VERSION "HNNBNNNYNNNNNNNNNNNNNNNNNNNNNNNNNNNNNNNNNN/4/%%%/4/'%**4NNN///"

NS_ :

BS_:

BU_: AFS Airbag Allrad BAP_Tester BMS_Hybrid Bremse_MK60EC Bremse_MK70MABS Bremse_TRW_EBC450M Bremse_TRW_ESP Daempfer EPB_TRW EPB_TRW_VW411CS FLA Gateway_PQ35 Gateway_Zusatz_EGolf Getriebe_AG6 Getriebe_DQ Getriebe_DQ_Hyb Getriebe_Sele Gurtmikro_PQ35 HCA Ladegeraet_EGolf LEH_Hybrid LH_EPS_APA LH_EPS_ZF_2G LH_EPS_ZF_3G LPG_Interface_Box LWR LWS Magne_Ride Motor_Diesel Motor_EGolf Motor_Hybrid Motor_Otto PDC_PLA Quersperre_VAQ RKA_Plus SAK Waehlhebel Waehlhebel_Sele

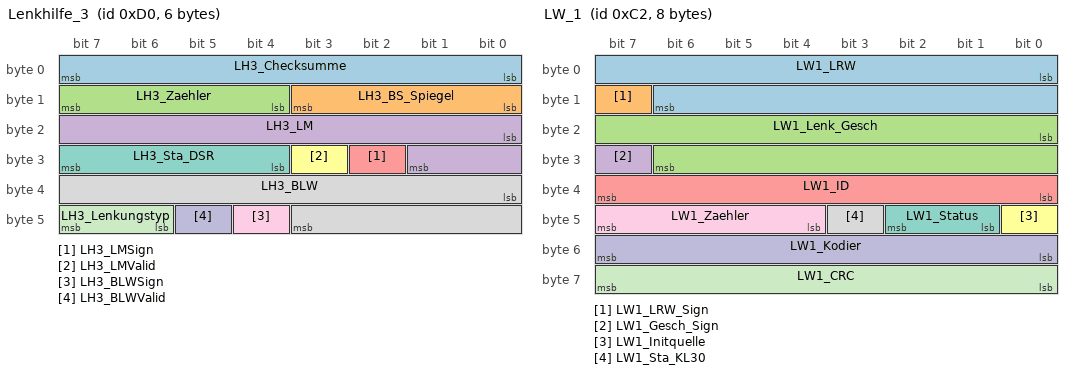
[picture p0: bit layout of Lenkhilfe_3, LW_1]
BO_ 208 Lenkhilfe_3: 6 LH_EPS_APA
 SG_ LH3_Checksumme : 0|8@1+ (1,0) [0|255] ""  Bremse_MK60EC,Bremse_MK70MABS,Bremse_TRW_EBC450M,Bremse_TRW_ESP,Gateway_PQ35,HCA,PDC_PLA
 SG_ LH3_BS_Spiegel : 8|4@1+ (1,0) [0|15] ""  Gateway_PQ35
 SG_ LH3_Zaehler : 12|4@1+ (1,0) [0|15] ""  Bremse_MK60EC,Bremse_MK70MABS,Bremse_TRW_EBC450M,Bremse_TRW_ESP,Gateway_PQ35,HCA,PDC_PLA
 SG_ LH3_LM : 16|10@1+ (0.0147,0) [0|15.0381] "Unit_NewtoMeter"  Bremse_MK60EC,Bremse_MK70MABS,Bremse_TRW_EBC450M,Bremse_TRW_ESP,Gateway_PQ35,HCA,Motor_Diesel,Motor_Otto,PDC_PLA
 SG_ LH3_LMSign : 26|1@1+ (1,0) [0|1] ""  Bremse_MK60EC,Bremse_MK70MABS,Bremse_TRW_EBC450M,Bremse_TRW_ESP,Gateway_PQ35,HCA,Motor_Diesel,Motor_Otto,PDC_PLA
 SG_ LH3_LMValid : 27|1@1+ (1,0) [0|1] ""  Bremse_MK60EC,Bremse_MK70MABS,Bremse_TRW_EBC450M,Bremse_TRW_ESP,Gateway_PQ35,HCA,Motor_Diesel,Motor_Otto,PDC_PLA
 SG_ LH3_Sta_DSR : 28|4@1+ (1,0) [0|15] ""  Bremse_MK60EC,Bremse_MK70MABS,Bremse_TRW_EBC450M,Bremse_TRW_ESP,Gateway_PQ35
 SG_ LH3_BLW : 32|12@1+ (0.15,0) [0|614.25] "Unit_DegreOfArc"  Bremse_MK60EC,Bremse_MK70MABS,Bremse_TRW_EBC450M,Bremse_TRW_ESP,Gateway_PQ35,HCA,PDC_PLA
 SG_ LH3_BLWSign : 44|1@1+ (1,0) [0|1] ""  Bremse_MK60EC,Bremse_MK70MABS,Bremse_TRW_EBC450M,Bremse_TRW_ESP,Gateway_PQ35,HCA,PDC_PLA
 SG_ LH3_BLWValid : 45|1@1+ (1,0) [0|1] ""  Bremse_MK60EC,Bremse_MK70MABS,Bremse_TRW_EBC450M,Bremse_TRW_ESP,Gateway_PQ35,HCA,PDC_PLA
 SG_ LH3_Lenkungstyp : 46|2@1+ (1,0) [0|3] ""  Bremse_MK60EC,Bremse_MK70MABS,Bremse_TRW_EBC450M,Bremse_TRW_ESP,Gateway_PQ35,HCA,PDC_PLA

BO_ 398 mLPG_01: 8 LPG_Interface_Box
 SG_ LPG_01_Reserve : 0|64@1+ (1,0) [0|1.84467440737096E+019] ""  Motor_Otto

BO_ 654 mLPG_02: 8 LPG_Interface_Box
 SG_ LPG_02_Reserve : 0|64@1+ (1,0) [0|1.84467440737096E+019] ""  Motor_Otto

BO_ 655 mLPG_03: 8 LPG_Interface_Box
 SG_ LPG_03_Reserve : 0|64@1+ (1,0) [0|1.84467440737096E+019] ""  Motor_Otto

BO_ 194 LW_1: 8 LH_EPS_ZF_3G
 SG_ LW1_LRW : 0|15@1+ (0.04375,0) [0|1433.55625] "Unit_DegreOfArc"  AFS,Allrad,Bremse_MK60EC,Bremse_TRW_EBC450M,Bremse_TRW_ESP,Daempfer,Gateway_PQ35,Getriebe_DQ,Getriebe_DQ_Hyb,Getriebe_Sele,LH_EPS_APA,LH_EPS_ZF_2G,LWR,Magne_Ride,Motor_Diesel,Motor_Hybrid,Motor_Otto,RKA_Plus
 SG_ LW1_LRW_Sign : 15|1@1+ (1,0) [0|1] ""  AFS,Allrad,Bremse_MK60EC,Bremse_TRW_EBC450M,Bremse_TRW_ESP,Daempfer,Gateway_PQ35,Getriebe_DQ,Getriebe_DQ_Hyb,LH_EPS_APA,LH_EPS_ZF_2G,LWR,Magne_Ride,Motor_Diesel,Motor_Hybrid,Motor_Otto,RKA_Plus
 SG_ LW1_Lenk_Gesch : 16|15@1+ (0.04375,0) [0|1433.55625] "Unit_DegreOfArcPerSecond"  Bremse_MK60EC,Gateway_PQ35,HCA,LH_EPS_APA,LH_EPS_ZF_2G,Magne_Ride
 SG_ LW1_Gesch_Sign : 31|1@1+ (1,0) [0|1] ""  Bremse_MK60EC,Gateway_PQ35,HCA,LH_EPS_APA,LH_EPS_ZF_2G,Magne_Ride
 SG_ LW1_ID : 32|8@1+ (1,0) [0|255] ""  Bremse_MK60EC,Bremse_TRW_EBC450M,Bremse_TRW_ESP,Gateway_PQ35,LH_EPS_APA,LH_EPS_ZF_2G,LWR,Magne_Ride
 SG_ LW1_Initquelle : 40|1@1+ (1,0) [0|1] ""  Bremse_MK60EC,Bremse_TRW_EBC450M,Bremse_TRW_ESP,Gateway_PQ35,LH_EPS_APA,LH_EPS_ZF_2G
 SG_ LW1_Status : 41|2@1+ (1,0) [0|3] ""  AFS,Allrad,Bremse_MK60EC,Bremse_TRW_EBC450M,Bremse_TRW_ESP,Daempfer,Gateway_PQ35,Getriebe_DQ,Getriebe_DQ_Hyb,HCA,LH_EPS_APA,LH_EPS_ZF_2G,LWR,Magne_Ride,Motor_Diesel,Motor_Hybrid,Motor_Otto,RKA_Plus
 SG_ LW1_Sta_KL30 : 43|1@1+ (1,0) [0|1] ""  Bremse_MK60EC,Bremse_TRW_EBC450M,Bremse_TRW_ESP,Gateway_PQ35,LH_EPS_APA,LWR,Magne_Ride
 SG_ LW1_Zaehler : 44|4@1+ (1,0) [0|15] ""  AFS,Bremse_MK60EC,Bremse_TRW_EBC450M,Bremse_TRW_ESP,Daempfer,Gateway_PQ35,HCA,LH_EPS_APA,LWR,Magne_Ride
 SG_ LW1_Kodier : 48|8@1+ (1,0) [0|255] ""  Gateway_PQ35,LH_EPS_APA
 SG_ LW1_CRC : 56|8@1+ (1,0) [0|255] ""  AFS,Bremse_MK60EC,Bremse_TRW_EBC450M,Bremse_TRW_ESP,Daempfer,Gateway_PQ35,HCA,LH_EPS_APA,LWR,Magne_Ride

BO_ 916 mLWR_Zustand: 8 AFS
 SG_ LRZ_Parameter : 0|1@1+ (1,0) [0|1] ""  Gateway_PQ35
 SG_ LRZ_Grundeinst : 1|1@1+ (1,0) [0|1] ""  Gateway_PQ35
 SG_ LRZ_Modus : 2|1@1+ (1,0) [0|1] ""  Gateway_PQ35
 SG_ LRZ_Initlauf : 3|1@1+ (1,0) [0|1] ""  Gateway_PQ35
 SG_ LRZ_Sichere_Pos : 4|1@1+ (1,0) [0|1] ""  Gateway_PQ35
 SG_ LRZ_LampeAFS : 5|1@1+ (1,0) [0|1] ""  Gateway_PQ35
 SG_ LRZ_Fehlerlampe : 6|1@1+ (1,0) [0|1] ""  Gateway_PQ35
 SG_ LRZ_Fehler : 7|1@1+ (1,0) [0|1] ""  Gateway_PQ35
 SG_ LRZ_Einfedg_vo : 8|8@1+ (1,-127) [-127|126] "Unit_MilliMeter"  Bremse_MK60EC,Gateway_PQ35,RKA_Plus
 SG_ LRZ_Einfedg_hi : 16|8@1+ (1,-127) [-127|126] "Unit_MilliMeter"  Bremse_MK60EC,Gateway_PQ35,RKA_Plus
 SG_ LRZ_Stellung : 24|8@1+ (0.4,0) [0|100] "Unit_PerCent"  Gateway_PQ35
 SG_ LRZ_LeistDim : 32|8@1+ (0.4,50) [50|150] "Unit_PerCent"  Gateway_PQ35
 SG_ LRZ_ELF_links : 40|1@1+ (1,0) [0|1] ""  Gateway_PQ35
 SG_ LRZ_ELF_rechts : 41|1@1+ (1,0) [0|1] ""  Gateway_PQ35
 SG_ LRZ_AFSLED_Blink : 42|1@1+ (1,0) [0|1] ""  Gateway_PQ35
 SG_ LRZ_AFSFehlertext : 43|1@1+ (1,0) [0|1] ""  Gateway_PQ35
 SG_ LRZ_Tourist_Fkt : 44|1@1+ (1,0) [0|1] ""  Gateway_PQ35
 SG_ LRZ_Tourist_aktiv : 45|1@1+ (1,0) [0|1] ""  Gateway_PQ35
 SG_ LRZ_AFS_Absch : 46|1@1+ (1,0) [0|1] ""  Gateway_PQ35
 SG_ LRZ_AFS_deaktiv : 47|1@1+ (1,0) [0|1] ""  Gateway_PQ35
 SG_ LRZ_Abbiegelicht_Dimm_Anf : 48|1@1+ (1,0) [0|1] ""  Gateway_PQ35
 SG_ LRZ_Abbiegelicht_li_Anf : 49|1@1+ (1,0) [0|1] ""  Gateway_PQ35
 SG_ LRZ_Abbiegelicht_re_Anf : 50|1@1+ (1,0) [0|1] ""  Gateway_PQ35
 SG_ LRZ_Fernlicht_li_defekt : 51|1@1+ (1,0) [0|1] ""  Gateway_PQ35
 SG_ LRZ_Fernlicht_re_defekt : 52|1@1+ (1,0) [0|1] ""  Gateway_PQ35
 SG_ LRZ_Fernlicht_Status : 53|1@1+ (1,0) [0|1] ""  Gateway_PQ35
 SG_ LRZ_Verfuegbarkeit_GLW : 54|1@1+ (1,0) [0|1] ""  Gateway_PQ35
 SG_ LRZ_Status_adaptive_LV : 55|1@1+ (1,0) [0|1] ""  Gateway_PQ35
 SG_ GLW_Sensor_blockiert : 56|1@1+ (1,0) [0|1] ""  Gateway_PQ35
 SG_ LRZ_Zaehler : 60|4@1+ (1,0) [0|15] ""  Gateway_PQ35

BO_ 1986 mLWS_Init: 4 Bremse_MK60EC
 SG_ LWI_Init_ID : 0|8@1+ (1,0) [0|255] ""  LWS
 SG_ LWI_Codierbytes : 8|24@1+ (1,0) [0|16777215] ""  LWS

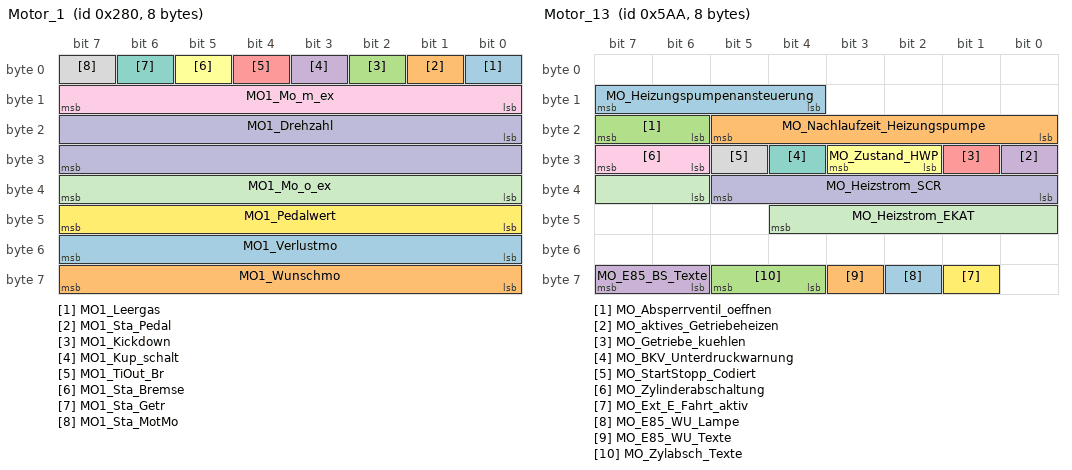
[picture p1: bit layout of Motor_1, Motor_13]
BO_ 640 Motor_1: 8 Motor_Diesel
 SG_ MO1_Leergas : 0|1@1+ (1,0) [0|1] ""  Bremse_MK60EC,Bremse_MK70MABS,Gateway_PQ35,Gateway_Zusatz_EGolf,Getriebe_AG6,Getriebe_DQ,Getriebe_DQ_Hyb
 SG_ MO1_Sta_Pedal : 1|1@1+ (1,0) [0|1] ""  Bremse_MK60EC,Bremse_MK70MABS,Gateway_PQ35,Getriebe_AG6,LH_EPS_APA
 SG_ MO1_Kickdown : 2|1@1+ (1,0) [0|1] ""  Gateway_PQ35,Getriebe_AG6,Getriebe_DQ,Getriebe_DQ_Hyb,Getriebe_Sele
 SG_ MO1_Kup_schalt : 3|1@1+ (1,0) [0|1] ""  Allrad,Bremse_MK60EC,Bremse_MK70MABS,Bremse_TRW_EBC450M,Bremse_TRW_ESP,Gateway_PQ35,PDC_PLA,RKA_Plus
 SG_ MO1_TiOut_Br : 4|1@1+ (1,0) [0|1] ""  Bremse_TRW_EBC450M,Bremse_TRW_ESP,Gateway_PQ35
 SG_ MO1_Sta_Bremse : 5|1@1+ (1,0) [0|1] ""  Bremse_MK60EC,Bremse_MK70MABS,Bremse_TRW_EBC450M,Bremse_TRW_ESP,EPB_TRW,Gateway_PQ35
 SG_ MO1_Sta_Getr : 6|1@1+ (1,0) [0|1] ""  Gateway_PQ35,Getriebe_AG6,Getriebe_DQ,Getriebe_DQ_Hyb
 SG_ MO1_Sta_MotMo : 7|1@1+ (1,0) [0|1] ""  Bremse_MK60EC,Bremse_MK70MABS,Bremse_TRW_EBC450M,Bremse_TRW_ESP,Gateway_PQ35,Getriebe_AG6,Getriebe_DQ,Getriebe_DQ_Hyb,Getriebe_Sele,RKA_Plus
 SG_ MO1_Mo_m_ex : 8|8@1+ (0.39,0) [0|99.06] "Unit_PerCent"  Allrad,Bremse_MK60EC,Bremse_MK70MABS,Bremse_TRW_EBC450M,Bremse_TRW_ESP,EPB_TRW_VW411CS,Gateway_PQ35,Getriebe_AG6,Getriebe_DQ,Getriebe_DQ_Hyb,Getriebe_Sele,Magne_Ride,RKA_Plus,SAK
 SG_ MO1_Drehzahl : 16|16@1+ (0.25,0) [0|16256] "Unit_MinutInver"  AFS,Allrad,BMS_Hybrid,Bremse_MK60EC,Bremse_MK70MABS,Bremse_TRW_EBC450M,Bremse_TRW_ESP,EPB_TRW,EPB_TRW_VW411CS,Gateway_PQ35,Getriebe_AG6,Getriebe_DQ,Getriebe_DQ_Hyb,Getriebe_Sele,HCA,LEH_Hybrid,LH_EPS_APA,LH_EPS_ZF_2G,LH_EPS_ZF_3G,LWR,Magne_Ride,PDC_PLA,RKA_Plus,SAK
 SG_ MO1_Mo_o_ex : 32|8@1+ (0.39,0) [0|99.06] "Unit_PerCent"  Bremse_MK60EC,Bremse_MK70MABS,Bremse_TRW_EBC450M,Bremse_TRW_ESP,Gateway_PQ35,Gateway_Zusatz_EGolf,Getriebe_AG6,Getriebe_DQ,Getriebe_DQ_Hyb
 SG_ MO1_Pedalwert : 40|8@1+ (0.4,0) [0|101.6] "Unit_PerCent"  AFS,Allrad,Bremse_MK60EC,Bremse_MK70MABS,Bremse_TRW_EBC450M,Bremse_TRW_ESP,Gateway_PQ35,Getriebe_AG6,Getriebe_DQ,Getriebe_DQ_Hyb,Getriebe_Sele,LH_EPS_APA,LH_EPS_ZF_2G,LH_EPS_ZF_3G,LWR
 SG_ MO1_Verlustmo : 48|8@1+ (0.39,0) [0|99.06] "Unit_PerCent"  Allrad,Bremse_MK60EC,Bremse_MK70MABS,Bremse_TRW_EBC450M,Bremse_TRW_ESP,EPB_TRW,EPB_TRW_VW411CS,Gateway_PQ35,Gateway_Zusatz_EGolf,Getriebe_AG6,Getriebe_DQ,Getriebe_DQ_Hyb,Getriebe_Sele,Magne_Ride,RKA_Plus,SAK
 SG_ MO1_Wunschmo : 56|8@1+ (0.39,0) [0|99.06] "Unit_PerCent"  Allrad,Bremse_MK60EC,Bremse_MK70MABS,Bremse_TRW_EBC450M,Bremse_TRW_ESP,Daempfer,Gateway_PQ35,Getriebe_DQ,Getriebe_DQ_Hyb,Getriebe_Sele,Magne_Ride

BO_ 1420 Motor_10: 8 Motor_Diesel
 SG_ M10_Anzeige : 0|4@1+ (1,0) [0|15] ""  Gateway_PQ35
 SG_ M10_Anf_Kl75 : 4|1@1+ (1,0) [0|1] ""  Gateway_PQ35
 SG_ MSG_Remotestart_Betrieb : 5|1@1+ (1,0) [0|1] ""  Gateway_PQ35
 SG_ M10_SpannungsAnf : 6|1@1+ (1,0) [0|1] ""  Gateway_PQ35
 SG_ M10_UDruckDyn : 7|1@1+ (1,0) [0|1] ""  Bremse_MK60EC,Gateway_PQ35
 SG_ M10_Status_StSt : 8|2@1+ (1,0) [0|3] ""  Bremse_MK60EC,Bremse_TRW_EBC450M,Bremse_TRW_ESP,EPB_TRW,Gateway_PQ35,Getriebe_DQ,Getriebe_DQ_Hyb,PDC_PLA
 SG_ M10_MotorStopp : 10|1@1+ (1,0) [0|1] ""  AFS,EPB_TRW,Gateway_PQ35,Getriebe_DQ,Getriebe_DQ_Hyb,LWR
 SG_ M10_Wiederstart : 11|1@1+ (1,0) [0|1] ""  AFS,Bremse_MK60EC,Bremse_TRW_EBC450M,Bremse_TRW_ESP,EPB_TRW,EPB_TRW_VW411CS,FLA,Gateway_PQ35,Getriebe_DQ,Getriebe_DQ_Hyb,LWR,PDC_PLA
 SG_ M10_Schubabschaltung : 12|1@1+ (1,0) [0|1] ""  Bremse_MK60EC,Bremse_TRW_EBC450M,Gateway_PQ35
 SG_ M10_Druck_err_gem : 13|1@1+ (1,0) [0|1] ""  Bremse_TRW_EBC450M,Gateway_PQ35
 SG_ M10_Freigabe_Reku : 14|2@1+ (1,0) [0|3] ""  Gateway_PQ35
 SG_ M10_rel_Saugrohrdruck : 16|6@1+ (18,0) [0|1116] "Unit_MilliBar"  Bremse_MK60EC,Bremse_TRW_EBC450M,Gateway_PQ35
 SG_ M10_Fahrbereitschaft : 22|1@1+ (1,0) [0|1] ""  Gateway_PQ35,LH_EPS_ZF_2G,LH_EPS_ZF_3G
 SG_ M10_Hybrid : 23|1@1+ (1,0) [0|1] ""  Gateway_PQ35,LH_EPS_ZF_2G,LH_EPS_ZF_3G
 SG_ M10_EM_aktiv : 24|1@1+ (1,0) [0|1] ""  Gateway_PQ35
 SG_ M10_VM_aktiv : 25|1@1+ (1,0) [0|1] ""  Gateway_PQ35
 SG_ M10_HYB_Bereitlampe : 26|1@1+ (1,0) [0|1] ""  Gateway_PQ35
 SG_ M10_HYB_Warnlampe : 27|1@1+ (1,0) [0|1] ""  Gateway_PQ35
 SG_ M10_HYB_Fehlerlampe : 28|1@1+ (1,0) [0|1] ""  Gateway_PQ35
 SG_ M10_Fehler_HV_Netz : 29|1@1+ (1,0) [0|1] ""  Gateway_PQ35
 SG_ M10_EKlKomLeiRed : 30|2@1+ (1,0) [0|3] ""  Gateway_PQ35
 SG_ M10_Klimadruck : 32|8@1+ (0.2,0) [0|37] "Unit_Bar"  Gateway_PQ35
 SG_ M10_KompAusCode : 40|4@1+ (1,0) [0|15] ""  Gateway_PQ35
 SG_ M10_StartStopp_Fahrerwunsch : 44|2@1+ (1,0) [0|3] ""  Bremse_MK60EC,Bremse_TRW_EBC450M,Bremse_TRW_ESP,Gateway_PQ35,Getriebe_DQ,Getriebe_DQ_Hyb,PDC_PLA
 SG_ M10_Akustik : 46|2@1+ (1,0) [0|3] ""  Gateway_PQ35
 SG_ M10_Text_1_Hybrid : 48|1@1+ (1,0) [0|1] ""  Gateway_PQ35
 SG_ M10_Text_2_Hybrid : 49|1@1+ (1,0) [0|1] ""  Gateway_PQ35
 SG_ M10_Text_3_Hybrid : 50|1@1+ (1,0) [0|1] ""  Gateway_PQ35
 SG_ M10_Text_4_Hybrid : 51|1@1+ (1,0) [0|1] ""  Gateway_PQ35
 SG_ M10_Text_5_Hybrid : 52|1@1+ (1,0) [0|1] ""  Gateway_PQ35
 SG_ M10_Text_6_Hybrid : 53|1@1+ (1,0) [0|1] ""  Gateway_PQ35
 SG_ M10_Text_7_Hybrid : 54|1@1+ (1,0) [0|1] ""  Gateway_PQ35
 SG_ M10_Text_8_Hybrid : 55|1@1+ (1,0) [0|1] ""  Gateway_PQ35
 SG_ M10_ShiftLockLampe : 56|1@1+ (1,0) [0|1] ""  Gateway_PQ35
 SG_ MO_Auth_Aufforderung_WFS : 57|1@1+ (1,0) [0|1] ""  Gateway_PQ35
 SG_ M10_BMSInfo_gue : 58|1@1+ (1,0) [0|1] ""  Gateway_PQ35
 SG_ M10_VentilationReq : 59|1@1+ (1,0) [0|1] ""  Gateway_PQ35
 SG_ M10_BattFanSpd : 60|4@1+ (10,0) [0|100] "Unit_PerCent"  Gateway_PQ35

BO_ 1423 Motor_12: 8 Motor_Diesel
 SG_ MO_ITM_Kuehlmittel_Temp : 0|8@1+ (0.75,-48) [-45.75|143.25] "Unit_DegreCelsi"  Gateway_PQ35
 SG_ M12_E85_Sensor : 8|4@1+ (10,0) [0|100] "Unit_PerCent"  Gateway_PQ35
 SG_ M12_SCR_Anz_Motorstarts : 12|4@1+ (1,0) [0|13] ""  Gateway_PQ35
 SG_ M12_SCR_Reichweite : 16|15@1+ (1,0) [0|32766] "Unit_KiloMeter"  Gateway_PQ35
 SG_ M12_SCR_Warnstufe_1 : 32|1@1+ (1,0) [0|1] ""  Gateway_PQ35
 SG_ M12_SCR_Warnstufe_2 : 33|1@1+ (1,0) [0|1] ""  Gateway_PQ35
 SG_ M12_SCR_Text : 34|3@1+ (1,0) [0|7] ""  Gateway_PQ35
 SG_ M12_Akustik : 37|2@1+ (1,0) [0|3] ""  Gateway_PQ35
 SG_ M12_Luftfilter_Lampe : 39|1@1+ (1,0) [0|1] ""  Gateway_PQ35
 SG_ M12_Kraftstofffilter_Wasser : 40|1@1+ (1,0) [0|1] ""  Gateway_PQ35
 SG_ M12_SCR_Systemfehler : 41|1@1+ (1,0) [0|1] ""  Gateway_PQ35
 SG_ M12_SCR_Inducement : 42|2@1+ (1,0) [0|3] ""  Gateway_PQ35
 SG_ M12_CO2_Faktor : 44|12@1+ (1,0) [1|4094] "Unit_GramPerLiter"  Gateway_PQ35
 SG_ M12_MKB_MUX M : 56|2@1+ (1,0) [0|3] ""  Gateway_PQ35,SAK
 SG_ M12_MKB_01 m0 : 59|5@1+ (1,0) [0|31] ""  Gateway_PQ35
 SG_ M12_MKB_02 m1 : 59|5@1+ (1,0) [0|31] ""  Gateway_PQ35
 SG_ M12_MKB_03 m2 : 59|5@1+ (1,0) [0|31] ""  Gateway_PQ35
 SG_ M12_MKB_04 m3 : 59|5@1+ (1,0) [0|31] ""  Gateway_PQ35,SAK

BO_ 1450 Motor_13: 8 Motor_Diesel
 SG_ MO_Heizungspumpenansteuerung : 12|4@1+ (10,0) [0|100] "Unit_PerCent"  Gateway_PQ35
 SG_ MO_Nachlaufzeit_Heizungspumpe : 16|6@1+ (15,0) [0|945] "Unit_Secon"  Gateway_PQ35
 SG_ MO_Absperrventil_oeffnen : 22|2@1+ (1,0) [0|3] ""  Gateway_PQ35
 SG_ MO_aktives_Getriebeheizen : 24|1@1+ (1,0) [0|1] ""  Gateway_PQ35
 SG_ MO_Getriebe_kuehlen : 25|1@1+ (1,0) [0|1] ""  Gateway_PQ35
 SG_ MO_Zustand_HWP : 26|2@1+ (1,0) [0|3] ""  Gateway_PQ35
 SG_ MO_BKV_Unterdruckwarnung : 28|1@1+ (1,0) [0|1] ""  Gateway_PQ35
 SG_ MO_StartStopp_Codiert : 29|1@1+ (1,0) [0|1] ""  Gateway_PQ35
 SG_ MO_Zylinderabschaltung : 30|2@1+ (1,0) [0|3] ""  Gateway_PQ35
 SG_ MO_Heizstrom_SCR : 32|6@1+ (1,0) [0|62] "Unit_Amper"  Gateway_PQ35
 SG_ MO_Heizstrom_EKAT : 38|7@1+ (1,0) [0|126] "Unit_Amper"  Gateway_PQ35
 SG_ MO_Ext_E_Fahrt_aktiv : 57|1@1+ (1,0) [0|1] ""  Gateway_PQ35
 SG_ MO_E85_WU_Lampe : 58|1@1+ (1,0) [0|1] ""  Gateway_PQ35
 SG_ MO_E85_WU_Texte : 59|1@1+ (1,0) [0|1] ""  Gateway_PQ35
 SG_ MO_Zylabsch_Texte : 60|2@1+ (1,0) [0|3] ""  Gateway_PQ35
 SG_ MO_E85_BS_Texte : 62|2@1+ (1,0) [0|3] ""  Gateway_PQ35

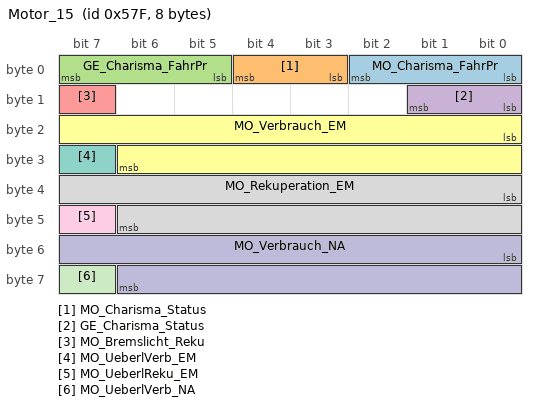
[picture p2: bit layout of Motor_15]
BO_ 1407 Motor_15: 8 Motor_EGolf
 SG_ MO_Charisma_FahrPr : 0|3@1+ (1,0) [0|7] ""  Gateway_Zusatz_EGolf,Ladegeraet_EGolf
 SG_ MO_Charisma_Status : 3|2@1+ (1,0) [0|3] ""  Gateway_Zusatz_EGolf,Ladegeraet_EGolf
 SG_ GE_Charisma_FahrPr : 5|3@1+ (1,0) [0|7] ""  Gateway_Zusatz_EGolf,Ladegeraet_EGolf
 SG_ GE_Charisma_Status : 8|2@1+ (1,0) [0|3] ""  Gateway_Zusatz_EGolf,Ladegeraet_EGolf
 SG_ MO_Bremslicht_Reku : 15|1@1+ (1,0) [0|1] ""  Gateway_Zusatz_EGolf
 SG_ MO_Verbrauch_EM : 16|15@1+ (1,0) [0|32767] "Unit_MilliWattHour"  Gateway_Zusatz_EGolf
 SG_ MO_UeberlVerb_EM : 31|1@1+ (1,0) [0|1] ""  Gateway_Zusatz_EGolf
 SG_ MO_Rekuperation_EM : 32|15@1+ (1,0) [0|32767] "Unit_MilliWattHour"  Gateway_Zusatz_EGolf
 SG_ MO_UeberlReku_EM : 47|1@1+ (1,0) [0|1] ""  Gateway_Zusatz_EGolf
 SG_ MO_Verbrauch_NA : 48|15@1+ (1,0) [0|32767] "Unit_MilliWattHour"  Gateway_Zusatz_EGolf
 SG_ MO_UeberlVerb_NA : 63|1@1+ (1,0) [0|1] ""  Gateway_Zusatz_EGolf

BO_ 648 Motor_2: 8 Motor_Diesel
 SG_ MO2_CAN_Vers m0 : 0|6@1+ (1,0) [0|63] ""  Gateway_PQ35,Getriebe_AG6,Getriebe_DQ,Getriebe_DQ_Hyb,Getriebe_Sele
 SG_ MO2_Motor_Code m1 : 0|6@1+ (1,0) [0|63] ""  Bremse_MK60EC,Bremse_MK70MABS,EPB_TRW,EPB_TRW_VW411CS,Gateway_PQ35,Getriebe_AG6,Getriebe_DQ,Getriebe_DQ_Hyb,Getriebe_Sele,SAK
 SG_ MO2_Getr_Code m2 : 0|6@1+ (1,0) [0|63] ""  Bremse_MK60EC,Bremse_MK70MABS,Bremse_TRW_EBC450M,Bremse_TRW_ESP,EPB_TRW,EPB_TRW_VW411CS,Gateway_PQ35,Getriebe_AG6,Getriebe_DQ,Getriebe_DQ_Hyb,Getriebe_Sele,RKA_Plus
 SG_ MO2_max_Mo m3 : 0|6@1+ (10,0) [0|630] "Unit_NewtoMeter"  Allrad,Bremse_MK60EC,Bremse_TRW_EBC450M,Bremse_TRW_ESP,EPB_TRW,EPB_TRW_VW411CS,Gateway_PQ35,Getriebe_AG6,Getriebe_DQ,Getriebe_DQ_Hyb,Getriebe_Sele,RKA_Plus
 SG_ MO2_Mp_Code M : 6|2@1+ (1,0) [0|3] ""  Allrad,Bremse_MK60EC,Bremse_MK70MABS,Bremse_TRW_EBC450M,Bremse_TRW_ESP,EPB_TRW,EPB_TRW_VW411CS,Gateway_PQ35,Getriebe_AG6,Getriebe_DQ,Getriebe_DQ_Hyb,Getriebe_Sele,RKA_Plus,SAK
 SG_ MO2_Kuehlm_T : 8|8@1+ (0.75,-48) [-47.25|142.5] "Unit_DegreCelsi"  Gateway_PQ35,Getriebe_AG6,Getriebe_DQ,Getriebe_DQ_Hyb,Getriebe_Sele,LEH_Hybrid,Magne_Ride,RKA_Plus
 SG_ MO2_BLS : 16|1@1+ (1,0) [0|1] ""  Allrad,Bremse_TRW_EBC450M,Bremse_TRW_ESP,Daempfer,EPB_TRW,EPB_TRW_VW411CS,Gateway_PQ35,Getriebe_AG6,Getriebe_DQ,Getriebe_DQ_Hyb,Getriebe_Sele,Magne_Ride,PDC_PLA
 SG_ MO2_BTS : 17|1@1+ (1,0) [0|1] ""  Allrad,Gateway_PQ35,Getriebe_AG6,Getriebe_DQ,Getriebe_DQ_Hyb,Getriebe_Sele,Magne_Ride
 SG_ MO2_Sta_Kuehlm : 18|1@1+ (1,0) [0|1] ""  Gateway_PQ35,Getriebe_AG6,Getriebe_DQ,Getriebe_DQ_Hyb,LEH_Hybrid
 SG_ MO2_Sta_Klima : 19|1@1+ (1,0) [0|1] ""  Gateway_PQ35,Getriebe_AG6,Getriebe_DQ,Getriebe_DQ_Hyb
 SG_ MO2_Sta_No_Bet : 20|1@1+ (1,0) [0|1] ""  Bremse_MK60EC,Bremse_MK70MABS,Bremse_TRW_EBC450M,Bremse_TRW_ESP,Gateway_PQ35,Getriebe_DQ,Getriebe_DQ_Hyb
 SG_ MO2_Status_TSK : 21|1@1+ (1,0) [0|1] ""  Gateway_PQ35,Getriebe_DQ
 SG_ MO2_Sta_GRA : 22|2@1+ (1,0) [0|3] ""  Bremse_MK60EC,Bremse_TRW_EBC450M,Bremse_TRW_ESP,Gateway_PQ35,Getriebe_AG6,Getriebe_DQ,Getriebe_DQ_Hyb,Getriebe_Sele,RKA_Plus
 SG_ MO2_Sta_Limiter : 24|2@1+ (1,0) [0|3] ""  Gateway_PQ35
 SG_ MO2_GRAregelt : 26|1@1+ (1,0) [0|1] ""  Gateway_PQ35,Getriebe_DQ,Getriebe_DQ_Hyb
 SG_ MO2_Sport_Error : 27|1@1+ (1,0) [0|1] ""  Gateway_PQ35
 SG_ MO2_OffRoad : 28|1@1+ (1,0) [0|1] ""  Bremse_TRW_EBC450M,Bremse_TRW_ESP,Gateway_PQ35,Getriebe_AG6,Getriebe_DQ,Getriebe_DQ_Hyb
 SG_ MO2_RME_Gehalt : 29|3@1+ (12.5,0) [0|75] "Unit_PerCent"  Gateway_PQ35
 SG_ MO2_GRA_Soll : 32|8@1+ (1.28,0) [0|325.12] "Unit_KiloMeterPerHour"  Gateway_PQ35,Getriebe_AG6,Getriebe_DQ,Getriebe_DQ_Hyb
 SG_ MO2_LL_Solldz : 40|8@1+ (10,0) [0|2540] "Unit_MinutInver"  Bremse_TRW_EBC450M,Bremse_TRW_ESP,Gateway_PQ35,Getriebe_AG6,Getriebe_DQ,Getriebe_DQ_Hyb,Getriebe_Sele
 SG_ MO2_Begr_Mo : 48|8@1+ (0.39,0) [0|99.06] "Unit_PerCent"  Gateway_PQ35,Getriebe_AG6,Getriebe_DQ,Getriebe_DQ_Hyb
 SG_ MO2_Mo_ZWR : 56|8@1+ (0.39,0) [0|99.06] "Unit_PerCent"  Gateway_PQ35,Getriebe_AG6,Getriebe_DQ,Getriebe_DQ_Hyb

BO_ 896 Motor_3: 8 Motor_Diesel
 SG_ MO3_Vorgluehen : 0|1@1+ (1,0) [0|1] ""  Gateway_PQ35,Getriebe_DQ,Getriebe_DQ_Hyb
 SG_ MO3_Prio_Dz : 1|1@1+ (1,0) [0|1] ""  Gateway_PQ35,Getriebe_DQ,Getriebe_DQ_Hyb
 SG_ MO_Schalter_StartStopp : 2|1@1+ (1,0) [0|1] ""  Gateway_PQ35,Getriebe_DQ,Getriebe_DQ_Hyb
 SG_ MO3_Winterprg : 3|1@1+ (1,0) [0|1] ""  Gateway_PQ35,Getriebe_AG6,Getriebe_DQ,Getriebe_DQ_Hyb
 SG_ MO3_Sta_Pedal : 4|1@1+ (1,0) [0|1] ""  EPB_TRW,EPB_TRW_VW411CS,Gateway_PQ35,Getriebe_DQ,Getriebe_DQ_Hyb
 SG_ MO3_Sta_FPG M : 5|1@1+ (1,0) [0|1] ""  Bremse_MK60EC,Gateway_PQ35
 SG_ MO3_Sign_FPG m1 : 6|1@1+ (1,0) [0|1] ""  Bremse_MK60EC,Gateway_PQ35
 SG_ MO3_Sta_Temp : 7|1@1+ (1,0) [0|1] ""  Gateway_PQ35,Getriebe_DQ,Getriebe_DQ_Hyb
 SG_ MO3_Aussentemp : 8|8@1+ (0.75,-48) [-48|142.5] "Unit_DegreCelsi"  Gateway_PQ35,Getriebe_DQ,Getriebe_DQ_Hyb,Magne_Ride
 SG_ MO3_Pedalwert : 16|8@1+ (0.4,0) [0|101.6] "Unit_PerCent"  Bremse_MK60EC,Bremse_TRW_EBC450M,Bremse_TRW_ESP,EPB_TRW,EPB_TRW_VW411CS,Gateway_PQ35,Getriebe_AG6,Getriebe_DQ,Getriebe_DQ_Hyb,HCA,Magne_Ride
 SG_ MO3_Rad_Wu_Mo : 24|12@1+ (0.39,0) [0|1596.66] "Unit_PerCent"  Gateway_PQ35,Getriebe_DQ,Getriebe_DQ_Hyb
 SG_ MO3_Vorz_RadWu : 36|1@1+ (1,0) [0|1] ""  Gateway_PQ35,Getriebe_DQ,Getriebe_DQ_Hyb
 SG_ MO3_Freigabe_Segeln : 37|1@1+ (1,0) [0|1] ""  Gateway_PQ35,Getriebe_DQ,Getriebe_DQ_Hyb
 SG_ MO3_Dz_Beeinfl : 40|8@1+ (0.39,0) [0|99.45] "Unit_PerCent"  Gateway_PQ35
 SG_ MO3_WunschDz : 48|8@1+ (25,0) [0|6350] "Unit_MinutInver"  Gateway_PQ35,Getriebe_DQ,Getriebe_DQ_Hyb
 SG_ MO3_DKW m0 : 56|8@1+ (0.4,0) [0|101.6] "Unit_PerCent"  Gateway_PQ35
 SG_ MO3_FPGradient m1 : 56|8@1+ (25,0) [0|6350] "Unit_PerCentPerSecon"  Bremse_MK60EC,Gateway_PQ35

BO_ 1152 Motor_5: 8 Motor_Diesel
 SG_ MO5_max_Moment m0 : 0|6@1+ (10,0) [0|630] "Unit_NewtoMeter"  Gateway_PQ35
 SG_ MO5_Drehzahl m1 : 0|6@1+ (100,0) [0|6300] "Unit_MinutInver"  Gateway_PQ35
 SG_ MO5_Motortyp m2 : 0|6@1+ (1,0) [0|63] ""  Allrad,Bremse_MK60EC,Bremse_TRW_EBC450M,Bremse_TRW_ESP,Gateway_PQ35,RKA_Plus
 SG_ MO5_Abgastyp m3 : 0|1@1+ (1,0) [0|1] ""  BMS_Hybrid,Gateway_PQ35,LEH_Hybrid
 SG_ MO5_Abgastyp2 m3 : 1|1@1+ (1,0) [0|1] ""  BMS_Hybrid,Gateway_PQ35,LEH_Hybrid
 SG_ MO5_Abgastyp3 m3 : 2|1@1+ (1,0) [0|1] ""  Gateway_PQ35
 SG_ OBD_Kaltstart_Denominator m3 : 3|1@1+ (1,0) [0|1] ""  BMS_Hybrid,Gateway_PQ35,LEH_Hybrid
 SG_ OBD_Minimum_Trip m3 : 4|1@1+ (1,0) [0|1] ""  BMS_Hybrid,Gateway_PQ35,Getriebe_DQ,Getriebe_DQ_Hyb,LEH_Hybrid
 SG_ MO5_DPF_reg m3 : 5|1@1+ (1,0) [0|1] ""  Gateway_PQ35
 SG_ MO5_Mp_Code M : 6|2@1+ (1,0) [0|3] ""  Allrad,BMS_Hybrid,Bremse_MK60EC,Bremse_TRW_EBC450M,Bremse_TRW_ESP,Gateway_PQ35,Getriebe_DQ,Getriebe_DQ_Hyb,LEH_Hybrid,RKA_Plus
 SG_ MO5_Vorgluehen : 9|1@1+ (1,0) [0|1] ""  Gateway_PQ35
 SG_ MO5_E_Gas : 10|1@1+ (1,0) [0|1] ""  Gateway_PQ35
 SG_ MO5_OBD_2 : 11|1@1+ (1,0) [0|1] ""  Gateway_PQ35
 SG_ MO5_Heissl : 12|1@1+ (1,0) [0|1] ""  Gateway_PQ35
 SG_ MO5_KlimaKompr : 13|1@1+ (1,0) [0|1] ""  Gateway_PQ35
 SG_ MO5_Feld_kuehl : 14|1@1+ (1,0) [0|1] ""  Gateway_PQ35
 SG_ MO5_KliKo_Red : 15|1@1+ (1,0) [0|1] ""  Gateway_PQ35
 SG_ MO5_Verbrauch : 16|15@1+ (1,0) [0|32767] "Unit_MicroLiter"  Gateway_PQ35
 SG_ MO5_UeberlVerb : 31|1@1+ (1,0) [0|1] ""  Gateway_PQ35
 SG_ MO5_Luefter : 32|8@1+ (0.4,0) [0|101.6] "Unit_PerCent"  Gateway_PQ35,Getriebe_DQ,Getriebe_DQ_Hyb
 SG_ MO5_HLeuchte : 40|1@1+ (1,0) [0|1] ""  Gateway_PQ35
 SG_ MO5_PartikelLamp : 41|1@1+ (1,0) [0|1] ""  Gateway_PQ35
 SG_ MO5_Sta_BKU : 42|1@1+ (1,0) [0|1] ""  Gateway_PQ35
 SG_ MO5_TypStartSteu : 43|1@1+ (1,0) [0|1] ""  Gateway_PQ35
 SG_ MO5_TDE_Lampe : 44|1@1+ (1,0) [0|1] ""  Gateway_PQ35
 SG_ MO5_TDE_Text : 45|1@1+ (1,0) [0|1] ""  Gateway_PQ35
 SG_ MO5_DZM_Daempf : 46|1@1+ (1,0) [0|1] ""  Gateway_PQ35
 SG_ MO5_Interlock : 47|1@1+ (1,0) [0|1] ""  EPB_TRW_VW411CS,Gateway_PQ35
 SG_ MO5_Start : 48|1@1+ (1,0) [0|1] ""  Gateway_PQ35
 SG_ MO5_Anlasser : 49|1@1+ (1,0) [0|1] ""  Gateway_PQ35
 SG_ MO5_GRA_Hauptsch : 50|1@1+ (1,0) [0|1] ""  Gateway_PQ35
 SG_ MO5_Momente : 51|1@1+ (1,0) [0|1] ""  Bremse_MK60EC,Bremse_MK70MABS,EPB_TRW_VW411CS,Gateway_PQ35,Getriebe_AG6,Getriebe_DQ,Getriebe_DQ_Hyb,RKA_Plus
 SG_ MO5_Motortext1 : 52|1@1+ (1,0) [0|1] ""  Gateway_PQ35
 SG_ MO5_Motortext2 : 53|1@1+ (1,0) [0|1] ""  Gateway_PQ35
 SG_ MO5_Motortext3 : 54|1@1+ (1,0) [0|1] ""  Gateway_PQ35
 SG_ MO5_Motortext4 : 55|1@1+ (1,0) [0|1] ""  Gateway_PQ35
 SG_ MO5_Checksumme : 56|8@1+ (1,0) [0|255] ""  Bremse_MK60EC,Bremse_MK70MABS,EPB_TRW_VW411CS,Gateway_PQ35

BO_TX_BU_ 208 : LH_EPS_APA,LH_EPS_ZF_2G,LH_EPS_ZF_3G;
BO_TX_BU_ 194 : LH_EPS_ZF_3G,LWS;
BO_TX_BU_ 916 : AFS,LWR;
BO_TX_BU_ 1986 : Bremse_MK60EC,Bremse_TRW_EBC450M,Bremse_TRW_ESP;
BO_TX_BU_ 640 : Motor_Diesel,Motor_EGolf,Motor_Hybrid,Motor_Otto;
BO_TX_BU_ 1420 : Motor_Diesel,Motor_EGolf,Motor_Hybrid,Motor_Otto;
BO_TX_BU_ 1423 : Motor_Diesel,Motor_EGolf,Motor_Hybrid,Motor_Otto;
BO_TX_BU_ 1450 : Motor_Diesel,Motor_EGolf,Motor_Hybrid,Motor_Otto;
BO_TX_BU_ 648 : Motor_Diesel,Motor_EGolf,Motor_Hybrid,Motor_Otto;
BO_TX_BU_ 896 : Motor_Diesel,Motor_EGolf,Motor_Hybrid,Motor_Otto;
BO_TX_BU_ 1152 : Motor_Diesel,Motor_EGolf,Motor_Hybrid,Motor_Otto;
CM_ SG_ 208 LH3_Checksumme "Prüfsumme mit Endwert 0x0, Definition im CAN Lastenheft (HS-CAN V4.2a, LS-CAN V1.42)";
CM_ SG_ 208 LH3_BS_Spiegel "Der Botschaftsspiegel reflektiert die zuletzt empfangene Botschaft der mBremse_9, d. h. der zuletzt empfangene Wert des Botschaftszählers aus der mBremse_9 wird zurückgesendet";
CM_ SG_ 208 LH3_Zaehler "Freilaufender Botschaftszähler, dient als Quelle des Botschaftsspiegels in Lenkhilfe_3 Botschaft
Botschaftszähler (Lenkhilfe 3)";
CM_ SG_ 208 LH3_LM "Gibt das durch den Momentensensor detektiertes Lenkhandmoment (Absolutmoment) aus";
CM_ SG_ 208 LH3_LMSign "Vorzeichen Lenkhandmoment";
CM_ SG_ 208 LH3_LMValid "Gültigkeit der Signale Lenkhandmoment und Vorzeichen Lenkhandmoment";
CM_ SG_ 208 LH3_Sta_DSR "0 DSR deaktiviert
1 DSR Anforderung nicht ausführbar (ESP Fehlerstatus)
2 Kommunikation zum ESP-SG gestört
3 EPS bzgl. DSR funktionsbereit
4 DSR Anforderung abgewiesen
5 externer Momenteneingriff aktiv
6 externer Lenkwinkeleingriff aktiv
7 externer";
CM_ SG_ 208 LH3_BLW "Berechneter Lenkradwinkel (BLW)
Ausgabe des berechneten Lenkwinkel mit Geradeauslaufkorrektur aus der Position des Lenkmotors (Absolutwert)
(nur zur festgelegten Nutzung im ABS, ESP, PLA, HCA freigegeben)";
CM_ SG_ 208 LH3_BLWSign "Vorzeichen 'Berechneter Lenkwinkel'";
CM_ SG_ 208 LH3_BLWValid "Gültigkeit der Signale 'Berechneter Lenkwinkel' (BLW und BLW Sign)
Beim Typ CEPS gibt es keinen definierten Zeitraum, in dem das Signal gültig ist.";
CM_ SG_ 208 LH3_Lenkungstyp "0 Elektrik Power Steering mit DSR1 (Version ab KW22/05)
1 Achsparalleler Antrieb
2 Active Dynamik Steering (Audi) / CEPS (VW120)
3 Elektrik Power Steering mit DSR2 (Version ab KW22/07)";
CM_ SG_ 194 LW1_LRW "Low Byte 1, High Byte 2
0 geradeaus
7FFFH am Anschlag
Lenkradwinkel";
CM_ SG_ 194 LW1_LRW_Sign "positiver Lenkradwinkel: nach links
negativer Lenkradwinkel: nach rechts
Lenkradwinkel_Sign";
CM_ SG_ 194 LW1_Lenk_Gesch "Low Byte 3, High Byte 4
0 keine Bewegung
7FFFH maximale Geschwindigkeit
Lenkradwinkel-Geschwindigkeit";
CM_ SG_ 194 LW1_Gesch_Sign "Lenkradwinkel-Geschwindigkeit_Sign";
CM_ SG_ 194 LW1_ID "Nullpunktabgleich des LWS noch nicht durchgeführt
Sonstige Fzg (außer PQ35): ESP-Steuergerät übergibt beim Nullpunktabgleich eine ID-Nummer an den LWS. Die Zufallszahl wird nach erfolgreichem Nullpunktabgleich als Lenkwinkel_ID übernommen
PQ35/46: Bit 7";
CM_ SG_ 194 LW1_Initquelle "Lenkwinkelsensor wird über Raddrehzahl oder 'Geradeausfahrt'-Bit der EPS initialisiert
Quelle für Init";
CM_ SG_ 194 LW1_Status "'o.k.': absoluter Lenkradwinkel und Lenkradwinkelgeschwindigkeit werden korrekt berechnet
'no init': Sensor ist nicht initialisiert, absoluter Lenkrad-winkel kann noch nicht berechnet werden, kein Fehler
'sporadischer Fehler': Sensor ist bis zum Ausscha";
CM_ SG_ 194 LW1_Sta_KL30 "(z.Zt. nur Kostal-Sensor)
Sensor ist nach KL30-Ausfall nicht initialisiert, absoluter Lenkradwinkel kann noch nicht berechnet werden, Segmenterkennung durch Auswertung der Radsignale
Status_KL30_Ausfall";
CM_ SG_ 194 LW1_Zaehler "freilaufender Botschaftszähler";
CM_ SG_ 194 LW1_Kodier "Der separate LWS gibt Kodierdaten aus: Multiplex-Ausgabe der 3 Kodierbytes abh. Vom Zähler in Byte 6 (Bit 7 oder 6 ungleich 0)";
CM_ SG_ 194 LW1_CRC "Definition nach Lastenheft 'Übertragungsmodul für ESP':
Einerkomplement des Ergebnisses der 8 Bit Addition von Byte 1, 2, 3, 4 und 6.
Prüfsumme (Lenkwinkel 1)";
CM_ SG_ 916 LRZ_Parameter "Parametrisierung wählt die Fahrzeugvariante und die AFS-Variante aus
LWR und AFS Parametrisierung";
CM_ SG_ 916 LRZ_Grundeinst "Grundeinstellung des Abblendlichtes am Lichteinstellkasten im Service oder Bandende mit Tester erfolgt! (auch für das dynamische Kurvenlicht)
LWR und AFS Grundeinstellung";
CM_ SG_ 916 LRZ_Modus "schnelle oder langsame Regelart der LWR
LWR-Modus";
CM_ SG_ 916 LRZ_Initlauf "Initialisierungslauf der Schrittmotoren, erfolgt defaultmäßig beim Motorstart
LWR Initialisierungslauf";
CM_ SG_ 916 LRZ_Sichere_Pos "LWR Sicherheitsposition beider Scheinwerfers";
CM_ SG_ 916 LRZ_LampeAFS "Status der AFS Fehlerlampe: aktuell anliegender Fehlerzustand des dynamischen oder statischen Kurvenlichts";
CM_ SG_ 916 LRZ_Fehlerlampe "Status der Fehlerlampe: aktuell anliegender Fehlerzustand";
CM_ SG_ 916 LRZ_Fehler "Bei gesetztem Bit ist mindestens ein Kundendienstfehler eingetragen (auch sporadische bzw. passive Fehler).
LWR und AFS Fehlerspeichereintrag";
CM_ SG_ 916 LRZ_Einfedg_vo "aktueller Höhensensorwert vorne (bei PQ35/46 links)
(oder bei Luftfederung aus der Niveau 2-Botschaft gespiegelt)
Einfederung Karosse vorn";
CM_ SG_ 916 LRZ_Einfedg_hi "aktueller Höhensensorwert hinten (bei PQ35/46 links)
(oder bei Luftfederung aus der Niveau 2-Botschaft gespiegelt)
Einfederung Karosse hinten";
CM_ SG_ 916 LRZ_Stellung "Position des Aktuators in Prozent des maximalen Stellweges; vor dem Initialisierungslauf (z.Zt. Motorstart) wird der Initwert ausgegeben:
0% : tiefste Stellung (auf Block) des Schrittmotors
100% : maximaler Verstellweg des Schrittmotors (nicht die Grenz";
CM_ SG_ 916 LRZ_LeistDim "100% entsprechen 35 Watt
Die Last schaltet nur das ILM
Sollwert Leistungsdimmung EVG (links und rechts)";
CM_ SG_ 916 LRZ_ELF_links "Bei aktivierter Ersatzlichtfunktion wird das Abblendlicht ausgeschaltet und eine Ersatzlichtquelle eingeschaltet
Ersatzlichtfunktion links";
CM_ SG_ 916 LRZ_ELF_rechts "Bei aktivierter Ersatzlichtfunktion wird das Abblendlicht ausgeschaltet und eine Ersatzlichtquelle eingeschaltet
Ersatzlichtfunktion rechts";
CM_ SG_ 916 LRZ_AFSLED_Blink "Lampe soll im Warnfall mit 1Hz blinken, wenn das Bit gesetzt ist (z. Zt. nur bei VW)
AFS-LED Blinkmode";
CM_ SG_ 916 LRZ_AFSFehlertext "Fehlertext wird im Kombi angezeigt (z. Zt. nur bei VW)
AFS-Fehlertext";
CM_ SG_ 916 LRZ_Tourist_Fkt "Touristenfunktion wird vom AFS Steuergerät unterstützt.
0: Touristenfkt. nicht unterstützt
1: Touristenfunktion unterstützt";
CM_ SG_ 916 LRZ_Tourist_aktiv "Touristenfunktion 'ein' heißt Absenken der HGD und Schwenken deaktivieren wurde von AFS- Steuergerät umgesetzt.
0: Touristenfunktion deaktiviert
1: Touristenfunktion aktiviert
Touristenfunktion ein /aus";
CM_ SG_ 916 LRZ_AFS_Absch "AFS Deaktivierung wird vom AFS Steuergerät unterstützt.
Funktion auch während der Fahrt bedienbar.
0: keine AFS Deaktivierung über Kombi möglich
1: AFS unterstützt Deaktivierung über Kombi";
CM_ SG_ 916 LRZ_AFS_deaktiv "AFS deaktiviert heißt kein Schwenken und Standard-LWR also Anhebung in besonderen Geschwindigkeitsbereichen.
0: AFS aktiviert
1: AFS deaktiviert
AFS ein / aus";
CM_ SG_ 916 LRZ_Abbiegelicht_Dimm_Anf "Beschreibt ob das Abbiegelicht gedimmt oder hart einschalten werden soll. Dimmkurve ist im Empfänger hinterlegt.";
CM_ SG_ 916 LRZ_Abbiegelicht_li_Anf "Anforderung das Abbiegelicht links einzuschalten";
CM_ SG_ 916 LRZ_Abbiegelicht_re_Anf "Anforderung das Abbiegelicht rechts einzuschalten";
CM_ SG_ 916 LRZ_Fernlicht_li_defekt "Beschreibt ob das Fernlicht des linken Scheinwerfers defekt ist";
CM_ SG_ 916 LRZ_Fernlicht_re_defekt "Beschreibt ob das Fernlicht des rechten Scheinwerfers defekt ist";
CM_ SG_ 916 LRZ_Fernlicht_Status "Beschreibt ob das Fernlicht aktiv oder inaktiv ist";
CM_ SG_ 916 LRZ_Verfuegbarkeit_GLW "Beschreibt die Verfügbarkeit der Gleitenden Leuchtweite / Fernlichtassistenz - Verfügbarkeit bedeutet, dass die Funktion Gleitende Leuchtweite möglich ist";
CM_ SG_ 916 LRZ_Status_adaptive_LV "Gibt den Status der adaptiven Lichtverteilung an";
CM_ SG_ 916 GLW_Sensor_blockiert "Das Signal zeigt an, dass die Kamera zur Zeit keine Sicht hat.
Verhalten wie Fernlichtassistent.
Weiterleitung des Signals vom BCM an das KOMBI";
CM_ SG_ 916 LRZ_Zaehler "Botschaftszähler der LWR-Zustandsbotschaft wird zyklisch beim Absenden jeder Botschaft um 1 inkrementiert";
CM_ SG_ 1986 LWI_Init_ID "ID für LWS_Init";
CM_ SG_ 1986 LWI_Codierbytes "Codierbytes";
CM_ SG_ 640 MO1_Leergas "Fahrpedal-Leergasschalter, Leergasinfo aus Fahrpedalwert oder Leerlaufschalter bei Drosselklappe (wird zur Freigabe der MSR-Funktion im ABS verwendet)";
CM_ SG_ 640 MO1_Sta_Pedal "Ersatzwert aus Modellrechnung oder Fehlerwert in Byte 6, Leergas- oder Kickdown-Info können betroffen sein
Fahrpedalwert ungenau (Motor 1)";
CM_ SG_ 640 MO1_Kickdown "0 kann für nicht verbaut stehen, bei Doppelanalogpedalwertgeber ggfs. errechneter Wert
Kickdownschalter";
CM_ SG_ 640 MO1_Kup_schalt "nur Handschalter
aktiv, wenn Schalter verbaut, sonst konstant auf 0 gesetzt
Bit wird gesetzt, wenn Kupplungspedal nicht betätigt wird (Kupplungsschalter hoch), Triebstrang kann noch eingekuppelt sein
Kupplungsschalter";
CM_ SG_ 640 MO1_TiOut_Br "500 msec Time Out auf Bremsen-Botschaft ist >= 1 mal aufgelaufen, Löschen des Bits nach Neustart (Kl.15)";
CM_ SG_ 640 MO1_Sta_Bremse "Eingriffswunsch (ASR oder MSR) vom Bremsen-Steuergerät (ABS) kann nicht ausgeführt werden, weil im Motorsteuergerät ein statischer Fehler vorliegt oder die Funktion durch die Applikation abgeschaltet ist
Fehlerstatus Brems-Momenteneingriff";
CM_ SG_ 640 MO1_Sta_Getr "Eingriffswunsch vom Getriebe-Steuergerät kann ggfs. nicht oder nicht vollständig ausgeführt werden, weil entweder im Motorsteuergerät ein statischer (!) Fehler vorliegt oder die Momentenanforderung des Getriebe-Steuergerätes aus Sicht des Motorsteuergerät";
CM_ SG_ 640 MO1_Sta_MotMo "ungenaue Momentenangaben, weil die Momente aus Ersatzwerten berechnet wurden (z.B. HFM ausgefallen)";
CM_ SG_ 640 MO1_Mo_m_ex "'indiziertes Motormoment', d.h. idealisiertes berechnetes Moment ohne mechanische Verluste, aber mit externen Eingriffen

Hybrid:
Es sind drei Fälle zu unterscheiden:
1. offene K0: von positiven EM-Momenten (egal ob Eingriffs- oder Fahrmoment) werden ";
CM_ SG_ 640 MO1_Drehzahl "Low Byte 3, High Byte 4; es wird der letzte aktuelle Meßwert gesendet, d.h. die Zeit für das letzte Arbeitsspiel (180 Grad KW beim 4 Zylinder) wird herangezogen; der Fehlerwert wird gesendet, wenn das Motor-steuergerät keine plausible Drehzahlinformation ";
CM_ SG_ 640 MO1_Mo_o_ex "indiziertes Motormoment ohne externe Eingriffe (ASR, MSR, Getriebe,..), aber inklusive integrierter GRA

Hybrid:
Es sind drei Fälle zu unterscheiden:
1. offene K0: positive EM-Momente (nur Fahrmomente)
2. schlupfende K0: zu positiven EM-Momenten (nur";
CM_ SG_ 640 MO1_Pedalwert "Bei E-Gas wird hier der Fahrpedalwert ausgegeben
Maximum aus Rohsignal, gefiltertem Wert (TDI) und virtuellem Wert aus Kennfeld (bei aktiver integrierter GRA), Wert wird bei Doppelpotis auch bei einer defekten Poti-Spur ausgegeben, genutzter Wertebereich";
CM_ SG_ 640 MO1_Verlustmo "beinhaltet z. Zt. Reibung vom Motor und Klimakompressor, beim TDI z.T. auch die Generatorverluste

Hybrid (Signal 'Summe negative Momente'):
negative Fahr-EM-Momente (Rekuperationsanteil) sowie ein negativer Momentenbeitrag durch negativ schlupfende K0";
CM_ SG_ 640 MO1_Wunschmo "Moment vor Filter, nutzbar zur Zug- / Schuberkennung beim Getriebe (beim Diesel identisch mit innerem Moment, ohne externe Eingriffe)

Hybrid:
Moment vor Filter inkl. K0-Beitrag bei negativ schlupfender K0.
Zur Verwendung in Schaltstrategie: Fahrerwun";
CM_ SG_ 1420 M10_Anzeige "Anzeige Start/Stopp_Automatikstart

0 = keine Anzeige

Start/Stopp:
1 = Motor in Stoppbetrieb (Symbol 'A')
2 = Systemfehler Start-Stopp (VW ID_TXT_2022.1)
3 = Motor manuell starten (VW ID_TXT_2022.0)
5 = Temporär nicht verfügbar (Symbol 'durchgest";
CM_ SG_ 1420 M10_Anf_Kl75 "Anforderung an das BSG/BCM bei Konzepten mit Startersteuerung durch das MSG: Beim Erststart fordert das MSG mit diesem Signal das Ausschalten der KL75-Verbraucher an. (Bei einem Wiederstart innerhalb der Start-Stopp-Funktionalität bleib das Signal gesetzt";
CM_ SG_ 1420 MSG_Remotestart_Betrieb "Wenn das MSG für den Remotestartbetrieb bereit ist, wird dieses Signal gesendet und wird solange 'aktiv' gesendet wie das MSG den Remotestart unterstützt.  ";
CM_ SG_ 1420 M10_SpannungsAnf "Forderung des Motor-SGs zur Spannungsanhebung";
CM_ SG_ 1420 M10_UDruckDyn "0 = Der Saugrohrunterdruckwert überstieg mind. einmal mehr als 50mbar (in Richtung Vakuum), bezogen auf den höchsten Saugrohrunterdruckwert aus der aktuellen und letzen CAN-Ausgabe (siehe mMotor_10, Byte 3, Bit 5..0).
1 = Der Saugrohrunterdruckwert war i";
CM_ SG_ 1420 M10_Status_StSt "Systemstatus des Start-Stopp-Koordinators
0 = System in diesem Kl15 Zyklus nicht verfügbar (Sicherheitsabschaltung, Sensorfehler erkannt, Funktion nicht implementiert)
1 = Abschaltung über Hauptschalter
2 = System aktiv, Motorlauf nicht notwendig (Frei";
CM_ SG_ 1420 M10_MotorStopp "Motor-Stopp durch Start-Stopp-Koordinator. Das Signal wird nur bei einem Motorstopp durch den Start-Stopp-Koordinator gesetzt. Bei Abwürgen des Motors oder nach Abstellen des Motors über KL15 (Nachlauf) bleibt das Signal inaktiv.
Stopp-Modus aktiv wird e";
CM_ SG_ 1420 M10_Wiederstart "Motorwiederstart durch Start-Stopp-Koordinator. 'Wiederstart aktiv' wird vom Koordinator gesetzt sobald der Wiederstart angetriggert wird und bleibt bis zum Startende gesetzt. (bleibt beim Erststart 0)";
CM_ SG_ 1420 M10_Schubabschaltung "ESP plausibilisiert Unterdrucksensor nur bei aktiver Schubabschaltung
Schubabschaltung";
CM_ SG_ 1420 M10_Druck_err_gem "0: mind. eine Modellrechnung wird zur Berechnung des relativen Saugrohrdrucks (Byte 3, Bit 5..0) herangezogen.
1: Relativer Saugrohrdruck wird ausschließlich über Messgrößen bestimmt.
Rel. Saugrohrdruck errechnet/gemessen";
CM_ SG_ 1420 M10_Freigabe_Reku "Empfehlung des Motor-SG's zur Spannungsabsenkung/-anhebung für den Rekuperationsbetrieb (PQ25, PQ35/46, AU210, C6, AU716, Touareg GP, Hybrid-Projekte)
Freigabe Rekuperation";
CM_ SG_ 1420 M10_rel_Saugrohrdruck "Der Wert gibt an, um wieviel mbar der Saugrohrdruck unterhalb des Umgebungsdrucks liegt. Überdruck im Saugrohr wird nicht ausgegeben.
0: Saugrohrdruck >= Umgebungsdruck
Relativer Saugrohrdruck";
CM_ SG_ 1420 M10_Fahrbereitschaft "Signal steuert u.a. in der Lenkhilfe zusammen mit weiteren Informationen den Modewechsel in den 'Drivemode'
Fahrbereitschaft";
CM_ SG_ 1420 M10_Hybrid "Anhand dieses Signals plausibilisiert die Lenkhilfe das Bit Fahrbereitschaft
Hybrid";
CM_ SG_ 1420 M10_EM_aktiv "für Kombiinstrument zur Steuerung der Anzeigen und Auswertung (z.B. Reichweite, DÖW usw.)
E-Motor aktiv";
CM_ SG_ 1420 M10_VM_aktiv "für Kombiinstrument zur Steuerung der Anzeigen und Auswertung (z.B. Reichweite, DÖW usw.)
V-Motor aktiv";
CM_ SG_ 1420 M10_HYB_Bereitlampe "grüne Anzeige im Kombiinstrument zur Signalisierung der Bereitschaft des Hybridsystems
Lampe Hybrid-Bereitschaft";
CM_ SG_ 1420 M10_HYB_Warnlampe "gelbe Anzeige im Kombiinstrument zur Signalisierung der Warnmeldung des Hybridsystems
Lampe Hybrid-Warnung";
CM_ SG_ 1420 M10_HYB_Fehlerlampe "rote Anzeige im Kombiinstrument zur Signalisierung der Sicherheitsmeldung des Hybridsystems
Lampe Hybrid-Fehler";
CM_ SG_ 1420 M10_Fehler_HV_Netz "Im HV-Bordnetz ist fehlerbedingt kein generatorischer Betrieb möglich. Das 12V-Bordnetz wird über den DC/DC-Wandler allein aus der Traktionsbatterie gespeist. Um diesen Zustand möglichst lange aufrechterhalten zu können, sollten Komfort-Verbraucher abgesc";
CM_ SG_ 1420 M10_EKlKomLeiRed "Anforderung an die Klimasteuerung, die Leistungsaufnahme des E-Kompressors bei schlechtem SOC und in bestimmten Fahrsituationen zu begrenzen.
(Das bereits bestehende Signal 'Klimakompressor aus' Motor5, Byte2, Bit5 als stets umzusetzende Anforderung blei";
CM_ SG_ 1420 M10_Klimadruck "Drucksensor am Motor-SG (China Modell X/Y)";
CM_ SG_ 1420 M10_KompAusCode "Abschaltbedingungen im Motor für den Klimakompressor (China Modell X/Y)
Kompressor-Aus-Code";
CM_ SG_ 1420 M10_StartStopp_Fahrerwunsch "Fahreraktivität Start/Stopp";
CM_ SG_ 1420 M10_Akustik "Anforderung einer Akustikwarnung im Kombi (durch Hybrid- oder Start/Stopp-Koordinator)
0 = keine Akustik
1 = Akustik 1 (Gong 1000 bei VW)
2 = Akustik 2 (3xSummer2000 bei VW)
3 = frei";
CM_ SG_ 1420 M10_Text_1_Hybrid "Text 1 (ID_TXT_1024.1): Fehler Hybridsystem Werkstatt aufsuchen (Kategorie 1)";
CM_ SG_ 1420 M10_Text_2_Hybrid "Text 2 (ID_TXT_1025.1): Fehler Hybridsystem Werkstatt aufsuchen (Kategorie 2)";
CM_ SG_ 1420 M10_Text_3_Hybrid "Text 3 (ID_TXT_1025.2): Warten. HV-Batterie wird geladen. Bordbuch";
CM_ SG_ 1420 M10_Text_4_Hybrid "Text 4 (ID_TXT_1025.3): Bordnetzunterspannung Bordbuch";
CM_ SG_ 1420 M10_Text_5_Hybrid "Text 5 (ID_TXT_1025.4): Anlasser länger betätigen!";
CM_ SG_ 1420 M10_Text_6_Hybrid "Text 6 Hybrid";
CM_ SG_ 1420 M10_Text_7_Hybrid "Text 7 Hybrid";
CM_ SG_ 1420 M10_Text_8_Hybrid "Text 8 Hybrid";
CM_ SG_ 1420 M10_ShiftLockLampe "Bei Automatikstart/Startersteuerung im MSG: In Automatik-Fahrzeugen ist Betätigen der Bremse Freigabebedingung für den Startwunsch. (ergänzend/alternativ zur Textanzeige)";
CM_ SG_ 1420 MO_Auth_Aufforderung_WFS "WFS";
CM_ SG_ 1420 M10_BMSInfo_gue "Die vom MSG aus dem Hybrid-CAN gespiegelten Daten 'M10_VentilationReq' und 'M10_BattFanSpd' sind gültig (Botschaften vom Hybrid-CAN vor weniger als 1000ms empfangen).
BMS Hybrid Info gültig";
CM_ SG_ 1420 M10_VentilationReq "BMS fordert bei Climatronic die Öffnung der Umluftklappe an. Signal wird vom MSG von Hybrid-CAN auf den A-CAN gespiegelt (mBMS_HYB_6, Byte 8, Bit 1 aus Hybrid-CAN DF > V1.5)";
CM_ SG_ 1420 M10_BattFanSpd "Relativwert der Batterielüfter-Ansteuerung bezogen auf Maximalwert. Signal wird vom MSG von Hybrid-CAN auf den A-CAN gespiegelt
(mBMS_HYB_3, Byte 7, Bit 7..4 aus Hybrid-CAN DF > V1.5)";
CM_ SG_ 1423 MO_ITM_Kuehlmittel_Temp "Kuehlmitteltemperatur: Ersatzkühlmitteltemperatur für Motoren mit ITM (Thermomanagement)";
CM_ SG_ 1423 M12_E85_Sensor "Information über den E85 Gehalt (%-mass.) im Ottokraftstoff";
CM_ SG_ 1423 M12_SCR_Anz_Motorstarts "Anzahl noch möglicher Motorstarts, wenn Reichweite = 0 ist
0..13 = Anzeige 'x mögliche Restarts'
14 = Eingeschränkte Fahrfunktion (z. Zt. Audi)
15 = keine Einschränkung (Anzeige Reichweite)";
CM_ SG_ 1423 M12_SCR_Reichweite "Gesamtreichweite in km der aktuellen SCR-Tankfüllung";
CM_ SG_ 1423 M12_SCR_Warnstufe_1 "Ansteuerung der SCR Füllstandswarnlampe (Stufe 1) (gelbe Lampe)
SCR_Warnstufe_1 (Prio 2)";
CM_ SG_ 1423 M12_SCR_Warnstufe_2 "Ansteuerung der SCR Füllstandswarnlampe (Stufe 2) (Blinkbit für gelbe Lampe oder rote Lampe)
SCR_Warnstufe_2 (Prio 1)";
CM_ SG_ 1423 M12_SCR_Text "Warntext (z. B. in Kombination mit SCR Warnstufe und SCR-Systemfehler)
0 = kein Text
1 = Warntext 1 (Prio 2)
2 = Warntext 2 (Prio 1)
3 = Hinweistext bzgl. Füllstand
4 = reserviert
5 = Warntext 'SCR-Systemfehler Stufe 1'
6 = Warntext 'SCR-Systemfehl";
CM_ SG_ 1423 M12_Akustik "0 = keine Akustik
1 = Akustik 1 (1xSummer 2000 bei VW)
2 = Akustik 2 (3xSummer2000 bei VW)
3 = Akustik bei Hinweis (Gong 1000 bei VW)";
CM_ SG_ 1423 M12_Luftfilter_Lampe "Lampe Luftfilter verschmutzt";
CM_ SG_ 1423 M12_Kraftstofffilter_Wasser "Für Schlechtkraftstoffländer wird das Wasserabscheidevolumen im Dieselkraftstofffilter mit einem  Wassersensor überwacht. Ist das Volumen erschöpft, erfolgt im Kombi eine entsprechende Anzeige.";
CM_ SG_ 1423 M12_SCR_Systemfehler "Ansteuerung Anzeige für SCR-Systemfehler";
CM_ SG_ 1423 M12_SCR_Inducement "Reserviert für Information an das Kombi, welches Anzeigekonzept das Kombiinstrument passend zur Auslegung des Motor-Inducement-Konzeptes bedienen soll.";
CM_ SG_ 1423 M12_CO2_Faktor "dynamischer Umrechnungsfaktor von l in CO2";
CM_ SG_ 1423 M12_MKB_MUX "Die vier Motorkennbuchstaben werden gemultiplext in MO_MKB übertragen. Das Signal MO_MKB_MUX stellt das Steuersignal für diesen Multiplexer dar.";
CM_ SG_ 1423 M12_MKB_01 "Motorkennbuchstabe 1";
CM_ SG_ 1423 M12_MKB_02 "Motorkennbuchstabe 2";
CM_ SG_ 1423 M12_MKB_03 "Motorkennbuchstabe 3";
CM_ SG_ 1423 M12_MKB_04 "Motorkennbuchstabe 4";
CM_ SG_ 1450 MO_Heizungspumpenansteuerung "Anforderung Heizungspumpenansteuerung ";
CM_ SG_ 1450 MO_Nachlaufzeit_Heizungspumpe "Nachlaufzeit für Heizungspumpe für Turboladerschutz";
CM_ SG_ 1450 MO_Absperrventil_oeffnen "Signal an Klima-SG das Absperrrventil anzusteuern.";
CM_ SG_ 1450 MO_aktives_Getriebeheizen "Information für Getriebe, ob ein Ventil für Getriebheizen angesteuert werden muss";
CM_ SG_ 1450 MO_Getriebe_kuehlen "Anforderung Getriebekühlventilansteuerung";
CM_ SG_ 1450 MO_Zustand_HWP "Rückmeldung des  Ansteuerzustand der Hauptwasserpumpe an das Klima-SG .
Der Zustand 'HWP fördert' wird übermittelt, wenn die Schaufeln der Hauptwasserpumpe frei drehen können und die Motordrehzahl und damit die Wasserpumpendrehzahl größer als Null ist. B";
CM_ SG_ 1450 MO_BKV_Unterdruckwarnung "Über die Unterdruckwarnung signalisiert das MSG dem ESP, dass kein ausreichender Unterdruck für den BKV zur Verfügung gestellt werden kann.";
CM_ SG_ 1450 MO_StartStopp_Codiert "Funktion StartStopp im aktuellen Klemmenzyklus verbaut
Nur Audi Q7 MP!
Wird in Fahrzeugprojekten der PQ25/35/46 zunächst nicht unterstützt und ist ggf. gesondert einzufordern!";
CM_ SG_ 1450 MO_Zylinderabschaltung "Status Zylinderabschaltung Motor";
CM_ SG_ 1450 MO_Heizstrom_SCR "Aktuelle Gesamtstromaufnahme der Tank-, Fördermodul- und Leitungsheizung des SCR-Systems";
CM_ SG_ 1450 MO_Heizstrom_EKAT "Aktuelle Gesamtstromaufnahme des E-Katalysators";
CM_ SG_ 1450 MO_Ext_E_Fahrt_aktiv "AU716: Funktionsrückmeldung zum erw. E-Fahr-Betrieb über Lampe/LED im E-Mode-Taster";
CM_ SG_ 1450 MO_E85_WU_Lampe "E85 Warm Up Lampe im Kombi, nur Flexfuel (nur BY62x)";
CM_ SG_ 1450 MO_E85_WU_Texte "E85 Warm UP Text im Kombi, nur Flexfuel (nur BY62x)";
CM_ SG_ 1450 MO_Zylabsch_Texte "Texte Zylinderabschaltung (nur BY62x)";
CM_ SG_ 1450 MO_E85_BS_Texte "E85 Brennstoff Texte im Kombi, nur Flexfuel (nur BY62x)";
CM_ SG_ 1407 MO_Charisma_FahrPr "Aktuelles Fahrprogramm des Charisma-Teilnehmers";
CM_ SG_ 1407 MO_Charisma_Status "Charisma Systemstatus des Charisma-Teilnehmers";
CM_ SG_ 1407 GE_Charisma_FahrPr "Aktuelles Fahrprogramm des Charisma-Teilnehmers";
CM_ SG_ 1407 GE_Charisma_Status "Charisma Systemstatus des Charisma-Teilnehmers";
CM_ SG_ 1407 MO_Bremslicht_Reku "Bremslicht (ggf. bei Rekuperation durch E-Motor) wird angesteuert";
CM_ SG_ 1407 MO_Verbrauch_EM "Energieverbrauch E-Antrieb

Interner Verbrauchszähler, der vom Kombi zyklisch ausgelesen wird, um die Energiemenge zur Verbrauchsberechnung aufzusummieren; aus diesem Zählerstand werden Momentan-, Durchschnittsverbrauch und Reichweite berechnet; das Übe";
CM_ SG_ 1407 MO_UeberlVerb_EM "Der interne Verbrauchszähler E-Antrieb ist mindestens einmal übergelaufen.";
CM_ SG_ 1407 MO_Rekuperation_EM "Rekuperation E-Antrieb

Interner Rekuperationsszähler, der vom Kombi zyklisch ausgelesen wird, um die Energiemenge zur Rekuperationsberechnung aufzusummieren; aus diesem Zählerstand werden Momentan-, Durchschnittsverbrauch und Reichweite berechnet; das ";
CM_ SG_ 1407 MO_UeberlReku_EM "Der interne Rekuperationszähler E-Antrieb ist mindestens einmal übergelaufen.";
CM_ SG_ 1407 MO_Verbrauch_NA "Energieverbrauch Nebenaggregate (DCDC, EKK, Hochvolt-PTC)

Interner Verbrauchszähler, der vom Kombi zyklisch ausgelesen wird, um die Energiemenge zur Verbrauchsberechnung aufzusummieren; aus diesem Zählerstand werden Momentan-, Durchschnittsverbrauch un";
CM_ SG_ 1407 MO_UeberlVerb_NA "Der interne Verbrauchszähler Nebenaggregate ist mindestens einmal übergelaufen.";
CM_ SG_ 648 MO2_CAN_Vers "Multiplex-Info (CAN-Version)";
CM_ SG_ 648 MO2_Motor_Code "Multiplex-Info (Motor-Kodierinfo)";
CM_ SG_ 648 MO2_Getr_Code "Multiplex-Info (Getriebe-Kodierinfo)";
CM_ SG_ 648 MO2_max_Mo "Multiplex-Info (maximales Moment (Normierwert MDI))";
CM_ SG_ 648 MO2_Mp_Code "Multiplex-Code und Multiplex-Info sind verkettet
der Multiplex-Code wird nach 4 Übertragungen weitergeschaltet; dieser Mechanismus wiederholt sich somit nach 4 x 4 = 16 Umlaufzeiten";
CM_ SG_ 648 MO2_Kuehlm_T "Motor-Kühlmitteltemperatur oder Ersatzwert
Initwert 0 ist außerhalb des Wertebereichs";
CM_ SG_ 648 MO2_BLS "Ungefiltertes Rohsignal (Fzg. ohne BLS (z. B. Touareg GP): siehe 'Spezifikation Schnittstelle und Verhalten bei Fahrerbremsung für Motorsteuergerät und Bremsensteuergerät im Touareg GP', Autor M. Williges)";
CM_ SG_ 648 MO2_BTS "Ein Empfänger kann BLS und BTS miteinander plausibilisieren ('0' für nicht verbaut)
Fzg. ohne BTS (z.B. PQ46): Bit aus Bremse 1, Byte 2, Bit 3 Bremsdruckschwelle überschritten wird gespiegelt
Touareg GP: siehe 'Spezifikation Schnittstelle und Verhalten ";
CM_ SG_ 648 MO2_Sta_Kuehlm "n i.O. steht für Ersatzwert oder Fehlerwert in Byte 2
Fehlerstatus Kühlmitteltemperatur (Motor 2)";
CM_ SG_ 648 MO2_Sta_Klima "Zustand des Klimakompressors, d.h. Rückmeldung der bidirektionalen Schnittstelle (konventionell oder CAN)
Ansteuerung Klima";
CM_ SG_ 648 MO2_Sta_No_Bet "Normalbetrieb steht für Klemme 15 ein, Initialisierungsphase abgeschlossen und kein Motorstartvorgang (aus Sicht des Motorsteuergerätes)";
CM_ SG_ 648 MO2_Status_TSK "Status Triebstrangkoordinator (gültig ab Antrieb-CAN-Version 5.1.x)
(Info: war 'OBD2 freeze frame')";
CM_ SG_ 648 MO2_Sta_GRA "00 steht auch für nicht verbaut und ADR nicht zulässig
01 bedeutet eingeschaltet, GRA vom Fahrer aktiviert und z.Zt. im Regelbetrieb oder ADR erlaubt
10 Fahrer gibt mehr Gas als der Regler
11 Fehler in Motorsteuerung oder Time out oder CS-Fehler in Bot";
CM_ SG_ 648 MO2_Sta_Limiter "Kombi schaltet bei <>0 auf Limiter-Anzeige um (z. Zt. kein Einsatz geplant)
(Info: Byte 4 war 'Fahrzeuggeschwindigkeit' teilw. noch im PQ25,T5GP)";
CM_ SG_ 648 MO2_GRAregelt "GRA regelt auf die im Kombi angezeigte Geschwindigkeit: 'GRA High Funktion' (z.Zt. nur in Fahrzeugen mit neuer Konzern-GRA, z.B. PQ46)
(Info: Byte 4 war 'Fahrzeuggeschwindigkeit' teilw. noch im PQ25,T5GP)";
CM_ SG_ 648 MO2_Sport_Error "Bit wird gesetzt, wenn die Funktion 'Sport' durch das Motor SG nicht realisiert werden kann (nur Otto im Porsche Cayenne)
(Info: Byte 4 war 'Fahrzeuggeschwindigkeit' teilw. noch im PQ24,T5GP)";
CM_ SG_ 648 MO2_OffRoad "OffRoad-Modus aktiv (nur VW416)
Zuschaltung folgender Funktionen: Anfahrhilfe, flache Fahrpedalkennung, AQ Gangstufenvorwahl, Hill Descent Control
(Info: Byte 4 war 'Fahrzeuggeschwindigkeit' teilw. noch im PQ25,T5GP)";
CM_ SG_ 648 MO2_RME_Gehalt "Rapsölmethylester-Gehalt (Diesel) (wird z. Zt. nicht bedient)
(evtl. mit Bio-Ethanol-Gehalt bei Benzinern belegen)
(Info: Byte 4 war 'Fahrzeuggeschwindigkeit' teilw. noch im PQ25,T5GP)";
CM_ SG_ 648 MO2_GRA_Soll "eingestellte GRA-Sollgeschwindigkeit
Achtung: Nicht für neue Projekte verwenden, nachdem neue GRA implementiert ist!
Entfall/Umdefinition geplant. Alternative Größe in Botschaft ACC_GRA_Anzeige.";
CM_ SG_ 648 MO2_LL_Solldz "statischer Vorgabewert für CVT Getriebe

Hybrid PQ35 und Hybrid PL71:
Verbrennungsmotor-LL-Soll-DZ soll bei KL15 ein immer gesendet werden.
Leerlaufsolldrehzahl (Motor 2)";
CM_ SG_ 648 MO2_Begr_Mo "inneres maximal mögliches Moment bei einer Drehzahl (z.B. Rauch-begrenzung oder Fehlerfall)

Hybrid (Signal 'Max. mögl. ind. Moment'):
Ist ein indiziertes Moment.
Max. mögliches positives E-Maschinen-Moment muss hier aufaddiert werden.;Größe kann nur ";
CM_ SG_ 648 MO2_Mo_ZWR "nur bei Otto-Motoren (Diesel setzt Byte auf 0)

Hybrid:
Ist ein indiziertes Moment.
Eingriffe auf das Kurbelwellenmoment sind auch mittels E-Maschine möglich, jedoch nur im Rahmen des ind. Momentes oE aus Motor_1, => Größe kann nur >=0 sein.
Min. Mot";
CM_ SG_ 896 MO3_Vorgluehen "Vorglühmeldung ohne Aufprüfen. Diesel-SG initialisieren mit '1' und senden solange den Wert '1' bis entweder die Glühzeitberechnung ergeben hat, dass nicht vorgeglüht werden muss oder der Vorglühvorgang beendet wurde. Otto-SG senden konstant '0'.";
CM_ SG_ 896 MO3_Prio_Dz "Wunschdrehzahl in Byte 7 ist als Zwang oder als Wunsch an das Getriebe zu interpretieren
(Info: war 'Übertemperaturschutz' teilw. noch im PQ25,T5GP)
Motor Wunschdrehzahl Priorität";
CM_ SG_ 896 MO_Schalter_StartStopp "Deaktivierung Start/Stopp durch den Fahrer";
CM_ SG_ 896 MO3_Winterprg "Bei aktivem Winterfahrprogramm wird die Ausgabe des Pedalkennfeldes im Motor modifiziert (PQ35)";
CM_ SG_ 896 MO3_Sta_Pedal "Ersatzwert in Byte 3, Leergas- oder Kickdown-Info können betroffen sein
Fahrpedalwert ungenau (Motor 3)";
CM_ SG_ 896 MO3_Sta_FPG "Nur wenn das Bit 'Steuerungsbit Fahrpedalgradient' gesetzt ist werden die beide Signale: 'Fahrpedalgradient' (Motor 3 Byte 8 Bit 7..0) und 'Vorzeichen Fahrpedalgradient' (Motor 3 Byte 3 Bit 6) vom ESP-Steuergerät zur Vorbefüllung der Radbremsen zur Verkür";
CM_ SG_ 896 MO3_Sign_FPG "Kennzeichnet das Vorzeichen des Signals 'Fahrpedalgradient' (Motor 3 Byte 8 Bit 7...0). Die Ausgabe erfolgt nur bei parallel statisch mit gesendetem Signal: 'Steuerungsbit Fahrpedalgradient' (Motor 3 Byte 1 Bit 5) (AU716, Audi TTNF, T5, D3, C6)";
CM_ SG_ 896 MO3_Sta_Temp "Ersatzwert oder Fehlerwert
Fehlerstatus Ansauglufttemperatur";
CM_ SG_ 896 MO3_Aussentemp "In Fahrzeugen ohne Außentemperatur vom Kombi kann aus der Ansauglufttemperatur auf die Außentemperatur geschlossen werden. Beim SDI ist das mit einer gewissen Genauigkeit gegeben. Genutzt wird es vom ASG.
Ansauglufttemperatur";
CM_ SG_ 896 MO3_Pedalwert "Siehe Fahrpedalspezifikation
Fahrpedal-Rohsignal";
CM_ SG_ 896 MO3_Rad_Wu_Mo "Low Byte 4; High Nibble in Byte 5; der Wertebereich geht damit von 0 bis 4094 x 0,39 Prozent MDI (Byte 4 entspricht in der Darstellung den anderen Motormomenten, Nibble in Byte 5 ist die Erweiterung)
Rad-Wunschmoment";
CM_ SG_ 896 MO3_Vorz_RadWu "Vorzeichen-Bit Rad-Wunschmoment";
CM_ SG_ 896 MO3_Freigabe_Segeln "Freigabebit des Segelbetriebs im Getriebe. Bedingt durch bestimmte Diagnosen und Adaptionen des MSGs, die nur im Schub möglich sind, darf nicht jede Schubphase für einen Segelbetrieb genutzt werden. Eine Freigabe bleibt auch außerhalb einer Schubphase bes";
CM_ SG_ 896 MO3_Dz_Beeinfl "Mit diesem Faktor kann das Motorsteuergerät die vom VL30-Getriebe einzustellende Sollmotordrehzahl beeinflussen. Im VL30-Steuergerät ist ein verbrauchsoptimales Kennfeld und ein abgasoptimiertes Kennfeld abgelegt. Mit dem Wert von 0-100% wird zwischen die";
CM_ SG_ 896 MO3_WunschDz "wenn das Bit 'Motor-Wunschdrehzahl Priorität' (Byte 1, Bit 1) gesetzt ist, wird hier vom Motor-SG eine wegen Übertemperaturschutz oder wegen Motor internen Fehlern bedingte Maximal-Motordrehzahl ausgegeben, die das Getriebe-SG durch Rückschaltungen nicht ";
CM_ SG_ 896 MO3_DKW "Rohsignal des Drosselklappenpotis bei Otto Motor Steuergeräten mit E-Gas
Entfall zukünftig geplant
Die Ausgabe erfolgt nur wenn Signal: 'Steuerungsbit Fahrpedalgradient' (Motor 3, Byte 1, Bit 5) auf 0";
CM_ SG_ 896 MO3_FPGradient "Das Motorsteuergerät besitzt 2 analoge Fahrpedalsignale. Diese werden alle 4ms abgetastet. Entsprechend der Steuergeräte spezifischen Zykluszeit (Otto-Motor-Steuergeräte: alle 10ms, Diesel-Motor-Steuergeräte: alle 20ms), dann die einzelnen Gradienten bere";
CM_ SG_ 1152 MO5_max_Moment "Motor Multiplex-Info (maximales Drehmoment) (Code 00)";
CM_ SG_ 1152 MO5_Drehzahl "Motor Multiplex-Info (Drehzahl bei max. Drehmoment) (Code 01)";
CM_ SG_ 1152 MO5_Motortyp "Motor Multiplex-Info (Motortyp) (Code 10)
Bit 3...0: Zweizylinder 2 Dreizylinder 3 Vierzylinder 4 Fuenfzylinder 5 Sechszylinder 6 Achtzylinder 8 Zehnzylinder 10 Zwoelfzylinder 12 Fuenfzehnzylinder 13 Sechzehnzylinder 14 Achtzehnzylinder 15
Bit 4: Turbo_";
CM_ SG_ 1152 MO5_Abgastyp "Motor Multiplex-Info (Abgastyp) (Code 11)
(Info: war 'normierter Verbrauch' teilw. noch im PQ25, T5GP)";
CM_ SG_ 1152 MO5_Abgastyp2 "Motor Multiplex-Info (Abgastyp) (Code 11)
(Info: war 'normierter Verbrauch' teilw. noch im PQ25, T5GP)";
CM_ SG_ 1152 MO5_Abgastyp3 "Motor Multiplex-Info (Abgastyp) (Code 11)
(Info: war 'normierter Verbrauch' teilw. noch im PQ25, T5GP)";
CM_ SG_ 1152 OBD_Kaltstart_Denominator "Bestimmte Diagnosen werden nur unter Kaltstartbedingungen durchgeführt, der entsprechende Denominator bei IUMPR-pflichtigen Systemen wird anhand dieses vom MSG gebildeten Signals inkrementiert. (Entspricht EVAP-Denominator)";
CM_ SG_ 1152 OBD_Minimum_Trip "Grundlage OBD-Gesetz CCR 1968.2 (d)(4.3) Denominator Specifications
Bildung des General Denominator 'Normed Trip':
- 600 sec. (kumulativ) Zeit nach Motorstart
- 300 sec. (kumulativ) mit Fahrzeuggeschwindigkeit > 25 mph (40 km/h)
- 30 sec. (kontinuierl";
CM_ SG_ 1152 MO5_DPF_reg "Motor Multiplex-Info (Abgastyp) (Code 11)
(Info: war 'normierter Verbrauch' teilw. noch im PQ25, T5GP)
";
CM_ SG_ 1152 MO5_Mp_Code "Motor Multiplex-Code und Multiplex-Info sind verkettet; der Multiplex-Code wird nach 4 Übertragungen weitergeschaltet; dieser Mechanismus wiederholt sich somit nach 4 x 4 = 16 Umlaufzeiten";
CM_ SG_ 1152 MO5_Vorgluehen "Diesel-Vorglühlampe und Diesel-Systemlampe";
CM_ SG_ 1152 MO5_E_Gas "E-Gas Systemlampe (z.Zt. nur Otto-Motoren)";
CM_ SG_ 1152 MO5_OBD_2 "OBD bzw MIL Lampe wird vom Motorsteuergerät angesteuert, die Information in der Getriebe 1 Botschaft (Byte 6, Bit 7..4) wird vom Motorsteuergerät an das Kombi weitergereicht";
CM_ SG_ 1152 MO5_Heissl "Ansteuerung der Kühlwassertemperatur-Heißleuchte (Sensor nur noch am Motorsteuergerät): Temperatur-Schaltschwellen mit Hysterese (bei VW D1/Colorado Kombi derzeit noch nicht genutzt)";
CM_ SG_ 1152 MO5_KlimaKompr "Motor-Steuergerät schaltet Klimakompressor aus";
CM_ SG_ 1152 MO5_Feld_kuehl "Die Kennfeldkühlung ist in diesem Fahrzeug verbaut und hat keinen Systemfehler";
CM_ SG_ 1152 MO5_KliKo_Red "Klimakompressor-Leistungsreduzierung (im PQ35/46 z. Zt. nicht genutzt)";
CM_ SG_ 1152 MO5_Verbrauch "Motor-Steuergerät interner Verbrauchszähler, der vom Kombi zyklisch ausgelesen wird, um die Einspritzmenge zur Verbrauchsberechnung aufzusummieren; aus diesem Zählerstand werden Momentan- und Durchschnittsverbrauch berechnet; das Überlauf-Bit (Byte 4, Bit";
CM_ SG_ 1152 MO5_UeberlVerb "Der Motor-Steuergerät interne Verbrauchszähler ist mindestens einmal übergelaufen. Dieses Bit wird genutzt, um erkennen zu können, das das Motorsteuergerät aus dem Reset-Zustand hochläuft";
CM_ SG_ 1152 MO5_Luefter "Istzustand der Kühlerlüfteransteuerung über die PWM Schnittstelle
Lüfterstufen (z.B. 14) werden in Prozente umgerechnet
Werte > 100% sind unzulässig (Mittelwert bei zwei Lüftern)
Kühlerlüfteransteuerung (Motor 5)";
CM_ SG_ 1152 MO5_HLeuchte "Klimaanlage mußte aufgrund einer Übertemperaturerkennung abgeschaltet werden (Schwelle entspricht der Heißleuchtenvorwarnschwelle)
Heißleuchtenvorwarnung";
CM_ SG_ 1152 MO5_PartikelLamp "Partikelfilter-Lampe wird eingeschaltet";
CM_ SG_ 1152 MO5_Sta_BKU "Der Defekt der elektrischen Pumpe zur Verbesserung der Unterdruckversorgung wird angezeigt (nur Porsche Colorado)
Fehlerstatus Bremskraftunterstützungspumpe";
CM_ SG_ 1152 MO5_TypStartSteu "Startersteuerung durch das MSG bedeutet entweder manueller Start gesteuert vom MSG, Automatikstart gesteuert vom MSG oder SULEV-Automatikstart (PQ35/46) mit Startersteuerung im MSG und Relaisansteuerung durch das BCM
Typ Startersteuerung";
CM_ SG_ 1152 MO5_TDE_Lampe "Ansteuerung Tankdeckel-Warnlampe Kombiinstrument (nur Ottomotoren)";
CM_ SG_ 1152 MO5_TDE_Text "Anzeige im Kombiinstrument, dass Tankdeckel offen sein könnte (nur Ottomotoren)
Motortext-Bit Tankdeckelwarnung";
CM_ SG_ 1152 MO5_DZM_Daempf "Dämpfungskonstanten des Drehzahlmessers im Kombi können umgeschaltet werden";
CM_ SG_ 1152 MO5_Interlock "Interlockschalter muß beim Handschalter betätigt sein, damit ein Motorstart erlaubt ist (z.Zt. bei Audi-Handschalter mit Automatikstart und VW mit Automatikstart)
Bei Stufenautomaten (VW) wird Bit abhängig von PN gesetzt.";
CM_ SG_ 1152 MO5_Start "Bit wird gesetzt, wenn der Motor beim Automatikstart (nur im VW D1/Colorado Otto; nicht bei sonstigen Audi) gestartet werden darf (Motorstillstand, Emissionsmaßnahmen sind erfüllt,..)
Anlasser Freigabe";
CM_ SG_ 1152 MO5_Anlasser "'Anlasser darf angesteuert werden' bedeutet bei 'Typ Startersteuerung = 0', dass die externe Startersteuerung im BSG/BCM/Kessy den Anlasser aus Motorsicht ansteuern darf.
Bei 'Typ Startersteuerung = 1' bedeutet es, dass eine KL50-Anforderung an das MSG z";
CM_ SG_ 1152 MO5_GRA_Hauptsch "z.Zt. bei VW (nicht bei Audi): Schalter gerastet ein (bei Taster der Ausgang des Status Flipflops)
Porsche: Anforderungen GRA-Bereitschafts-Lampe an/aus
GRA-Hauptschalter/ GRA-Bereitschaft";
CM_ SG_ 1152 MO5_Momente "Normwert MDI wird verdoppelt
Doppelte Momente";
CM_ SG_ 1152 MO5_Motortext1 "Text 1: Motorstrg Werkstatt
(im Audi TTRS: 'Werkstatt aufsuchen')";
CM_ SG_ 1152 MO5_Motortext2 "Text 2: Abgas Werkstatt (wg. Gesetzesbestimmungen nicht mehr verwenden)";
CM_ SG_ 1152 MO5_Motortext3 "Text 3: Fehler im Kraftstoffsystem";
CM_ SG_ 1152 MO5_Motortext4 "Text 4: Partikelfilter benötigt Regeneration";
CM_ SG_ 1152 MO5_Checksumme "Prüfsumme mit Endwert 0x0, Definition im CAN Lastenheft (HS-CAN V4.2a, LS-CAN V1.42)";
BA_DEF_ BO_  "GenMsgAutoGenDsp" ENUM  "No","Yes";
BA_DEF_ BO_  "GenMsgAutoGenSnd" ENUM  "No","Yes";
BA_DEF_ BO_  "GenMsgCycleTime" INT 0 65535;
BA_DEF_ BO_  "GenMsgCycleTimeFast" INT 0 65535;
BA_DEF_ BO_  "GenMsgDelayTime" INT 0 100000;
BA_DEF_ BO_  "GenMsgILSupport" ENUM  "No","Yes";
BA_DEF_ BO_  "GenMsgSendType" ENUM  "Cyclic","not_used","not_used","not_used","not_used","not_used","not_used","IfActive","NoMsgSendType";
BA_DEF_ BO_  "GenMsgStartDelayTime" INT 0 100000;
BA_DEF_ BO_  "NmMessage" ENUM  "No","Yes";
BA_DEF_ BO_  "NmhMessage" ENUM  "No","Yes";
BA_DEF_ BO_  "VAGTP20_API" HEX 0 255;
BA_DEF_ BO_  "VAGTP20_DynConnection" ENUM  "No","Yes";
BA_DEF_ BO_  "VAGTP20_DynSetup" ENUM  "No","Yes";
BA_DEF_ BO_  "VAGTP20_StatConnection" ENUM  "No","Yes";
BA_DEF_ BO_  "Timeoutzeit" INT 0 1000000;
BA_DEF_ BO_  "DiagRequest" ENUM  "No","Yes";
BA_DEF_ BO_  "DiagResponse" ENUM  "No","Yes";
BA_DEF_ BO_  "DiagState" ENUM  "No","Yes";
BA_DEF_ BO_  "GenMsgChkConstant" HEX 0 4095;
BA_DEF_ SG_  "GenSigAutoGenDsp" ENUM  "No","Yes";
BA_DEF_ SG_  "GenSigAutoGenSnd" ENUM  "No","Yes";
BA_DEF_ SG_  "GenSigEnvVarType" ENUM  "int","float","undef";
BA_DEF_ SG_  "GenSigInactiveValue" INT -2147483648 2147483647;
BA_DEF_ SG_  "GenSigSendType" ENUM  "Cyclic","OnWrite","OnWriteWithRepetition","OnChange","OnChangeWithRepetition","IfActive","IfActiveWithRepetition","NoSigSendType","OnChangeAndIfActive","OnChangeAndIfActiveWithRepetition";
BA_DEF_ SG_  "GenSigStartValue" INT -2147483648 2147483647;
BA_DEF_ SG_  "NWM-WakeupAllowed" ENUM  "No","Yes";
BA_DEF_ SG_  "GenSigFuncType" ENUM  "NoFunction","MsgCounter","CRC-8","XOR","XOR-2","DatedBit","SW-Kl15","CHK","Constant","Protocol";
BA_DEF_ SG_  "GenSigSwitchedByIgnition" ENUM  "No","Yes";
BA_DEF_ SG_  "Fehlerwert" HEX 0 2147483647;
BA_DEF_ SG_  "GenSigMissingSourceValue" HEX 0 2147483647;
BA_DEF_REL_ BU_SG_REL_  "GenSigTimeoutTime" INT 0 65535;
BA_DEF_DEF_REL_ "GenSigTimeoutTime" 0;
BA_DEF_DEF_  "GenMsgAutoGenDsp" "Yes";
BA_DEF_DEF_  "GenMsgAutoGenSnd" "Yes";
BA_DEF_DEF_  "GenMsgCycleTime" 0;
BA_DEF_DEF_  "GenMsgCycleTimeFast" 0;
BA_DEF_DEF_  "GenMsgDelayTime" 0;
BA_DEF_DEF_  "GenMsgILSupport" "No";
BA_DEF_DEF_  "GenMsgSendType" "NoMsgSendType";
BA_DEF_DEF_  "GenMsgStartDelayTime" 0;
BA_DEF_DEF_  "NmMessage" "No";
BA_DEF_DEF_  "NmhMessage" "No";
BA_DEF_DEF_  "VAGTP20_API" 0;
BA_DEF_DEF_  "VAGTP20_DynConnection" "No";
BA_DEF_DEF_  "VAGTP20_DynSetup" "No";
BA_DEF_DEF_  "VAGTP20_StatConnection" "No";
BA_DEF_DEF_  "Timeoutzeit" 0;
BA_DEF_DEF_  "DiagRequest" "No";
BA_DEF_DEF_  "DiagResponse" "No";
BA_DEF_DEF_  "DiagState" "No";
BA_DEF_DEF_  "GenMsgChkConstant" 0;
BA_DEF_DEF_  "GenSigAutoGenDsp" "No";
BA_DEF_DEF_  "GenSigAutoGenSnd" "No";
BA_DEF_DEF_  "GenSigEnvVarType" "undef";
BA_DEF_DEF_  "GenSigInactiveValue" 0;
BA_DEF_DEF_  "GenSigSendType" "NoSigSendType";
BA_DEF_DEF_  "GenSigStartValue" 0;
BA_DEF_DEF_  "NWM-WakeupAllowed" "No";
BA_DEF_DEF_  "GenSigFuncType" "NoFunction";
BA_DEF_DEF_  "GenSigSwitchedByIgnition" "Yes";
BA_DEF_DEF_  "Fehlerwert" 0;
BA_DEF_DEF_  "GenSigMissingSourceValue" 0;
BA_ "GenMsgSendType" BO_ 208 0;
BA_ "GenMsgILSupport" BO_ 208 1;
BA_ "GenMsgCycleTime" BO_ 208 10;
BA_ "GenMsgSendType" BO_ 398 0;
BA_ "GenMsgILSupport" BO_ 398 1;
BA_ "GenMsgCycleTime" BO_ 398 10;
BA_ "GenMsgSendType" BO_ 654 0;
BA_ "GenMsgILSupport" BO_ 654 1;
BA_ "GenMsgCycleTime" BO_ 654 50;
BA_ "GenMsgSendType" BO_ 655 0;
BA_ "GenMsgILSupport" BO_ 655 1;
BA_ "GenMsgCycleTime" BO_ 655 50;
BA_ "GenMsgSendType" BO_ 194 0;
BA_ "GenMsgILSupport" BO_ 194 1;
BA_ "GenMsgCycleTime" BO_ 194 10;
BA_ "GenMsgSendType" BO_ 916 0;
BA_ "GenMsgILSupport" BO_ 916 1;
BA_ "GenMsgCycleTime" BO_ 916 100;
BA_ "GenMsgSendType" BO_ 1986 7;
BA_ "GenMsgSendType" BO_ 640 0;
BA_ "GenMsgILSupport" BO_ 640 1;
BA_ "GenMsgCycleTime" BO_ 640 10;
BA_ "GenMsgSendType" BO_ 1420 0;
BA_ "GenMsgILSupport" BO_ 1420 1;
BA_ "GenMsgDelayTime" BO_ 1420 10;
BA_ "GenMsgCycleTime" BO_ 1420 100;
BA_ "GenMsgSendType" BO_ 1423 0;
BA_ "GenMsgILSupport" BO_ 1423 1;
BA_ "GenMsgCycleTime" BO_ 1423 500;
BA_ "GenMsgSendType" BO_ 1450 0;
BA_ "GenMsgILSupport" BO_ 1450 1;
BA_ "GenMsgDelayTime" BO_ 1450 20;
BA_ "GenMsgCycleTime" BO_ 1450 500;
BA_ "GenMsgSendType" BO_ 1407 0;
BA_ "GenMsgCycleTime" BO_ 1407 50;
BA_ "GenMsgSendType" BO_ 648 0;
BA_ "GenMsgILSupport" BO_ 648 1;
BA_ "GenMsgCycleTime" BO_ 648 20;
BA_ "GenMsgSendType" BO_ 896 0;
BA_ "GenMsgILSupport" BO_ 896 1;
BA_ "GenMsgCycleTime" BO_ 896 10;
BA_ "GenMsgSendType" BO_ 1152 0;
BA_ "GenMsgILSupport" BO_ 1152 1;
BA_ "GenMsgCycleTime" BO_ 1152 20;
BA_ "GenSigSwitchedByIgnition" SG_ 208 LH3_Checksumme 0;
BA_ "GenSigFuncType" SG_ 208 LH3_Checksumme 4;
BA_ "GenSigSendType" SG_ 208 LH3_Checksumme 0;
BA_ "GenSigAutoGenSnd" SG_ 208 LH3_Checksumme 1;
BA_ "GenSigAutoGenDsp" SG_ 208 LH3_Checksumme 1;
BA_ "GenSigSwitchedByIgnition" SG_ 208 LH3_BS_Spiegel 0;
BA_ "GenSigSendType" SG_ 208 LH3_BS_Spiegel 0;
BA_ "GenSigAutoGenSnd" SG_ 208 LH3_BS_Spiegel 1;
BA_ "GenSigAutoGenDsp" SG_ 208 LH3_BS_Spiegel 1;
BA_ "GenSigSwitchedByIgnition" SG_ 208 LH3_Zaehler 0;
BA_ "GenSigFuncType" SG_ 208 LH3_Zaehler 1;
BA_ "GenSigSendType" SG_ 208 LH3_Zaehler 0;
BA_ "GenSigAutoGenSnd" SG_ 208 LH3_Zaehler 1;
BA_ "GenSigAutoGenDsp" SG_ 208 LH3_Zaehler 1;
BA_ "GenSigSwitchedByIgnition" SG_ 208 LH3_LM 0;
BA_ "GenSigSendType" SG_ 208 LH3_LM 0;
BA_ "GenSigAutoGenSnd" SG_ 208 LH3_LM 1;
BA_ "GenSigAutoGenDsp" SG_ 208 LH3_LM 1;
BA_ "GenSigSwitchedByIgnition" SG_ 208 LH3_LMSign 0;
BA_ "GenSigSendType" SG_ 208 LH3_LMSign 0;
BA_ "GenSigAutoGenSnd" SG_ 208 LH3_LMSign 1;
BA_ "GenSigAutoGenDsp" SG_ 208 LH3_LMSign 1;
BA_ "GenSigSwitchedByIgnition" SG_ 208 LH3_LMValid 0;
BA_ "GenSigSendType" SG_ 208 LH3_LMValid 0;
BA_ "GenSigAutoGenSnd" SG_ 208 LH3_LMValid 1;
BA_ "GenSigAutoGenDsp" SG_ 208 LH3_LMValid 1;
BA_ "GenSigSwitchedByIgnition" SG_ 208 LH3_Sta_DSR 0;
BA_ "GenSigSendType" SG_ 208 LH3_Sta_DSR 0;
BA_ "GenSigAutoGenSnd" SG_ 208 LH3_Sta_DSR 1;
BA_ "GenSigAutoGenDsp" SG_ 208 LH3_Sta_DSR 1;
BA_ "GenSigSwitchedByIgnition" SG_ 208 LH3_BLW 0;
BA_ "GenSigSendType" SG_ 208 LH3_BLW 0;
BA_ "GenSigAutoGenSnd" SG_ 208 LH3_BLW 1;
BA_ "GenSigAutoGenDsp" SG_ 208 LH3_BLW 1;
BA_ "GenSigSwitchedByIgnition" SG_ 208 LH3_BLWSign 0;
BA_ "GenSigSendType" SG_ 208 LH3_BLWSign 0;
BA_ "GenSigAutoGenSnd" SG_ 208 LH3_BLWSign 1;
BA_ "GenSigAutoGenDsp" SG_ 208 LH3_BLWSign 1;
BA_ "GenSigSwitchedByIgnition" SG_ 208 LH3_BLWValid 0;
BA_ "GenSigSendType" SG_ 208 LH3_BLWValid 0;
BA_ "GenSigAutoGenSnd" SG_ 208 LH3_BLWValid 1;
BA_ "GenSigAutoGenDsp" SG_ 208 LH3_BLWValid 1;
BA_ "GenSigSwitchedByIgnition" SG_ 208 LH3_Lenkungstyp 0;
BA_ "GenSigSendType" SG_ 208 LH3_Lenkungstyp 0;
BA_ "GenSigAutoGenSnd" SG_ 208 LH3_Lenkungstyp 1;
BA_ "GenSigAutoGenDsp" SG_ 208 LH3_Lenkungstyp 1;
BA_ "GenSigSwitchedByIgnition" SG_ 398 LPG_01_Reserve 0;
BA_ "GenSigSendType" SG_ 398 LPG_01_Reserve 0;
BA_ "GenSigSwitchedByIgnition" SG_ 654 LPG_02_Reserve 0;
BA_ "GenSigSendType" SG_ 654 LPG_02_Reserve 0;
BA_ "GenSigSwitchedByIgnition" SG_ 655 LPG_03_Reserve 0;
BA_ "GenSigSendType" SG_ 655 LPG_03_Reserve 0;
BA_ "GenSigSendType" SG_ 194 LW1_LRW 0;
BA_ "GenSigAutoGenSnd" SG_ 194 LW1_LRW 1;
BA_ "GenSigAutoGenDsp" SG_ 194 LW1_LRW 1;
BA_ "GenSigStartValue" SG_ 194 LW1_LRW_Sign 1;
BA_ "GenSigSendType" SG_ 194 LW1_LRW_Sign 0;
BA_ "GenSigAutoGenSnd" SG_ 194 LW1_LRW_Sign 1;
BA_ "GenSigAutoGenDsp" SG_ 194 LW1_LRW_Sign 1;
BA_ "GenSigSendType" SG_ 194 LW1_Lenk_Gesch 0;
BA_ "GenSigAutoGenSnd" SG_ 194 LW1_Lenk_Gesch 1;
BA_ "GenSigAutoGenDsp" SG_ 194 LW1_Lenk_Gesch 1;
BA_ "GenSigStartValue" SG_ 194 LW1_Gesch_Sign 1;
BA_ "GenSigSendType" SG_ 194 LW1_Gesch_Sign 0;
BA_ "GenSigAutoGenSnd" SG_ 194 LW1_Gesch_Sign 1;
BA_ "GenSigAutoGenDsp" SG_ 194 LW1_Gesch_Sign 1;
BA_ "GenSigSendType" SG_ 194 LW1_ID 0;
BA_ "GenSigAutoGenSnd" SG_ 194 LW1_ID 1;
BA_ "GenSigAutoGenDsp" SG_ 194 LW1_ID 1;
BA_ "GenSigSendType" SG_ 194 LW1_Initquelle 0;
BA_ "GenSigAutoGenSnd" SG_ 194 LW1_Initquelle 1;
BA_ "GenSigAutoGenDsp" SG_ 194 LW1_Initquelle 1;
BA_ "GenSigStartValue" SG_ 194 LW1_Status 1;
BA_ "GenSigSendType" SG_ 194 LW1_Status 0;
BA_ "GenSigAutoGenSnd" SG_ 194 LW1_Status 1;
BA_ "GenSigAutoGenDsp" SG_ 194 LW1_Status 1;
BA_ "GenSigSendType" SG_ 194 LW1_Sta_KL30 0;
BA_ "GenSigAutoGenSnd" SG_ 194 LW1_Sta_KL30 1;
BA_ "GenSigAutoGenDsp" SG_ 194 LW1_Sta_KL30 1;
BA_ "GenSigFuncType" SG_ 194 LW1_Zaehler 1;
BA_ "GenSigSendType" SG_ 194 LW1_Zaehler 0;
BA_ "GenSigAutoGenSnd" SG_ 194 LW1_Zaehler 1;
BA_ "GenSigAutoGenDsp" SG_ 194 LW1_Zaehler 1;
BA_ "GenSigFuncType" SG_ 194 LW1_Kodier 2;
BA_ "GenSigSendType" SG_ 194 LW1_Kodier 0;
BA_ "GenSigAutoGenSnd" SG_ 194 LW1_Kodier 1;
BA_ "GenSigAutoGenDsp" SG_ 194 LW1_Kodier 1;
BA_ "GenSigSendType" SG_ 194 LW1_CRC 0;
BA_ "GenSigAutoGenSnd" SG_ 194 LW1_CRC 1;
BA_ "GenSigAutoGenDsp" SG_ 194 LW1_CRC 1;
BA_ "GenSigSendType" SG_ 916 LRZ_Parameter 0;
BA_ "GenSigAutoGenSnd" SG_ 916 LRZ_Parameter 1;
BA_ "GenSigAutoGenDsp" SG_ 916 LRZ_Parameter 1;
BA_ "GenSigSendType" SG_ 916 LRZ_Grundeinst 0;
BA_ "GenSigAutoGenSnd" SG_ 916 LRZ_Grundeinst 1;
BA_ "GenSigAutoGenDsp" SG_ 916 LRZ_Grundeinst 1;
BA_ "GenSigSendType" SG_ 916 LRZ_Modus 0;
BA_ "GenSigAutoGenSnd" SG_ 916 LRZ_Modus 1;
BA_ "GenSigAutoGenDsp" SG_ 916 LRZ_Modus 1;
BA_ "GenSigSendType" SG_ 916 LRZ_Initlauf 0;
BA_ "GenSigAutoGenSnd" SG_ 916 LRZ_Initlauf 1;
BA_ "GenSigAutoGenDsp" SG_ 916 LRZ_Initlauf 1;
BA_ "GenSigSendType" SG_ 916 LRZ_Sichere_Pos 0;
BA_ "GenSigAutoGenSnd" SG_ 916 LRZ_Sichere_Pos 1;
BA_ "GenSigAutoGenDsp" SG_ 916 LRZ_Sichere_Pos 1;
BA_ "GenSigSendType" SG_ 916 LRZ_LampeAFS 0;
BA_ "GenSigAutoGenSnd" SG_ 916 LRZ_LampeAFS 1;
BA_ "GenSigAutoGenDsp" SG_ 916 LRZ_LampeAFS 1;
BA_ "GenSigSendType" SG_ 916 LRZ_Fehlerlampe 0;
BA_ "GenSigAutoGenSnd" SG_ 916 LRZ_Fehlerlampe 1;
BA_ "GenSigAutoGenDsp" SG_ 916 LRZ_Fehlerlampe 1;
BA_ "GenSigSendType" SG_ 916 LRZ_Fehler 0;
BA_ "GenSigAutoGenSnd" SG_ 916 LRZ_Fehler 1;
BA_ "GenSigAutoGenDsp" SG_ 916 LRZ_Fehler 1;
BA_ "Fehlerwert" SG_ 916 LRZ_Einfedg_vo 255;
BA_ "GenSigSendType" SG_ 916 LRZ_Einfedg_vo 0;
BA_ "GenSigAutoGenSnd" SG_ 916 LRZ_Einfedg_vo 1;
BA_ "GenSigAutoGenDsp" SG_ 916 LRZ_Einfedg_vo 1;
BA_ "Fehlerwert" SG_ 916 LRZ_Einfedg_hi 255;
BA_ "GenSigSendType" SG_ 916 LRZ_Einfedg_hi 0;
BA_ "GenSigAutoGenSnd" SG_ 916 LRZ_Einfedg_hi 1;
BA_ "GenSigAutoGenDsp" SG_ 916 LRZ_Einfedg_hi 1;
BA_ "Fehlerwert" SG_ 916 LRZ_Stellung 255;
BA_ "GenSigStartValue" SG_ 916 LRZ_Stellung 254;
BA_ "GenSigSendType" SG_ 916 LRZ_Stellung 0;
BA_ "GenSigAutoGenSnd" SG_ 916 LRZ_Stellung 1;
BA_ "GenSigAutoGenDsp" SG_ 916 LRZ_Stellung 1;
BA_ "Fehlerwert" SG_ 916 LRZ_LeistDim 255;
BA_ "GenSigStartValue" SG_ 916 LRZ_LeistDim 254;
BA_ "GenSigSendType" SG_ 916 LRZ_LeistDim 0;
BA_ "GenSigAutoGenSnd" SG_ 916 LRZ_LeistDim 1;
BA_ "GenSigAutoGenDsp" SG_ 916 LRZ_LeistDim 1;
BA_ "GenSigSendType" SG_ 916 LRZ_ELF_links 0;
BA_ "GenSigAutoGenSnd" SG_ 916 LRZ_ELF_links 1;
BA_ "GenSigAutoGenDsp" SG_ 916 LRZ_ELF_links 1;
BA_ "GenSigSendType" SG_ 916 LRZ_ELF_rechts 0;
BA_ "GenSigAutoGenSnd" SG_ 916 LRZ_ELF_rechts 1;
BA_ "GenSigAutoGenDsp" SG_ 916 LRZ_ELF_rechts 1;
BA_ "GenSigSendType" SG_ 916 LRZ_AFSLED_Blink 0;
BA_ "GenSigAutoGenSnd" SG_ 916 LRZ_AFSLED_Blink 1;
BA_ "GenSigAutoGenDsp" SG_ 916 LRZ_AFSLED_Blink 1;
BA_ "GenSigSendType" SG_ 916 LRZ_AFSFehlertext 0;
BA_ "GenSigAutoGenSnd" SG_ 916 LRZ_AFSFehlertext 1;
BA_ "GenSigAutoGenDsp" SG_ 916 LRZ_AFSFehlertext 1;
BA_ "GenSigSendType" SG_ 916 LRZ_Tourist_Fkt 0;
BA_ "GenSigAutoGenSnd" SG_ 916 LRZ_Tourist_Fkt 1;
BA_ "GenSigAutoGenDsp" SG_ 916 LRZ_Tourist_Fkt 1;
BA_ "GenSigSendType" SG_ 916 LRZ_Tourist_aktiv 0;
BA_ "GenSigAutoGenSnd" SG_ 916 LRZ_Tourist_aktiv 1;
BA_ "GenSigAutoGenDsp" SG_ 916 LRZ_Tourist_aktiv 1;
BA_ "GenSigSendType" SG_ 916 LRZ_AFS_Absch 0;
BA_ "GenSigAutoGenSnd" SG_ 916 LRZ_AFS_Absch 1;
BA_ "GenSigAutoGenDsp" SG_ 916 LRZ_AFS_Absch 1;
BA_ "GenSigSendType" SG_ 916 LRZ_AFS_deaktiv 0;
BA_ "GenSigAutoGenSnd" SG_ 916 LRZ_AFS_deaktiv 1;
BA_ "GenSigAutoGenDsp" SG_ 916 LRZ_AFS_deaktiv 1;
BA_ "GenSigSendType" SG_ 916 LRZ_Abbiegelicht_Dimm_Anf 0;
BA_ "GenSigAutoGenSnd" SG_ 916 LRZ_Abbiegelicht_Dimm_Anf 1;
BA_ "GenSigAutoGenDsp" SG_ 916 LRZ_Abbiegelicht_Dimm_Anf 1;
BA_ "GenSigSendType" SG_ 916 LRZ_Abbiegelicht_li_Anf 0;
BA_ "GenSigAutoGenSnd" SG_ 916 LRZ_Abbiegelicht_li_Anf 1;
BA_ "GenSigAutoGenDsp" SG_ 916 LRZ_Abbiegelicht_li_Anf 1;
BA_ "GenSigSendType" SG_ 916 LRZ_Abbiegelicht_re_Anf 0;
BA_ "GenSigAutoGenSnd" SG_ 916 LRZ_Abbiegelicht_re_Anf 1;
BA_ "GenSigAutoGenDsp" SG_ 916 LRZ_Abbiegelicht_re_Anf 1;
BA_ "GenSigSendType" SG_ 916 LRZ_Fernlicht_li_defekt 0;
BA_ "GenSigAutoGenSnd" SG_ 916 LRZ_Fernlicht_li_defekt 1;
BA_ "GenSigAutoGenDsp" SG_ 916 LRZ_Fernlicht_li_defekt 1;
BA_ "GenSigSendType" SG_ 916 LRZ_Fernlicht_re_defekt 0;
BA_ "GenSigAutoGenSnd" SG_ 916 LRZ_Fernlicht_re_defekt 1;
BA_ "GenSigAutoGenDsp" SG_ 916 LRZ_Fernlicht_re_defekt 1;
BA_ "GenSigSendType" SG_ 916 LRZ_Fernlicht_Status 0;
BA_ "GenSigAutoGenSnd" SG_ 916 LRZ_Fernlicht_Status 1;
BA_ "GenSigAutoGenDsp" SG_ 916 LRZ_Fernlicht_Status 1;
BA_ "GenSigStartValue" SG_ 916 LRZ_Verfuegbarkeit_GLW 1;
BA_ "GenSigSendType" SG_ 916 LRZ_Verfuegbarkeit_GLW 0;
BA_ "GenSigAutoGenSnd" SG_ 916 LRZ_Verfuegbarkeit_GLW 1;
BA_ "GenSigAutoGenDsp" SG_ 916 LRZ_Verfuegbarkeit_GLW 1;
BA_ "GenSigStartValue" SG_ 916 LRZ_Status_adaptive_LV 1;
BA_ "GenSigSendType" SG_ 916 LRZ_Status_adaptive_LV 0;
BA_ "GenSigAutoGenSnd" SG_ 916 LRZ_Status_adaptive_LV 1;
BA_ "GenSigAutoGenDsp" SG_ 916 LRZ_Status_adaptive_LV 1;
BA_ "GenSigSendType" SG_ 916 GLW_Sensor_blockiert 0;
BA_ "GenSigFuncType" SG_ 916 LRZ_Zaehler 1;
BA_ "GenSigSendType" SG_ 916 LRZ_Zaehler 0;
BA_ "GenSigAutoGenSnd" SG_ 916 LRZ_Zaehler 1;
BA_ "GenSigAutoGenDsp" SG_ 916 LRZ_Zaehler 1;
BA_ "GenSigSendType" SG_ 1986 LWI_Init_ID 4;
BA_ "GenSigAutoGenSnd" SG_ 1986 LWI_Init_ID 1;
BA_ "GenSigAutoGenDsp" SG_ 1986 LWI_Init_ID 1;
BA_ "GenSigSendType" SG_ 1986 LWI_Codierbytes 4;
BA_ "GenSigAutoGenSnd" SG_ 1986 LWI_Codierbytes 1;
BA_ "GenSigAutoGenDsp" SG_ 1986 LWI_Codierbytes 1;
BA_ "GenSigSwitchedByIgnition" SG_ 640 MO1_Leergas 0;
BA_ "GenSigSendType" SG_ 640 MO1_Leergas 0;
BA_ "GenSigAutoGenSnd" SG_ 640 MO1_Leergas 1;
BA_ "GenSigAutoGenDsp" SG_ 640 MO1_Leergas 1;
BA_ "GenSigSwitchedByIgnition" SG_ 640 MO1_Sta_Pedal 0;
BA_ "GenSigSendType" SG_ 640 MO1_Sta_Pedal 0;
BA_ "GenSigAutoGenSnd" SG_ 640 MO1_Sta_Pedal 1;
BA_ "GenSigAutoGenDsp" SG_ 640 MO1_Sta_Pedal 1;
BA_ "GenSigSwitchedByIgnition" SG_ 640 MO1_Kickdown 0;
BA_ "GenSigSendType" SG_ 640 MO1_Kickdown 0;
BA_ "GenSigAutoGenSnd" SG_ 640 MO1_Kickdown 1;
BA_ "GenSigAutoGenDsp" SG_ 640 MO1_Kickdown 1;
BA_ "GenSigSwitchedByIgnition" SG_ 640 MO1_Kup_schalt 0;
BA_ "GenSigSendType" SG_ 640 MO1_Kup_schalt 0;
BA_ "GenSigAutoGenSnd" SG_ 640 MO1_Kup_schalt 1;
BA_ "GenSigAutoGenDsp" SG_ 640 MO1_Kup_schalt 1;
BA_ "GenSigSwitchedByIgnition" SG_ 640 MO1_TiOut_Br 0;
BA_ "GenSigSendType" SG_ 640 MO1_TiOut_Br 0;
BA_ "GenSigAutoGenSnd" SG_ 640 MO1_TiOut_Br 1;
BA_ "GenSigAutoGenDsp" SG_ 640 MO1_TiOut_Br 1;
BA_ "GenSigSwitchedByIgnition" SG_ 640 MO1_Sta_Bremse 0;
BA_ "GenSigSendType" SG_ 640 MO1_Sta_Bremse 0;
BA_ "GenSigAutoGenSnd" SG_ 640 MO1_Sta_Bremse 1;
BA_ "GenSigAutoGenDsp" SG_ 640 MO1_Sta_Bremse 1;
BA_ "GenSigSwitchedByIgnition" SG_ 640 MO1_Sta_Getr 0;
BA_ "GenSigSendType" SG_ 640 MO1_Sta_Getr 0;
BA_ "GenSigAutoGenSnd" SG_ 640 MO1_Sta_Getr 1;
BA_ "GenSigAutoGenDsp" SG_ 640 MO1_Sta_Getr 1;
BA_ "GenSigSwitchedByIgnition" SG_ 640 MO1_Sta_MotMo 0;
BA_ "GenSigSendType" SG_ 640 MO1_Sta_MotMo 0;
BA_ "GenSigAutoGenSnd" SG_ 640 MO1_Sta_MotMo 1;
BA_ "GenSigAutoGenDsp" SG_ 640 MO1_Sta_MotMo 1;
BA_ "Fehlerwert" SG_ 640 MO1_Mo_m_ex 255;
BA_ "GenSigSwitchedByIgnition" SG_ 640 MO1_Mo_m_ex 0;
BA_ "GenSigSendType" SG_ 640 MO1_Mo_m_ex 0;
BA_ "GenSigAutoGenSnd" SG_ 640 MO1_Mo_m_ex 1;
BA_ "GenSigAutoGenDsp" SG_ 640 MO1_Mo_m_ex 1;
BA_ "Fehlerwert" SG_ 640 MO1_Drehzahl 65280;
BA_ "GenSigSwitchedByIgnition" SG_ 640 MO1_Drehzahl 0;
BA_ "GenSigSendType" SG_ 640 MO1_Drehzahl 0;
BA_ "GenSigAutoGenSnd" SG_ 640 MO1_Drehzahl 1;
BA_ "GenSigAutoGenDsp" SG_ 640 MO1_Drehzahl 1;
BA_ "Fehlerwert" SG_ 640 MO1_Mo_o_ex 255;
BA_ "GenSigSwitchedByIgnition" SG_ 640 MO1_Mo_o_ex 0;
BA_ "GenSigSendType" SG_ 640 MO1_Mo_o_ex 0;
BA_ "GenSigAutoGenSnd" SG_ 640 MO1_Mo_o_ex 1;
BA_ "GenSigAutoGenDsp" SG_ 640 MO1_Mo_o_ex 1;
BA_ "Fehlerwert" SG_ 640 MO1_Pedalwert 255;
BA_ "GenSigSwitchedByIgnition" SG_ 640 MO1_Pedalwert 0;
BA_ "GenSigSendType" SG_ 640 MO1_Pedalwert 0;
BA_ "GenSigAutoGenSnd" SG_ 640 MO1_Pedalwert 1;
BA_ "GenSigAutoGenDsp" SG_ 640 MO1_Pedalwert 1;
BA_ "Fehlerwert" SG_ 640 MO1_Verlustmo 255;
BA_ "GenSigSwitchedByIgnition" SG_ 640 MO1_Verlustmo 0;
BA_ "GenSigSendType" SG_ 640 MO1_Verlustmo 0;
BA_ "GenSigAutoGenSnd" SG_ 640 MO1_Verlustmo 1;
BA_ "GenSigAutoGenDsp" SG_ 640 MO1_Verlustmo 1;
BA_ "Fehlerwert" SG_ 640 MO1_Wunschmo 255;
BA_ "GenSigSwitchedByIgnition" SG_ 640 MO1_Wunschmo 0;
BA_ "GenSigSendType" SG_ 640 MO1_Wunschmo 0;
BA_ "GenSigAutoGenSnd" SG_ 640 MO1_Wunschmo 1;
BA_ "GenSigAutoGenDsp" SG_ 640 MO1_Wunschmo 1;
BA_ "GenSigSwitchedByIgnition" SG_ 1420 M10_Anzeige 0;
BA_ "GenSigSendType" SG_ 1420 M10_Anzeige 0;
BA_ "GenSigAutoGenSnd" SG_ 1420 M10_Anzeige 1;
BA_ "GenSigAutoGenDsp" SG_ 1420 M10_Anzeige 1;
BA_ "GenSigSwitchedByIgnition" SG_ 1420 M10_Anf_Kl75 0;
BA_ "GenSigStartValue" SG_ 1420 M10_Anf_Kl75 1;
BA_ "GenSigSendType" SG_ 1420 M10_Anf_Kl75 3;
BA_ "GenSigAutoGenSnd" SG_ 1420 M10_Anf_Kl75 1;
BA_ "GenSigAutoGenDsp" SG_ 1420 M10_Anf_Kl75 1;
BA_ "GenSigSwitchedByIgnition" SG_ 1420 MSG_Remotestart_Betrieb 0;
BA_ "GenSigSendType" SG_ 1420 MSG_Remotestart_Betrieb 3;
BA_ "GenSigSwitchedByIgnition" SG_ 1420 M10_SpannungsAnf 0;
BA_ "GenSigSendType" SG_ 1420 M10_SpannungsAnf 0;
BA_ "GenSigAutoGenSnd" SG_ 1420 M10_SpannungsAnf 1;
BA_ "GenSigAutoGenDsp" SG_ 1420 M10_SpannungsAnf 1;
BA_ "GenSigSwitchedByIgnition" SG_ 1420 M10_UDruckDyn 0;
BA_ "GenSigSendType" SG_ 1420 M10_UDruckDyn 0;
BA_ "GenSigAutoGenSnd" SG_ 1420 M10_UDruckDyn 1;
BA_ "GenSigAutoGenDsp" SG_ 1420 M10_UDruckDyn 1;
BA_ "GenSigSwitchedByIgnition" SG_ 1420 M10_Status_StSt 0;
BA_ "GenSigSendType" SG_ 1420 M10_Status_StSt 0;
BA_ "GenSigAutoGenSnd" SG_ 1420 M10_Status_StSt 1;
BA_ "GenSigAutoGenDsp" SG_ 1420 M10_Status_StSt 1;
BA_ "GenSigSwitchedByIgnition" SG_ 1420 M10_MotorStopp 0;
BA_ "GenSigSendType" SG_ 1420 M10_MotorStopp 3;
BA_ "GenSigAutoGenSnd" SG_ 1420 M10_MotorStopp 1;
BA_ "GenSigAutoGenDsp" SG_ 1420 M10_MotorStopp 1;
BA_ "GenSigSwitchedByIgnition" SG_ 1420 M10_Wiederstart 0;
BA_ "GenSigSendType" SG_ 1420 M10_Wiederstart 3;
BA_ "GenSigAutoGenSnd" SG_ 1420 M10_Wiederstart 1;
BA_ "GenSigAutoGenDsp" SG_ 1420 M10_Wiederstart 1;
BA_ "GenSigSwitchedByIgnition" SG_ 1420 M10_Schubabschaltung 0;
BA_ "GenSigSendType" SG_ 1420 M10_Schubabschaltung 0;
BA_ "GenSigAutoGenSnd" SG_ 1420 M10_Schubabschaltung 1;
BA_ "GenSigAutoGenDsp" SG_ 1420 M10_Schubabschaltung 1;
BA_ "GenSigSwitchedByIgnition" SG_ 1420 M10_Druck_err_gem 0;
BA_ "GenSigSendType" SG_ 1420 M10_Druck_err_gem 0;
BA_ "GenSigAutoGenSnd" SG_ 1420 M10_Druck_err_gem 1;
BA_ "GenSigAutoGenDsp" SG_ 1420 M10_Druck_err_gem 1;
BA_ "GenSigSwitchedByIgnition" SG_ 1420 M10_Freigabe_Reku 0;
BA_ "GenSigSendType" SG_ 1420 M10_Freigabe_Reku 0;
BA_ "GenSigAutoGenSnd" SG_ 1420 M10_Freigabe_Reku 1;
BA_ "GenSigAutoGenDsp" SG_ 1420 M10_Freigabe_Reku 1;
BA_ "GenSigSwitchedByIgnition" SG_ 1420 M10_rel_Saugrohrdruck 0;
BA_ "GenSigSendType" SG_ 1420 M10_rel_Saugrohrdruck 0;
BA_ "GenSigAutoGenSnd" SG_ 1420 M10_rel_Saugrohrdruck 1;
BA_ "GenSigAutoGenDsp" SG_ 1420 M10_rel_Saugrohrdruck 1;
BA_ "GenSigSwitchedByIgnition" SG_ 1420 M10_Fahrbereitschaft 0;
BA_ "GenSigSendType" SG_ 1420 M10_Fahrbereitschaft 0;
BA_ "GenSigAutoGenSnd" SG_ 1420 M10_Fahrbereitschaft 1;
BA_ "GenSigAutoGenDsp" SG_ 1420 M10_Fahrbereitschaft 1;
BA_ "GenSigSwitchedByIgnition" SG_ 1420 M10_Hybrid 0;
BA_ "GenSigSendType" SG_ 1420 M10_Hybrid 0;
BA_ "GenSigAutoGenSnd" SG_ 1420 M10_Hybrid 1;
BA_ "GenSigAutoGenDsp" SG_ 1420 M10_Hybrid 1;
BA_ "GenSigSwitchedByIgnition" SG_ 1420 M10_EM_aktiv 0;
BA_ "GenSigSendType" SG_ 1420 M10_EM_aktiv 0;
BA_ "GenSigAutoGenSnd" SG_ 1420 M10_EM_aktiv 1;
BA_ "GenSigAutoGenDsp" SG_ 1420 M10_EM_aktiv 1;
BA_ "GenSigSwitchedByIgnition" SG_ 1420 M10_VM_aktiv 0;
BA_ "GenSigSendType" SG_ 1420 M10_VM_aktiv 0;
BA_ "GenSigAutoGenSnd" SG_ 1420 M10_VM_aktiv 1;
BA_ "GenSigAutoGenDsp" SG_ 1420 M10_VM_aktiv 1;
BA_ "GenSigSwitchedByIgnition" SG_ 1420 M10_HYB_Bereitlampe 0;
BA_ "GenSigSendType" SG_ 1420 M10_HYB_Bereitlampe 0;
BA_ "GenSigAutoGenSnd" SG_ 1420 M10_HYB_Bereitlampe 1;
BA_ "GenSigAutoGenDsp" SG_ 1420 M10_HYB_Bereitlampe 1;
BA_ "GenSigSwitchedByIgnition" SG_ 1420 M10_HYB_Warnlampe 0;
BA_ "GenSigSendType" SG_ 1420 M10_HYB_Warnlampe 0;
BA_ "GenSigAutoGenSnd" SG_ 1420 M10_HYB_Warnlampe 1;
BA_ "GenSigAutoGenDsp" SG_ 1420 M10_HYB_Warnlampe 1;
BA_ "GenSigSwitchedByIgnition" SG_ 1420 M10_HYB_Fehlerlampe 0;
BA_ "GenSigSendType" SG_ 1420 M10_HYB_Fehlerlampe 0;
BA_ "GenSigAutoGenSnd" SG_ 1420 M10_HYB_Fehlerlampe 1;
BA_ "GenSigAutoGenDsp" SG_ 1420 M10_HYB_Fehlerlampe 1;
BA_ "GenSigSwitchedByIgnition" SG_ 1420 M10_Fehler_HV_Netz 0;
BA_ "GenSigSendType" SG_ 1420 M10_Fehler_HV_Netz 0;
BA_ "GenSigAutoGenSnd" SG_ 1420 M10_Fehler_HV_Netz 1;
BA_ "GenSigAutoGenDsp" SG_ 1420 M10_Fehler_HV_Netz 1;
BA_ "GenSigSwitchedByIgnition" SG_ 1420 M10_EKlKomLeiRed 0;
BA_ "GenSigSendType" SG_ 1420 M10_EKlKomLeiRed 0;
BA_ "GenSigAutoGenSnd" SG_ 1420 M10_EKlKomLeiRed 1;
BA_ "GenSigAutoGenDsp" SG_ 1420 M10_EKlKomLeiRed 1;
BA_ "Fehlerwert" SG_ 1420 M10_Klimadruck 255;
BA_ "GenSigSwitchedByIgnition" SG_ 1420 M10_Klimadruck 0;
BA_ "GenSigStartValue" SG_ 1420 M10_Klimadruck 254;
BA_ "GenSigSendType" SG_ 1420 M10_Klimadruck 0;
BA_ "GenSigAutoGenSnd" SG_ 1420 M10_Klimadruck 1;
BA_ "GenSigAutoGenDsp" SG_ 1420 M10_Klimadruck 1;
BA_ "GenSigSwitchedByIgnition" SG_ 1420 M10_KompAusCode 0;
BA_ "GenSigSendType" SG_ 1420 M10_KompAusCode 0;
BA_ "GenSigAutoGenSnd" SG_ 1420 M10_KompAusCode 1;
BA_ "GenSigAutoGenDsp" SG_ 1420 M10_KompAusCode 1;
BA_ "GenSigSwitchedByIgnition" SG_ 1420 M10_StartStopp_Fahrerwunsch 0;
BA_ "GenSigSendType" SG_ 1420 M10_StartStopp_Fahrerwunsch 3;
BA_ "GenSigSwitchedByIgnition" SG_ 1420 M10_Akustik 0;
BA_ "GenSigSendType" SG_ 1420 M10_Akustik 0;
BA_ "GenSigAutoGenSnd" SG_ 1420 M10_Akustik 1;
BA_ "GenSigAutoGenDsp" SG_ 1420 M10_Akustik 1;
BA_ "GenSigSwitchedByIgnition" SG_ 1420 M10_Text_1_Hybrid 0;
BA_ "GenSigSendType" SG_ 1420 M10_Text_1_Hybrid 0;
BA_ "GenSigAutoGenSnd" SG_ 1420 M10_Text_1_Hybrid 1;
BA_ "GenSigAutoGenDsp" SG_ 1420 M10_Text_1_Hybrid 1;
BA_ "GenSigSwitchedByIgnition" SG_ 1420 M10_Text_2_Hybrid 0;
BA_ "GenSigSendType" SG_ 1420 M10_Text_2_Hybrid 0;
BA_ "GenSigAutoGenSnd" SG_ 1420 M10_Text_2_Hybrid 1;
BA_ "GenSigAutoGenDsp" SG_ 1420 M10_Text_2_Hybrid 1;
BA_ "GenSigSwitchedByIgnition" SG_ 1420 M10_Text_3_Hybrid 0;
BA_ "GenSigSendType" SG_ 1420 M10_Text_3_Hybrid 0;
BA_ "GenSigAutoGenSnd" SG_ 1420 M10_Text_3_Hybrid 1;
BA_ "GenSigAutoGenDsp" SG_ 1420 M10_Text_3_Hybrid 1;
BA_ "GenSigSwitchedByIgnition" SG_ 1420 M10_Text_4_Hybrid 0;
BA_ "GenSigSendType" SG_ 1420 M10_Text_4_Hybrid 0;
BA_ "GenSigAutoGenSnd" SG_ 1420 M10_Text_4_Hybrid 1;
BA_ "GenSigAutoGenDsp" SG_ 1420 M10_Text_4_Hybrid 1;
BA_ "GenSigSwitchedByIgnition" SG_ 1420 M10_Text_5_Hybrid 0;
BA_ "GenSigSendType" SG_ 1420 M10_Text_5_Hybrid 0;
BA_ "GenSigAutoGenSnd" SG_ 1420 M10_Text_5_Hybrid 1;
BA_ "GenSigAutoGenDsp" SG_ 1420 M10_Text_5_Hybrid 1;
BA_ "GenSigSwitchedByIgnition" SG_ 1420 M10_Text_6_Hybrid 0;
BA_ "GenSigSendType" SG_ 1420 M10_Text_6_Hybrid 0;
BA_ "GenSigAutoGenSnd" SG_ 1420 M10_Text_6_Hybrid 1;
BA_ "GenSigAutoGenDsp" SG_ 1420 M10_Text_6_Hybrid 1;
BA_ "GenSigSwitchedByIgnition" SG_ 1420 M10_Text_7_Hybrid 0;
BA_ "GenSigSendType" SG_ 1420 M10_Text_7_Hybrid 0;
BA_ "GenSigAutoGenSnd" SG_ 1420 M10_Text_7_Hybrid 1;
BA_ "GenSigAutoGenDsp" SG_ 1420 M10_Text_7_Hybrid 1;
BA_ "GenSigSwitchedByIgnition" SG_ 1420 M10_Text_8_Hybrid 0;
BA_ "GenSigSendType" SG_ 1420 M10_Text_8_Hybrid 0;
BA_ "GenSigAutoGenSnd" SG_ 1420 M10_Text_8_Hybrid 1;
BA_ "GenSigAutoGenDsp" SG_ 1420 M10_Text_8_Hybrid 1;
BA_ "GenSigSwitchedByIgnition" SG_ 1420 M10_ShiftLockLampe 0;
BA_ "GenSigSendType" SG_ 1420 M10_ShiftLockLampe 0;
BA_ "GenSigAutoGenSnd" SG_ 1420 M10_ShiftLockLampe 1;
BA_ "GenSigAutoGenDsp" SG_ 1420 M10_ShiftLockLampe 1;
BA_ "GenSigSwitchedByIgnition" SG_ 1420 MO_Auth_Aufforderung_WFS 0;
BA_ "GenSigSendType" SG_ 1420 MO_Auth_Aufforderung_WFS 3;
BA_ "GenSigSwitchedByIgnition" SG_ 1420 M10_BMSInfo_gue 0;
BA_ "GenSigSendType" SG_ 1420 M10_BMSInfo_gue 0;
BA_ "GenSigAutoGenSnd" SG_ 1420 M10_BMSInfo_gue 1;
BA_ "GenSigAutoGenDsp" SG_ 1420 M10_BMSInfo_gue 1;
BA_ "GenSigSwitchedByIgnition" SG_ 1420 M10_VentilationReq 0;
BA_ "GenSigSendType" SG_ 1420 M10_VentilationReq 0;
BA_ "GenSigAutoGenSnd" SG_ 1420 M10_VentilationReq 1;
BA_ "GenSigAutoGenDsp" SG_ 1420 M10_VentilationReq 1;
BA_ "Fehlerwert" SG_ 1420 M10_BattFanSpd 15;
BA_ "GenSigSwitchedByIgnition" SG_ 1420 M10_BattFanSpd 0;
BA_ "GenSigStartValue" SG_ 1420 M10_BattFanSpd 14;
BA_ "GenSigSendType" SG_ 1420 M10_BattFanSpd 0;
BA_ "GenSigAutoGenSnd" SG_ 1420 M10_BattFanSpd 1;
BA_ "GenSigAutoGenDsp" SG_ 1420 M10_BattFanSpd 1;
BA_ "Fehlerwert" SG_ 1423 MO_ITM_Kuehlmittel_Temp 2;
BA_ "GenSigSwitchedByIgnition" SG_ 1423 MO_ITM_Kuehlmittel_Temp 0;
BA_ "GenSigStartValue" SG_ 1423 MO_ITM_Kuehlmittel_Temp 1;
BA_ "GenSigSendType" SG_ 1423 MO_ITM_Kuehlmittel_Temp 0;
BA_ "Fehlerwert" SG_ 1423 M12_E85_Sensor 15;
BA_ "GenSigSwitchedByIgnition" SG_ 1423 M12_E85_Sensor 0;
BA_ "GenSigStartValue" SG_ 1423 M12_E85_Sensor 14;
BA_ "GenSigSendType" SG_ 1423 M12_E85_Sensor 0;
BA_ "GenSigSwitchedByIgnition" SG_ 1423 M12_SCR_Anz_Motorstarts 0;
BA_ "GenSigStartValue" SG_ 1423 M12_SCR_Anz_Motorstarts 15;
BA_ "GenSigSendType" SG_ 1423 M12_SCR_Anz_Motorstarts 0;
BA_ "GenSigAutoGenSnd" SG_ 1423 M12_SCR_Anz_Motorstarts 1;
BA_ "GenSigAutoGenDsp" SG_ 1423 M12_SCR_Anz_Motorstarts 1;
BA_ "GenSigSwitchedByIgnition" SG_ 1423 M12_SCR_Reichweite 0;
BA_ "GenSigStartValue" SG_ 1423 M12_SCR_Reichweite 32767;
BA_ "GenSigSendType" SG_ 1423 M12_SCR_Reichweite 0;
BA_ "GenSigAutoGenSnd" SG_ 1423 M12_SCR_Reichweite 1;
BA_ "GenSigAutoGenDsp" SG_ 1423 M12_SCR_Reichweite 1;
BA_ "GenSigSwitchedByIgnition" SG_ 1423 M12_SCR_Warnstufe_1 0;
BA_ "GenSigSendType" SG_ 1423 M12_SCR_Warnstufe_1 0;
BA_ "GenSigAutoGenSnd" SG_ 1423 M12_SCR_Warnstufe_1 1;
BA_ "GenSigAutoGenDsp" SG_ 1423 M12_SCR_Warnstufe_1 1;
BA_ "GenSigSwitchedByIgnition" SG_ 1423 M12_SCR_Warnstufe_2 0;
BA_ "GenSigSendType" SG_ 1423 M12_SCR_Warnstufe_2 0;
BA_ "GenSigAutoGenSnd" SG_ 1423 M12_SCR_Warnstufe_2 1;
BA_ "GenSigAutoGenDsp" SG_ 1423 M12_SCR_Warnstufe_2 1;
BA_ "GenSigSwitchedByIgnition" SG_ 1423 M12_SCR_Text 0;
BA_ "GenSigSendType" SG_ 1423 M12_SCR_Text 0;
BA_ "GenSigAutoGenSnd" SG_ 1423 M12_SCR_Text 1;
BA_ "GenSigAutoGenDsp" SG_ 1423 M12_SCR_Text 1;
BA_ "GenSigSwitchedByIgnition" SG_ 1423 M12_Akustik 0;
BA_ "GenSigSendType" SG_ 1423 M12_Akustik 0;
BA_ "GenSigAutoGenSnd" SG_ 1423 M12_Akustik 1;
BA_ "GenSigAutoGenDsp" SG_ 1423 M12_Akustik 1;
BA_ "GenSigSwitchedByIgnition" SG_ 1423 M12_Luftfilter_Lampe 0;
BA_ "GenSigSendType" SG_ 1423 M12_Luftfilter_Lampe 0;
BA_ "GenSigAutoGenSnd" SG_ 1423 M12_Luftfilter_Lampe 1;
BA_ "GenSigAutoGenDsp" SG_ 1423 M12_Luftfilter_Lampe 1;
BA_ "GenSigSwitchedByIgnition" SG_ 1423 M12_Kraftstofffilter_Wasser 0;
BA_ "GenSigSendType" SG_ 1423 M12_Kraftstofffilter_Wasser 0;
BA_ "GenSigAutoGenSnd" SG_ 1423 M12_Kraftstofffilter_Wasser 1;
BA_ "GenSigAutoGenDsp" SG_ 1423 M12_Kraftstofffilter_Wasser 1;
BA_ "GenSigSwitchedByIgnition" SG_ 1423 M12_SCR_Systemfehler 0;
BA_ "GenSigSendType" SG_ 1423 M12_SCR_Systemfehler 0;
BA_ "GenSigAutoGenSnd" SG_ 1423 M12_SCR_Systemfehler 1;
BA_ "GenSigAutoGenDsp" SG_ 1423 M12_SCR_Systemfehler 1;
BA_ "GenSigSwitchedByIgnition" SG_ 1423 M12_SCR_Inducement 0;
BA_ "GenSigSendType" SG_ 1423 M12_SCR_Inducement 0;
BA_ "GenSigAutoGenSnd" SG_ 1423 M12_SCR_Inducement 1;
BA_ "GenSigAutoGenDsp" SG_ 1423 M12_SCR_Inducement 1;
BA_ "Fehlerwert" SG_ 1423 M12_CO2_Faktor 4095;
BA_ "GenSigSwitchedByIgnition" SG_ 1423 M12_CO2_Faktor 0;
BA_ "GenSigSendType" SG_ 1423 M12_CO2_Faktor 0;
BA_ "GenSigAutoGenSnd" SG_ 1423 M12_CO2_Faktor 1;
BA_ "GenSigAutoGenDsp" SG_ 1423 M12_CO2_Faktor 1;
BA_ "GenSigSwitchedByIgnition" SG_ 1423 M12_MKB_MUX 0;
BA_ "GenSigSendType" SG_ 1423 M12_MKB_MUX 0;
BA_ "GenSigAutoGenSnd" SG_ 1423 M12_MKB_MUX 1;
BA_ "GenSigAutoGenDsp" SG_ 1423 M12_MKB_MUX 1;
BA_ "GenSigSwitchedByIgnition" SG_ 1423 M12_MKB_01 0;
BA_ "GenSigAutoGenSnd" SG_ 1423 M12_MKB_01 1;
BA_ "GenSigAutoGenDsp" SG_ 1423 M12_MKB_01 1;
BA_ "GenSigSwitchedByIgnition" SG_ 1423 M12_MKB_02 0;
BA_ "GenSigAutoGenSnd" SG_ 1423 M12_MKB_02 1;
BA_ "GenSigAutoGenDsp" SG_ 1423 M12_MKB_02 1;
BA_ "GenSigSwitchedByIgnition" SG_ 1423 M12_MKB_03 0;
BA_ "GenSigAutoGenSnd" SG_ 1423 M12_MKB_03 1;
BA_ "GenSigAutoGenDsp" SG_ 1423 M12_MKB_03 1;
BA_ "GenSigSwitchedByIgnition" SG_ 1423 M12_MKB_04 0;
BA_ "GenSigAutoGenSnd" SG_ 1423 M12_MKB_04 1;
BA_ "GenSigAutoGenDsp" SG_ 1423 M12_MKB_04 1;
BA_ "GenSigSwitchedByIgnition" SG_ 1450 MO_Heizungspumpenansteuerung 0;
BA_ "GenSigStartValue" SG_ 1450 MO_Heizungspumpenansteuerung 14;
BA_ "GenSigSendType" SG_ 1450 MO_Heizungspumpenansteuerung 0;
BA_ "GenSigAutoGenSnd" SG_ 1450 MO_Heizungspumpenansteuerung 1;
BA_ "GenSigAutoGenDsp" SG_ 1450 MO_Heizungspumpenansteuerung 1;
BA_ "GenSigSwitchedByIgnition" SG_ 1450 MO_Nachlaufzeit_Heizungspumpe 0;
BA_ "GenSigSendType" SG_ 1450 MO_Nachlaufzeit_Heizungspumpe 0;
BA_ "GenSigAutoGenSnd" SG_ 1450 MO_Nachlaufzeit_Heizungspumpe 1;
BA_ "GenSigAutoGenDsp" SG_ 1450 MO_Nachlaufzeit_Heizungspumpe 1;
BA_ "GenSigSwitchedByIgnition" SG_ 1450 MO_Absperrventil_oeffnen 0;
BA_ "GenSigSendType" SG_ 1450 MO_Absperrventil_oeffnen 0;
BA_ "GenSigAutoGenSnd" SG_ 1450 MO_Absperrventil_oeffnen 1;
BA_ "GenSigAutoGenDsp" SG_ 1450 MO_Absperrventil_oeffnen 1;
BA_ "GenSigSwitchedByIgnition" SG_ 1450 MO_aktives_Getriebeheizen 0;
BA_ "GenSigSendType" SG_ 1450 MO_aktives_Getriebeheizen 0;
BA_ "GenSigAutoGenSnd" SG_ 1450 MO_aktives_Getriebeheizen 1;
BA_ "GenSigAutoGenDsp" SG_ 1450 MO_aktives_Getriebeheizen 1;
BA_ "GenSigSwitchedByIgnition" SG_ 1450 MO_Getriebe_kuehlen 0;
BA_ "GenSigSendType" SG_ 1450 MO_Getriebe_kuehlen 0;
BA_ "GenSigAutoGenSnd" SG_ 1450 MO_Getriebe_kuehlen 1;
BA_ "GenSigAutoGenDsp" SG_ 1450 MO_Getriebe_kuehlen 1;
BA_ "GenSigSwitchedByIgnition" SG_ 1450 MO_Zustand_HWP 0;
BA_ "GenSigStartValue" SG_ 1450 MO_Zustand_HWP 1;
BA_ "GenSigSendType" SG_ 1450 MO_Zustand_HWP 0;
BA_ "GenSigAutoGenSnd" SG_ 1450 MO_Zustand_HWP 1;
BA_ "GenSigAutoGenDsp" SG_ 1450 MO_Zustand_HWP 1;
BA_ "GenSigSwitchedByIgnition" SG_ 1450 MO_BKV_Unterdruckwarnung 0;
BA_ "GenSigSendType" SG_ 1450 MO_BKV_Unterdruckwarnung 0;
BA_ "GenSigAutoGenSnd" SG_ 1450 MO_BKV_Unterdruckwarnung 1;
BA_ "GenSigAutoGenDsp" SG_ 1450 MO_BKV_Unterdruckwarnung 1;
BA_ "GenSigSwitchedByIgnition" SG_ 1450 MO_StartStopp_Codiert 0;
BA_ "GenSigFuncType" SG_ 1450 MO_StartStopp_Codiert 8;
BA_ "GenSigSendType" SG_ 1450 MO_StartStopp_Codiert 0;
BA_ "GenSigAutoGenSnd" SG_ 1450 MO_StartStopp_Codiert 1;
BA_ "GenSigAutoGenDsp" SG_ 1450 MO_StartStopp_Codiert 1;
BA_ "GenSigSwitchedByIgnition" SG_ 1450 MO_Zylinderabschaltung 0;
BA_ "GenSigSendType" SG_ 1450 MO_Zylinderabschaltung 3;
BA_ "Fehlerwert" SG_ 1450 MO_Heizstrom_SCR 63;
BA_ "GenSigSwitchedByIgnition" SG_ 1450 MO_Heizstrom_SCR 0;
BA_ "GenSigSendType" SG_ 1450 MO_Heizstrom_SCR 0;
BA_ "Fehlerwert" SG_ 1450 MO_Heizstrom_EKAT 127;
BA_ "GenSigSwitchedByIgnition" SG_ 1450 MO_Heizstrom_EKAT 0;
BA_ "GenSigSendType" SG_ 1450 MO_Heizstrom_EKAT 0;
BA_ "GenSigSwitchedByIgnition" SG_ 1450 MO_Ext_E_Fahrt_aktiv 0;
BA_ "GenSigSendType" SG_ 1450 MO_Ext_E_Fahrt_aktiv 3;
BA_ "GenSigAutoGenSnd" SG_ 1450 MO_Ext_E_Fahrt_aktiv 1;
BA_ "GenSigAutoGenDsp" SG_ 1450 MO_Ext_E_Fahrt_aktiv 1;
BA_ "GenSigSwitchedByIgnition" SG_ 1450 MO_E85_WU_Lampe 0;
BA_ "GenSigSendType" SG_ 1450 MO_E85_WU_Lampe 3;
BA_ "GenSigSwitchedByIgnition" SG_ 1450 MO_E85_WU_Texte 0;
BA_ "GenSigSendType" SG_ 1450 MO_E85_WU_Texte 3;
BA_ "GenSigSwitchedByIgnition" SG_ 1450 MO_Zylabsch_Texte 0;
BA_ "GenSigSendType" SG_ 1450 MO_Zylabsch_Texte 3;
BA_ "GenSigSwitchedByIgnition" SG_ 1450 MO_E85_BS_Texte 0;
BA_ "GenSigSendType" SG_ 1450 MO_E85_BS_Texte 3;
BA_ "GenSigSwitchedByIgnition" SG_ 1407 MO_Charisma_FahrPr 0;
BA_ "GenSigSendType" SG_ 1407 MO_Charisma_FahrPr 0;
BA_ "GenSigEnvVarType" SG_ 1407 MO_Charisma_FahrPr 0;
BA_ "GenSigAutoGenSnd" SG_ 1407 MO_Charisma_FahrPr 1;
BA_ "GenSigAutoGenDsp" SG_ 1407 MO_Charisma_FahrPr 1;
BA_ "GenSigSwitchedByIgnition" SG_ 1407 MO_Charisma_Status 0;
BA_ "GenSigSendType" SG_ 1407 MO_Charisma_Status 0;
BA_ "GenSigEnvVarType" SG_ 1407 MO_Charisma_Status 0;
BA_ "GenSigAutoGenSnd" SG_ 1407 MO_Charisma_Status 1;
BA_ "GenSigAutoGenDsp" SG_ 1407 MO_Charisma_Status 1;
BA_ "GenSigSwitchedByIgnition" SG_ 1407 GE_Charisma_FahrPr 0;
BA_ "GenSigSendType" SG_ 1407 GE_Charisma_FahrPr 0;
BA_ "GenSigEnvVarType" SG_ 1407 GE_Charisma_FahrPr 0;
BA_ "GenSigAutoGenSnd" SG_ 1407 GE_Charisma_FahrPr 1;
BA_ "GenSigAutoGenDsp" SG_ 1407 GE_Charisma_FahrPr 1;
BA_ "GenSigSwitchedByIgnition" SG_ 1407 GE_Charisma_Status 0;
BA_ "GenSigSendType" SG_ 1407 GE_Charisma_Status 0;
BA_ "GenSigEnvVarType" SG_ 1407 GE_Charisma_Status 0;
BA_ "GenSigAutoGenSnd" SG_ 1407 GE_Charisma_Status 1;
BA_ "GenSigAutoGenDsp" SG_ 1407 GE_Charisma_Status 1;
BA_ "GenSigSwitchedByIgnition" SG_ 1407 MO_Bremslicht_Reku 0;
BA_ "GenSigSendType" SG_ 1407 MO_Bremslicht_Reku 0;
BA_ "GenSigAutoGenSnd" SG_ 1407 MO_Bremslicht_Reku 1;
BA_ "GenSigAutoGenDsp" SG_ 1407 MO_Bremslicht_Reku 1;
BA_ "GenSigSwitchedByIgnition" SG_ 1407 MO_Verbrauch_EM 0;
BA_ "GenSigSendType" SG_ 1407 MO_Verbrauch_EM 0;
BA_ "GenSigAutoGenSnd" SG_ 1407 MO_Verbrauch_EM 1;
BA_ "GenSigAutoGenDsp" SG_ 1407 MO_Verbrauch_EM 1;
BA_ "GenSigSwitchedByIgnition" SG_ 1407 MO_UeberlVerb_EM 0;
BA_ "GenSigSendType" SG_ 1407 MO_UeberlVerb_EM 0;
BA_ "GenSigAutoGenSnd" SG_ 1407 MO_UeberlVerb_EM 1;
BA_ "GenSigAutoGenDsp" SG_ 1407 MO_UeberlVerb_EM 1;
BA_ "GenSigSwitchedByIgnition" SG_ 1407 MO_Rekuperation_EM 0;
BA_ "GenSigSendType" SG_ 1407 MO_Rekuperation_EM 0;
BA_ "GenSigAutoGenSnd" SG_ 1407 MO_Rekuperation_EM 1;
BA_ "GenSigAutoGenDsp" SG_ 1407 MO_Rekuperation_EM 1;
BA_ "GenSigSwitchedByIgnition" SG_ 1407 MO_UeberlReku_EM 0;
BA_ "GenSigSendType" SG_ 1407 MO_UeberlReku_EM 0;
BA_ "GenSigAutoGenSnd" SG_ 1407 MO_UeberlReku_EM 1;
BA_ "GenSigAutoGenDsp" SG_ 1407 MO_UeberlReku_EM 1;
BA_ "GenSigSwitchedByIgnition" SG_ 1407 MO_Verbrauch_NA 0;
BA_ "GenSigSendType" SG_ 1407 MO_Verbrauch_NA 0;
BA_ "GenSigAutoGenSnd" SG_ 1407 MO_Verbrauch_NA 1;
BA_ "GenSigAutoGenDsp" SG_ 1407 MO_Verbrauch_NA 1;
BA_ "GenSigSwitchedByIgnition" SG_ 1407 MO_UeberlVerb_NA 0;
BA_ "GenSigSendType" SG_ 1407 MO_UeberlVerb_NA 0;
BA_ "GenSigAutoGenSnd" SG_ 1407 MO_UeberlVerb_NA 1;
BA_ "GenSigAutoGenDsp" SG_ 1407 MO_UeberlVerb_NA 1;
BA_ "GenSigSwitchedByIgnition" SG_ 648 MO2_CAN_Vers 0;
BA_ "GenSigAutoGenSnd" SG_ 648 MO2_CAN_Vers 1;
BA_ "GenSigAutoGenDsp" SG_ 648 MO2_CAN_Vers 1;
BA_ "GenSigSwitchedByIgnition" SG_ 648 MO2_Motor_Code 0;
BA_ "GenSigAutoGenSnd" SG_ 648 MO2_Motor_Code 1;
BA_ "GenSigAutoGenDsp" SG_ 648 MO2_Motor_Code 1;
BA_ "GenSigSwitchedByIgnition" SG_ 648 MO2_Getr_Code 0;
BA_ "GenSigAutoGenSnd" SG_ 648 MO2_Getr_Code 1;
BA_ "GenSigAutoGenDsp" SG_ 648 MO2_Getr_Code 1;
BA_ "GenSigSwitchedByIgnition" SG_ 648 MO2_max_Mo 0;
BA_ "GenSigAutoGenSnd" SG_ 648 MO2_max_Mo 1;
BA_ "GenSigAutoGenDsp" SG_ 648 MO2_max_Mo 1;
BA_ "GenSigSwitchedByIgnition" SG_ 648 MO2_Mp_Code 0;
BA_ "GenSigSendType" SG_ 648 MO2_Mp_Code 0;
BA_ "GenSigAutoGenSnd" SG_ 648 MO2_Mp_Code 1;
BA_ "GenSigAutoGenDsp" SG_ 648 MO2_Mp_Code 1;
BA_ "Fehlerwert" SG_ 648 MO2_Kuehlm_T 255;
BA_ "GenSigSwitchedByIgnition" SG_ 648 MO2_Kuehlm_T 0;
BA_ "GenSigSendType" SG_ 648 MO2_Kuehlm_T 0;
BA_ "GenSigAutoGenSnd" SG_ 648 MO2_Kuehlm_T 1;
BA_ "GenSigAutoGenDsp" SG_ 648 MO2_Kuehlm_T 1;
BA_ "GenSigSwitchedByIgnition" SG_ 648 MO2_BLS 0;
BA_ "GenSigSendType" SG_ 648 MO2_BLS 0;
BA_ "GenSigAutoGenSnd" SG_ 648 MO2_BLS 1;
BA_ "GenSigAutoGenDsp" SG_ 648 MO2_BLS 1;
BA_ "GenSigSwitchedByIgnition" SG_ 648 MO2_BTS 0;
BA_ "GenSigSendType" SG_ 648 MO2_BTS 0;
BA_ "GenSigAutoGenSnd" SG_ 648 MO2_BTS 1;
BA_ "GenSigAutoGenDsp" SG_ 648 MO2_BTS 1;
BA_ "GenSigSwitchedByIgnition" SG_ 648 MO2_Sta_Kuehlm 0;
BA_ "GenSigSendType" SG_ 648 MO2_Sta_Kuehlm 0;
BA_ "GenSigAutoGenSnd" SG_ 648 MO2_Sta_Kuehlm 1;
BA_ "GenSigAutoGenDsp" SG_ 648 MO2_Sta_Kuehlm 1;
BA_ "GenSigSwitchedByIgnition" SG_ 648 MO2_Sta_Klima 0;
BA_ "GenSigSendType" SG_ 648 MO2_Sta_Klima 0;
BA_ "GenSigAutoGenSnd" SG_ 648 MO2_Sta_Klima 1;
BA_ "GenSigAutoGenDsp" SG_ 648 MO2_Sta_Klima 1;
BA_ "GenSigSwitchedByIgnition" SG_ 648 MO2_Sta_No_Bet 0;
BA_ "GenSigSendType" SG_ 648 MO2_Sta_No_Bet 0;
BA_ "GenSigAutoGenSnd" SG_ 648 MO2_Sta_No_Bet 1;
BA_ "GenSigAutoGenDsp" SG_ 648 MO2_Sta_No_Bet 1;
BA_ "GenSigSwitchedByIgnition" SG_ 648 MO2_Status_TSK 0;
BA_ "GenSigSendType" SG_ 648 MO2_Status_TSK 0;
BA_ "GenSigAutoGenSnd" SG_ 648 MO2_Status_TSK 1;
BA_ "GenSigAutoGenDsp" SG_ 648 MO2_Status_TSK 1;
BA_ "GenSigSwitchedByIgnition" SG_ 648 MO2_Sta_GRA 0;
BA_ "GenSigSendType" SG_ 648 MO2_Sta_GRA 0;
BA_ "GenSigAutoGenSnd" SG_ 648 MO2_Sta_GRA 1;
BA_ "GenSigAutoGenDsp" SG_ 648 MO2_Sta_GRA 1;
BA_ "Fehlerwert" SG_ 648 MO2_Sta_Limiter 3;
BA_ "GenSigSwitchedByIgnition" SG_ 648 MO2_Sta_Limiter 0;
BA_ "GenSigSendType" SG_ 648 MO2_Sta_Limiter 0;
BA_ "GenSigAutoGenSnd" SG_ 648 MO2_Sta_Limiter 1;
BA_ "GenSigAutoGenDsp" SG_ 648 MO2_Sta_Limiter 1;
BA_ "GenSigSwitchedByIgnition" SG_ 648 MO2_GRAregelt 0;
BA_ "GenSigSendType" SG_ 648 MO2_GRAregelt 0;
BA_ "GenSigAutoGenSnd" SG_ 648 MO2_GRAregelt 1;
BA_ "GenSigAutoGenDsp" SG_ 648 MO2_GRAregelt 1;
BA_ "Fehlerwert" SG_ 648 MO2_Sport_Error 1;
BA_ "GenSigSwitchedByIgnition" SG_ 648 MO2_Sport_Error 0;
BA_ "GenSigSendType" SG_ 648 MO2_Sport_Error 0;
BA_ "GenSigAutoGenSnd" SG_ 648 MO2_Sport_Error 1;
BA_ "GenSigAutoGenDsp" SG_ 648 MO2_Sport_Error 1;
BA_ "GenSigSwitchedByIgnition" SG_ 648 MO2_OffRoad 0;
BA_ "GenSigSendType" SG_ 648 MO2_OffRoad 0;
BA_ "GenSigAutoGenSnd" SG_ 648 MO2_OffRoad 1;
BA_ "GenSigAutoGenDsp" SG_ 648 MO2_OffRoad 1;
BA_ "Fehlerwert" SG_ 648 MO2_RME_Gehalt 7;
BA_ "GenSigSwitchedByIgnition" SG_ 648 MO2_RME_Gehalt 0;
BA_ "GenSigSendType" SG_ 648 MO2_RME_Gehalt 0;
BA_ "GenSigAutoGenSnd" SG_ 648 MO2_RME_Gehalt 1;
BA_ "GenSigAutoGenDsp" SG_ 648 MO2_RME_Gehalt 1;
BA_ "Fehlerwert" SG_ 648 MO2_GRA_Soll 255;
BA_ "GenSigSwitchedByIgnition" SG_ 648 MO2_GRA_Soll 0;
BA_ "GenSigSendType" SG_ 648 MO2_GRA_Soll 0;
BA_ "GenSigAutoGenSnd" SG_ 648 MO2_GRA_Soll 1;
BA_ "GenSigAutoGenDsp" SG_ 648 MO2_GRA_Soll 1;
BA_ "Fehlerwert" SG_ 648 MO2_LL_Solldz 255;
BA_ "GenSigSwitchedByIgnition" SG_ 648 MO2_LL_Solldz 0;
BA_ "GenSigSendType" SG_ 648 MO2_LL_Solldz 0;
BA_ "GenSigAutoGenSnd" SG_ 648 MO2_LL_Solldz 1;
BA_ "GenSigAutoGenDsp" SG_ 648 MO2_LL_Solldz 1;
BA_ "Fehlerwert" SG_ 648 MO2_Begr_Mo 255;
BA_ "GenSigSwitchedByIgnition" SG_ 648 MO2_Begr_Mo 0;
BA_ "GenSigStartValue" SG_ 648 MO2_Begr_Mo 254;
BA_ "GenSigSendType" SG_ 648 MO2_Begr_Mo 0;
BA_ "GenSigAutoGenSnd" SG_ 648 MO2_Begr_Mo 1;
BA_ "GenSigAutoGenDsp" SG_ 648 MO2_Begr_Mo 1;
BA_ "Fehlerwert" SG_ 648 MO2_Mo_ZWR 255;
BA_ "GenSigSwitchedByIgnition" SG_ 648 MO2_Mo_ZWR 0;
BA_ "GenSigSendType" SG_ 648 MO2_Mo_ZWR 0;
BA_ "GenSigAutoGenSnd" SG_ 648 MO2_Mo_ZWR 1;
BA_ "GenSigAutoGenDsp" SG_ 648 MO2_Mo_ZWR 1;
BA_ "GenSigSwitchedByIgnition" SG_ 896 MO3_Vorgluehen 0;
BA_ "GenSigSendType" SG_ 896 MO3_Vorgluehen 0;
BA_ "GenSigAutoGenSnd" SG_ 896 MO3_Vorgluehen 1;
BA_ "GenSigAutoGenDsp" SG_ 896 MO3_Vorgluehen 1;
BA_ "GenSigSwitchedByIgnition" SG_ 896 MO3_Prio_Dz 0;
BA_ "GenSigSendType" SG_ 896 MO3_Prio_Dz 0;
BA_ "GenSigAutoGenSnd" SG_ 896 MO3_Prio_Dz 1;
BA_ "GenSigAutoGenDsp" SG_ 896 MO3_Prio_Dz 1;
BA_ "GenSigSwitchedByIgnition" SG_ 896 MO_Schalter_StartStopp 0;
BA_ "GenSigStartValue" SG_ 896 MO_Schalter_StartStopp 1;
BA_ "GenSigSendType" SG_ 896 MO_Schalter_StartStopp 0;
BA_ "GenSigEnvVarType" SG_ 896 MO_Schalter_StartStopp 0;
BA_ "GenSigSwitchedByIgnition" SG_ 896 MO3_Winterprg 0;
BA_ "GenSigSendType" SG_ 896 MO3_Winterprg 0;
BA_ "GenSigAutoGenSnd" SG_ 896 MO3_Winterprg 1;
BA_ "GenSigAutoGenDsp" SG_ 896 MO3_Winterprg 1;
BA_ "GenSigSwitchedByIgnition" SG_ 896 MO3_Sta_Pedal 0;
BA_ "GenSigSendType" SG_ 896 MO3_Sta_Pedal 0;
BA_ "GenSigAutoGenSnd" SG_ 896 MO3_Sta_Pedal 1;
BA_ "GenSigAutoGenDsp" SG_ 896 MO3_Sta_Pedal 1;
BA_ "GenSigSwitchedByIgnition" SG_ 896 MO3_Sta_FPG 0;
BA_ "GenSigSendType" SG_ 896 MO3_Sta_FPG 0;
BA_ "GenSigAutoGenSnd" SG_ 896 MO3_Sta_FPG 1;
BA_ "GenSigAutoGenDsp" SG_ 896 MO3_Sta_FPG 1;
BA_ "GenSigSwitchedByIgnition" SG_ 896 MO3_Sign_FPG 0;
BA_ "GenSigAutoGenSnd" SG_ 896 MO3_Sign_FPG 1;
BA_ "GenSigAutoGenDsp" SG_ 896 MO3_Sign_FPG 1;
BA_ "GenSigSwitchedByIgnition" SG_ 896 MO3_Sta_Temp 0;
BA_ "GenSigSendType" SG_ 896 MO3_Sta_Temp 0;
BA_ "GenSigAutoGenSnd" SG_ 896 MO3_Sta_Temp 1;
BA_ "GenSigAutoGenDsp" SG_ 896 MO3_Sta_Temp 1;
BA_ "Fehlerwert" SG_ 896 MO3_Aussentemp 255;
BA_ "GenSigSwitchedByIgnition" SG_ 896 MO3_Aussentemp 0;
BA_ "GenSigSendType" SG_ 896 MO3_Aussentemp 0;
BA_ "GenSigAutoGenSnd" SG_ 896 MO3_Aussentemp 1;
BA_ "GenSigAutoGenDsp" SG_ 896 MO3_Aussentemp 1;
BA_ "Fehlerwert" SG_ 896 MO3_Pedalwert 255;
BA_ "GenSigSwitchedByIgnition" SG_ 896 MO3_Pedalwert 0;
BA_ "GenSigSendType" SG_ 896 MO3_Pedalwert 0;
BA_ "GenSigAutoGenSnd" SG_ 896 MO3_Pedalwert 1;
BA_ "GenSigAutoGenDsp" SG_ 896 MO3_Pedalwert 1;
BA_ "Fehlerwert" SG_ 896 MO3_Rad_Wu_Mo 4095;
BA_ "GenSigSwitchedByIgnition" SG_ 896 MO3_Rad_Wu_Mo 0;
BA_ "GenSigSendType" SG_ 896 MO3_Rad_Wu_Mo 0;
BA_ "GenSigAutoGenSnd" SG_ 896 MO3_Rad_Wu_Mo 1;
BA_ "GenSigAutoGenDsp" SG_ 896 MO3_Rad_Wu_Mo 1;
BA_ "GenSigSwitchedByIgnition" SG_ 896 MO3_Vorz_RadWu 0;
BA_ "GenSigSendType" SG_ 896 MO3_Vorz_RadWu 0;
BA_ "GenSigAutoGenSnd" SG_ 896 MO3_Vorz_RadWu 1;
BA_ "GenSigAutoGenDsp" SG_ 896 MO3_Vorz_RadWu 1;
BA_ "GenSigSwitchedByIgnition" SG_ 896 MO3_Freigabe_Segeln 0;
BA_ "GenSigSendType" SG_ 896 MO3_Freigabe_Segeln 0;
BA_ "GenSigSwitchedByIgnition" SG_ 896 MO3_Dz_Beeinfl 0;
BA_ "GenSigSendType" SG_ 896 MO3_Dz_Beeinfl 0;
BA_ "GenSigAutoGenSnd" SG_ 896 MO3_Dz_Beeinfl 1;
BA_ "GenSigAutoGenDsp" SG_ 896 MO3_Dz_Beeinfl 1;
BA_ "Fehlerwert" SG_ 896 MO3_WunschDz 255;
BA_ "GenSigSwitchedByIgnition" SG_ 896 MO3_WunschDz 0;
BA_ "GenSigSendType" SG_ 896 MO3_WunschDz 0;
BA_ "GenSigAutoGenSnd" SG_ 896 MO3_WunschDz 1;
BA_ "GenSigAutoGenDsp" SG_ 896 MO3_WunschDz 1;
BA_ "Fehlerwert" SG_ 896 MO3_DKW 255;
BA_ "GenSigSwitchedByIgnition" SG_ 896 MO3_DKW 0;
BA_ "GenSigAutoGenSnd" SG_ 896 MO3_DKW 1;
BA_ "GenSigAutoGenDsp" SG_ 896 MO3_DKW 1;
BA_ "Fehlerwert" SG_ 896 MO3_FPGradient 255;
BA_ "GenSigSwitchedByIgnition" SG_ 896 MO3_FPGradient 0;
BA_ "GenSigAutoGenSnd" SG_ 896 MO3_FPGradient 1;
BA_ "GenSigAutoGenDsp" SG_ 896 MO3_FPGradient 1;
BA_ "GenSigSwitchedByIgnition" SG_ 1152 MO5_max_Moment 0;
BA_ "GenSigAutoGenSnd" SG_ 1152 MO5_max_Moment 1;
BA_ "GenSigAutoGenDsp" SG_ 1152 MO5_max_Moment 1;
BA_ "GenSigSwitchedByIgnition" SG_ 1152 MO5_Drehzahl 0;
BA_ "GenSigAutoGenSnd" SG_ 1152 MO5_Drehzahl 1;
BA_ "GenSigAutoGenDsp" SG_ 1152 MO5_Drehzahl 1;
BA_ "GenSigSwitchedByIgnition" SG_ 1152 MO5_Motortyp 0;
BA_ "GenSigAutoGenSnd" SG_ 1152 MO5_Motortyp 1;
BA_ "GenSigAutoGenDsp" SG_ 1152 MO5_Motortyp 1;
BA_ "GenSigSwitchedByIgnition" SG_ 1152 MO5_Abgastyp 0;
BA_ "GenSigAutoGenSnd" SG_ 1152 MO5_Abgastyp 1;
BA_ "GenSigAutoGenDsp" SG_ 1152 MO5_Abgastyp 1;
BA_ "GenSigSwitchedByIgnition" SG_ 1152 MO5_Abgastyp2 0;
BA_ "GenSigAutoGenSnd" SG_ 1152 MO5_Abgastyp2 1;
BA_ "GenSigAutoGenDsp" SG_ 1152 MO5_Abgastyp2 1;
BA_ "GenSigSwitchedByIgnition" SG_ 1152 MO5_Abgastyp3 0;
BA_ "GenSigAutoGenSnd" SG_ 1152 MO5_Abgastyp3 1;
BA_ "GenSigAutoGenDsp" SG_ 1152 MO5_Abgastyp3 1;
BA_ "GenSigSwitchedByIgnition" SG_ 1152 OBD_Kaltstart_Denominator 0;
BA_ "GenSigSwitchedByIgnition" SG_ 1152 OBD_Minimum_Trip 0;
BA_ "GenSigSwitchedByIgnition" SG_ 1152 MO5_DPF_reg 0;
BA_ "GenSigAutoGenSnd" SG_ 1152 MO5_DPF_reg 1;
BA_ "GenSigAutoGenDsp" SG_ 1152 MO5_DPF_reg 1;
BA_ "GenSigSwitchedByIgnition" SG_ 1152 MO5_Mp_Code 0;
BA_ "GenSigSendType" SG_ 1152 MO5_Mp_Code 0;
BA_ "GenSigAutoGenSnd" SG_ 1152 MO5_Mp_Code 1;
BA_ "GenSigAutoGenDsp" SG_ 1152 MO5_Mp_Code 1;
BA_ "GenSigSwitchedByIgnition" SG_ 1152 MO5_Vorgluehen 0;
BA_ "GenSigSendType" SG_ 1152 MO5_Vorgluehen 0;
BA_ "GenSigAutoGenSnd" SG_ 1152 MO5_Vorgluehen 1;
BA_ "GenSigAutoGenDsp" SG_ 1152 MO5_Vorgluehen 1;
BA_ "GenSigSwitchedByIgnition" SG_ 1152 MO5_E_Gas 0;
BA_ "GenSigSendType" SG_ 1152 MO5_E_Gas 0;
BA_ "GenSigAutoGenSnd" SG_ 1152 MO5_E_Gas 1;
BA_ "GenSigAutoGenDsp" SG_ 1152 MO5_E_Gas 1;
BA_ "GenSigSwitchedByIgnition" SG_ 1152 MO5_OBD_2 0;
BA_ "GenSigSendType" SG_ 1152 MO5_OBD_2 0;
BA_ "GenSigAutoGenSnd" SG_ 1152 MO5_OBD_2 1;
BA_ "GenSigAutoGenDsp" SG_ 1152 MO5_OBD_2 1;
BA_ "GenSigSwitchedByIgnition" SG_ 1152 MO5_Heissl 0;
BA_ "GenSigSendType" SG_ 1152 MO5_Heissl 0;
BA_ "GenSigAutoGenSnd" SG_ 1152 MO5_Heissl 1;
BA_ "GenSigAutoGenDsp" SG_ 1152 MO5_Heissl 1;
BA_ "GenSigSwitchedByIgnition" SG_ 1152 MO5_KlimaKompr 0;
BA_ "GenSigSendType" SG_ 1152 MO5_KlimaKompr 0;
BA_ "GenSigAutoGenSnd" SG_ 1152 MO5_KlimaKompr 1;
BA_ "GenSigAutoGenDsp" SG_ 1152 MO5_KlimaKompr 1;
BA_ "GenSigSwitchedByIgnition" SG_ 1152 MO5_Feld_kuehl 0;
BA_ "GenSigSendType" SG_ 1152 MO5_Feld_kuehl 0;
BA_ "GenSigAutoGenSnd" SG_ 1152 MO5_Feld_kuehl 1;
BA_ "GenSigAutoGenDsp" SG_ 1152 MO5_Feld_kuehl 1;
BA_ "GenSigSwitchedByIgnition" SG_ 1152 MO5_KliKo_Red 0;
BA_ "GenSigSendType" SG_ 1152 MO5_KliKo_Red 0;
BA_ "GenSigAutoGenSnd" SG_ 1152 MO5_KliKo_Red 1;
BA_ "GenSigAutoGenDsp" SG_ 1152 MO5_KliKo_Red 1;
BA_ "GenSigSwitchedByIgnition" SG_ 1152 MO5_Verbrauch 0;
BA_ "GenSigSendType" SG_ 1152 MO5_Verbrauch 0;
BA_ "GenSigAutoGenSnd" SG_ 1152 MO5_Verbrauch 1;
BA_ "GenSigAutoGenDsp" SG_ 1152 MO5_Verbrauch 1;
BA_ "GenSigSwitchedByIgnition" SG_ 1152 MO5_UeberlVerb 0;
BA_ "GenSigSendType" SG_ 1152 MO5_UeberlVerb 0;
BA_ "GenSigAutoGenSnd" SG_ 1152 MO5_UeberlVerb 1;
BA_ "GenSigAutoGenDsp" SG_ 1152 MO5_UeberlVerb 1;
BA_ "Fehlerwert" SG_ 1152 MO5_Luefter 255;
BA_ "GenSigSwitchedByIgnition" SG_ 1152 MO5_Luefter 0;
BA_ "GenSigSendType" SG_ 1152 MO5_Luefter 0;
BA_ "GenSigAutoGenSnd" SG_ 1152 MO5_Luefter 1;
BA_ "GenSigAutoGenDsp" SG_ 1152 MO5_Luefter 1;
BA_ "GenSigSwitchedByIgnition" SG_ 1152 MO5_HLeuchte 0;
BA_ "GenSigSendType" SG_ 1152 MO5_HLeuchte 0;
BA_ "GenSigAutoGenSnd" SG_ 1152 MO5_HLeuchte 1;
BA_ "GenSigAutoGenDsp" SG_ 1152 MO5_HLeuchte 1;
BA_ "GenSigSwitchedByIgnition" SG_ 1152 MO5_PartikelLamp 0;
BA_ "GenSigSendType" SG_ 1152 MO5_PartikelLamp 0;
BA_ "GenSigAutoGenSnd" SG_ 1152 MO5_PartikelLamp 1;
BA_ "GenSigAutoGenDsp" SG_ 1152 MO5_PartikelLamp 1;
BA_ "GenSigSwitchedByIgnition" SG_ 1152 MO5_Sta_BKU 0;
BA_ "GenSigSendType" SG_ 1152 MO5_Sta_BKU 0;
BA_ "GenSigAutoGenSnd" SG_ 1152 MO5_Sta_BKU 1;
BA_ "GenSigAutoGenDsp" SG_ 1152 MO5_Sta_BKU 1;
BA_ "GenSigSwitchedByIgnition" SG_ 1152 MO5_TypStartSteu 0;
BA_ "GenSigSendType" SG_ 1152 MO5_TypStartSteu 0;
BA_ "GenSigAutoGenSnd" SG_ 1152 MO5_TypStartSteu 1;
BA_ "GenSigAutoGenDsp" SG_ 1152 MO5_TypStartSteu 1;
BA_ "GenSigSwitchedByIgnition" SG_ 1152 MO5_TDE_Lampe 0;
BA_ "GenSigSendType" SG_ 1152 MO5_TDE_Lampe 0;
BA_ "GenSigAutoGenSnd" SG_ 1152 MO5_TDE_Lampe 1;
BA_ "GenSigAutoGenDsp" SG_ 1152 MO5_TDE_Lampe 1;
BA_ "GenSigSwitchedByIgnition" SG_ 1152 MO5_TDE_Text 0;
BA_ "GenSigSendType" SG_ 1152 MO5_TDE_Text 0;
BA_ "GenSigAutoGenSnd" SG_ 1152 MO5_TDE_Text 1;
BA_ "GenSigAutoGenDsp" SG_ 1152 MO5_TDE_Text 1;
BA_ "GenSigSwitchedByIgnition" SG_ 1152 MO5_DZM_Daempf 0;
BA_ "GenSigSendType" SG_ 1152 MO5_DZM_Daempf 0;
BA_ "GenSigAutoGenSnd" SG_ 1152 MO5_DZM_Daempf 1;
BA_ "GenSigAutoGenDsp" SG_ 1152 MO5_DZM_Daempf 1;
BA_ "GenSigSwitchedByIgnition" SG_ 1152 MO5_Interlock 0;
BA_ "GenSigSendType" SG_ 1152 MO5_Interlock 0;
BA_ "GenSigAutoGenSnd" SG_ 1152 MO5_Interlock 1;
BA_ "GenSigAutoGenDsp" SG_ 1152 MO5_Interlock 1;
BA_ "GenSigSwitchedByIgnition" SG_ 1152 MO5_Start 0;
BA_ "GenSigSendType" SG_ 1152 MO5_Start 0;
BA_ "GenSigAutoGenSnd" SG_ 1152 MO5_Start 1;
BA_ "GenSigAutoGenDsp" SG_ 1152 MO5_Start 1;
BA_ "GenSigSwitchedByIgnition" SG_ 1152 MO5_Anlasser 0;
BA_ "GenSigSendType" SG_ 1152 MO5_Anlasser 0;
BA_ "GenSigAutoGenSnd" SG_ 1152 MO5_Anlasser 1;
BA_ "GenSigAutoGenDsp" SG_ 1152 MO5_Anlasser 1;
BA_ "GenSigSwitchedByIgnition" SG_ 1152 MO5_GRA_Hauptsch 0;
BA_ "GenSigSendType" SG_ 1152 MO5_GRA_Hauptsch 0;
BA_ "GenSigAutoGenSnd" SG_ 1152 MO5_GRA_Hauptsch 1;
BA_ "GenSigAutoGenDsp" SG_ 1152 MO5_GRA_Hauptsch 1;
BA_ "GenSigSwitchedByIgnition" SG_ 1152 MO5_Momente 0;
BA_ "GenSigSendType" SG_ 1152 MO5_Momente 0;
BA_ "GenSigAutoGenSnd" SG_ 1152 MO5_Momente 1;
BA_ "GenSigAutoGenDsp" SG_ 1152 MO5_Momente 1;
BA_ "GenSigSwitchedByIgnition" SG_ 1152 MO5_Motortext1 0;
BA_ "GenSigSendType" SG_ 1152 MO5_Motortext1 0;
BA_ "GenSigAutoGenSnd" SG_ 1152 MO5_Motortext1 1;
BA_ "GenSigAutoGenDsp" SG_ 1152 MO5_Motortext1 1;
BA_ "GenSigSwitchedByIgnition" SG_ 1152 MO5_Motortext2 0;
BA_ "GenSigSendType" SG_ 1152 MO5_Motortext2 0;
BA_ "GenSigAutoGenSnd" SG_ 1152 MO5_Motortext2 1;
BA_ "GenSigAutoGenDsp" SG_ 1152 MO5_Motortext2 1;
BA_ "GenSigSwitchedByIgnition" SG_ 1152 MO5_Motortext3 0;
BA_ "GenSigSendType" SG_ 1152 MO5_Motortext3 0;
BA_ "GenSigAutoGenSnd" SG_ 1152 MO5_Motortext3 1;
BA_ "GenSigAutoGenDsp" SG_ 1152 MO5_Motortext3 1;
BA_ "GenSigSwitchedByIgnition" SG_ 1152 MO5_Motortext4 0;
BA_ "GenSigSendType" SG_ 1152 MO5_Motortext4 0;
BA_ "GenSigAutoGenSnd" SG_ 1152 MO5_Motortext4 1;
BA_ "GenSigAutoGenDsp" SG_ 1152 MO5_Motortext4 1;
BA_ "GenSigSwitchedByIgnition" SG_ 1152 MO5_Checksumme 0;
BA_ "GenSigFuncType" SG_ 1152 MO5_Checksumme 4;
BA_ "GenSigSendType" SG_ 1152 MO5_Checksumme 0;
BA_ "GenSigAutoGenSnd" SG_ 1152 MO5_Checksumme 1;
BA_ "GenSigAutoGenDsp" SG_ 1152 MO5_Checksumme 1;
BA_REL_ "GenSigTimeoutTime" BU_SG_REL_ Bremse_MK60EC SG_ 208 LH3_Checksumme 500;
BA_REL_ "GenSigTimeoutTime" BU_SG_REL_ Bremse_MK70MABS SG_ 208 LH3_Checksumme 500;
BA_REL_ "GenSigTimeoutTime" BU_SG_REL_ Bremse_TRW_EBC450M SG_ 208 LH3_Checksumme 500;
BA_REL_ "GenSigTimeoutTime" BU_SG_REL_ Bremse_TRW_ESP SG_ 208 LH3_Checksumme 500;
BA_REL_ "GenSigTimeoutTime" BU_SG_REL_ HCA SG_ 208 LH3_Checksumme 500;
BA_REL_ "GenSigTimeoutTime" BU_SG_REL_ PDC_PLA SG_ 208 LH3_Checksumme 500;
BA_REL_ "GenSigTimeoutTime" BU_SG_REL_ Bremse_MK60EC SG_ 208 LH3_Zaehler 500;
BA_REL_ "GenSigTimeoutTime" BU_SG_REL_ Bremse_MK70MABS SG_ 208 LH3_Zaehler 500;
BA_REL_ "GenSigTimeoutTime" BU_SG_REL_ Bremse_TRW_EBC450M SG_ 208 LH3_Zaehler 500;
BA_REL_ "GenSigTimeoutTime" BU_SG_REL_ Bremse_TRW_ESP SG_ 208 LH3_Zaehler 500;
BA_REL_ "GenSigTimeoutTime" BU_SG_REL_ HCA SG_ 208 LH3_Zaehler 500;
BA_REL_ "GenSigTimeoutTime" BU_SG_REL_ PDC_PLA SG_ 208 LH3_Zaehler 500;
BA_REL_ "GenSigTimeoutTime" BU_SG_REL_ Bremse_MK60EC SG_ 208 LH3_LM 500;
BA_REL_ "GenSigTimeoutTime" BU_SG_REL_ Bremse_MK70MABS SG_ 208 LH3_LM 500;
BA_REL_ "GenSigTimeoutTime" BU_SG_REL_ Bremse_TRW_EBC450M SG_ 208 LH3_LM 500;
BA_REL_ "GenSigTimeoutTime" BU_SG_REL_ Bremse_TRW_ESP SG_ 208 LH3_LM 500;
BA_REL_ "GenSigTimeoutTime" BU_SG_REL_ Gateway_PQ35 SG_ 208 LH3_LM 500;
BA_REL_ "GenSigTimeoutTime" BU_SG_REL_ HCA SG_ 208 LH3_LM 500;
BA_REL_ "GenSigTimeoutTime" BU_SG_REL_ Motor_Diesel SG_ 208 LH3_LM 500;
BA_REL_ "GenSigTimeoutTime" BU_SG_REL_ Motor_Otto SG_ 208 LH3_LM 500;
BA_REL_ "GenSigTimeoutTime" BU_SG_REL_ PDC_PLA SG_ 208 LH3_LM 500;
BA_REL_ "GenSigTimeoutTime" BU_SG_REL_ Bremse_MK60EC SG_ 208 LH3_LMSign 500;
BA_REL_ "GenSigTimeoutTime" BU_SG_REL_ Bremse_MK70MABS SG_ 208 LH3_LMSign 500;
BA_REL_ "GenSigTimeoutTime" BU_SG_REL_ Bremse_TRW_EBC450M SG_ 208 LH3_LMSign 500;
BA_REL_ "GenSigTimeoutTime" BU_SG_REL_ Bremse_TRW_ESP SG_ 208 LH3_LMSign 500;
BA_REL_ "GenSigTimeoutTime" BU_SG_REL_ Gateway_PQ35 SG_ 208 LH3_LMSign 500;
BA_REL_ "GenSigTimeoutTime" BU_SG_REL_ HCA SG_ 208 LH3_LMSign 500;
BA_REL_ "GenSigTimeoutTime" BU_SG_REL_ Motor_Diesel SG_ 208 LH3_LMSign 500;
BA_REL_ "GenSigTimeoutTime" BU_SG_REL_ Motor_Otto SG_ 208 LH3_LMSign 500;
BA_REL_ "GenSigTimeoutTime" BU_SG_REL_ PDC_PLA SG_ 208 LH3_LMSign 500;
BA_REL_ "GenSigTimeoutTime" BU_SG_REL_ Bremse_MK60EC SG_ 208 LH3_LMValid 500;
BA_REL_ "GenSigTimeoutTime" BU_SG_REL_ Bremse_MK70MABS SG_ 208 LH3_LMValid 500;
BA_REL_ "GenSigTimeoutTime" BU_SG_REL_ Bremse_TRW_EBC450M SG_ 208 LH3_LMValid 500;
BA_REL_ "GenSigTimeoutTime" BU_SG_REL_ Bremse_TRW_ESP SG_ 208 LH3_LMValid 500;
BA_REL_ "GenSigTimeoutTime" BU_SG_REL_ Gateway_PQ35 SG_ 208 LH3_LMValid 500;
BA_REL_ "GenSigTimeoutTime" BU_SG_REL_ HCA SG_ 208 LH3_LMValid 500;
BA_REL_ "GenSigTimeoutTime" BU_SG_REL_ Motor_Diesel SG_ 208 LH3_LMValid 500;
BA_REL_ "GenSigTimeoutTime" BU_SG_REL_ Motor_Otto SG_ 208 LH3_LMValid 500;
BA_REL_ "GenSigTimeoutTime" BU_SG_REL_ PDC_PLA SG_ 208 LH3_LMValid 500;
BA_REL_ "GenSigTimeoutTime" BU_SG_REL_ Bremse_MK60EC SG_ 208 LH3_Sta_DSR 500;
BA_REL_ "GenSigTimeoutTime" BU_SG_REL_ Bremse_MK70MABS SG_ 208 LH3_Sta_DSR 500;
BA_REL_ "GenSigTimeoutTime" BU_SG_REL_ Bremse_TRW_EBC450M SG_ 208 LH3_Sta_DSR 500;
BA_REL_ "GenSigTimeoutTime" BU_SG_REL_ Bremse_TRW_ESP SG_ 208 LH3_Sta_DSR 500;
BA_REL_ "GenSigTimeoutTime" BU_SG_REL_ Bremse_MK60EC SG_ 208 LH3_BLW 500;
BA_REL_ "GenSigTimeoutTime" BU_SG_REL_ Bremse_MK70MABS SG_ 208 LH3_BLW 500;
BA_REL_ "GenSigTimeoutTime" BU_SG_REL_ Bremse_TRW_EBC450M SG_ 208 LH3_BLW 500;
BA_REL_ "GenSigTimeoutTime" BU_SG_REL_ Bremse_TRW_ESP SG_ 208 LH3_BLW 500;
BA_REL_ "GenSigTimeoutTime" BU_SG_REL_ Gateway_PQ35 SG_ 208 LH3_BLW 500;
BA_REL_ "GenSigTimeoutTime" BU_SG_REL_ HCA SG_ 208 LH3_BLW 500;
BA_REL_ "GenSigTimeoutTime" BU_SG_REL_ PDC_PLA SG_ 208 LH3_BLW 500;
BA_REL_ "GenSigTimeoutTime" BU_SG_REL_ Bremse_MK60EC SG_ 208 LH3_BLWSign 500;
BA_REL_ "GenSigTimeoutTime" BU_SG_REL_ Bremse_MK70MABS SG_ 208 LH3_BLWSign 500;
BA_REL_ "GenSigTimeoutTime" BU_SG_REL_ Bremse_TRW_EBC450M SG_ 208 LH3_BLWSign 500;
BA_REL_ "GenSigTimeoutTime" BU_SG_REL_ Bremse_TRW_ESP SG_ 208 LH3_BLWSign 500;
BA_REL_ "GenSigTimeoutTime" BU_SG_REL_ Gateway_PQ35 SG_ 208 LH3_BLWSign 500;
BA_REL_ "GenSigTimeoutTime" BU_SG_REL_ HCA SG_ 208 LH3_BLWSign 500;
BA_REL_ "GenSigTimeoutTime" BU_SG_REL_ PDC_PLA SG_ 208 LH3_BLWSign 500;
BA_REL_ "GenSigTimeoutTime" BU_SG_REL_ Bremse_MK60EC SG_ 208 LH3_BLWValid 500;
BA_REL_ "GenSigTimeoutTime" BU_SG_REL_ Bremse_MK70MABS SG_ 208 LH3_BLWValid 500;
BA_REL_ "GenSigTimeoutTime" BU_SG_REL_ Bremse_TRW_EBC450M SG_ 208 LH3_BLWValid 500;
BA_REL_ "GenSigTimeoutTime" BU_SG_REL_ Bremse_TRW_ESP SG_ 208 LH3_BLWValid 500;
BA_REL_ "GenSigTimeoutTime" BU_SG_REL_ Gateway_PQ35 SG_ 208 LH3_BLWValid 500;
BA_REL_ "GenSigTimeoutTime" BU_SG_REL_ HCA SG_ 208 LH3_BLWValid 500;
BA_REL_ "GenSigTimeoutTime" BU_SG_REL_ PDC_PLA SG_ 208 LH3_BLWValid 500;
BA_REL_ "GenSigTimeoutTime" BU_SG_REL_ Bremse_MK60EC SG_ 208 LH3_Lenkungstyp 500;
BA_REL_ "GenSigTimeoutTime" BU_SG_REL_ Bremse_MK70MABS SG_ 208 LH3_Lenkungstyp 500;
BA_REL_ "GenSigTimeoutTime" BU_SG_REL_ Bremse_TRW_EBC450M SG_ 208 LH3_Lenkungstyp 500;
BA_REL_ "GenSigTimeoutTime" BU_SG_REL_ Bremse_TRW_ESP SG_ 208 LH3_Lenkungstyp 500;
BA_REL_ "GenSigTimeoutTime" BU_SG_REL_ HCA SG_ 208 LH3_Lenkungstyp 500;
BA_REL_ "GenSigTimeoutTime" BU_SG_REL_ PDC_PLA SG_ 208 LH3_Lenkungstyp 500;
BA_REL_ "GenSigTimeoutTime" BU_SG_REL_ Motor_Otto SG_ 398 LPG_01_Reserve 500;
BA_REL_ "GenSigTimeoutTime" BU_SG_REL_ Motor_Otto SG_ 654 LPG_02_Reserve 500;
BA_REL_ "GenSigTimeoutTime" BU_SG_REL_ Motor_Otto SG_ 655 LPG_03_Reserve 500;
BA_REL_ "GenSigTimeoutTime" BU_SG_REL_ AFS SG_ 194 LW1_LRW 500;
BA_REL_ "GenSigTimeoutTime" BU_SG_REL_ Allrad SG_ 194 LW1_LRW 500;
BA_REL_ "GenSigTimeoutTime" BU_SG_REL_ Bremse_MK60EC SG_ 194 LW1_LRW 500;
BA_REL_ "GenSigTimeoutTime" BU_SG_REL_ Bremse_MK60EC SG_ 194 LW1_LRW 500;
BA_REL_ "GenSigTimeoutTime" BU_SG_REL_ Bremse_TRW_EBC450M SG_ 194 LW1_LRW 500;
BA_REL_ "GenSigTimeoutTime" BU_SG_REL_ Bremse_TRW_EBC450M SG_ 194 LW1_LRW 500;
BA_REL_ "GenSigTimeoutTime" BU_SG_REL_ Bremse_TRW_ESP SG_ 194 LW1_LRW 500;
BA_REL_ "GenSigTimeoutTime" BU_SG_REL_ Bremse_TRW_ESP SG_ 194 LW1_LRW 500;
BA_REL_ "GenSigTimeoutTime" BU_SG_REL_ Daempfer SG_ 194 LW1_LRW 500;
BA_REL_ "GenSigTimeoutTime" BU_SG_REL_ Getriebe_DQ SG_ 194 LW1_LRW 500;
BA_REL_ "GenSigTimeoutTime" BU_SG_REL_ Getriebe_DQ_Hyb SG_ 194 LW1_LRW 500;
BA_REL_ "GenSigTimeoutTime" BU_SG_REL_ Getriebe_Sele SG_ 194 LW1_LRW 500;
BA_REL_ "GenSigTimeoutTime" BU_SG_REL_ LH_EPS_APA SG_ 194 LW1_LRW 500;
BA_REL_ "GenSigTimeoutTime" BU_SG_REL_ LH_EPS_ZF_2G SG_ 194 LW1_LRW 500;
BA_REL_ "GenSigTimeoutTime" BU_SG_REL_ LWR SG_ 194 LW1_LRW 500;
BA_REL_ "GenSigTimeoutTime" BU_SG_REL_ Magne_Ride SG_ 194 LW1_LRW 500;
BA_REL_ "GenSigTimeoutTime" BU_SG_REL_ Motor_Diesel SG_ 194 LW1_LRW 500;
BA_REL_ "GenSigTimeoutTime" BU_SG_REL_ Motor_Hybrid SG_ 194 LW1_LRW 500;
BA_REL_ "GenSigTimeoutTime" BU_SG_REL_ Motor_Otto SG_ 194 LW1_LRW 500;
BA_REL_ "GenSigTimeoutTime" BU_SG_REL_ RKA_Plus SG_ 194 LW1_LRW 500;
BA_REL_ "GenSigTimeoutTime" BU_SG_REL_ AFS SG_ 194 LW1_LRW_Sign 500;
BA_REL_ "GenSigTimeoutTime" BU_SG_REL_ Allrad SG_ 194 LW1_LRW_Sign 500;
BA_REL_ "GenSigTimeoutTime" BU_SG_REL_ Bremse_MK60EC SG_ 194 LW1_LRW_Sign 500;
BA_REL_ "GenSigTimeoutTime" BU_SG_REL_ Bremse_MK60EC SG_ 194 LW1_LRW_Sign 500;
BA_REL_ "GenSigTimeoutTime" BU_SG_REL_ Bremse_TRW_EBC450M SG_ 194 LW1_LRW_Sign 500;
BA_REL_ "GenSigTimeoutTime" BU_SG_REL_ Bremse_TRW_EBC450M SG_ 194 LW1_LRW_Sign 500;
BA_REL_ "GenSigTimeoutTime" BU_SG_REL_ Bremse_TRW_ESP SG_ 194 LW1_LRW_Sign 500;
BA_REL_ "GenSigTimeoutTime" BU_SG_REL_ Bremse_TRW_ESP SG_ 194 LW1_LRW_Sign 500;
BA_REL_ "GenSigTimeoutTime" BU_SG_REL_ Daempfer SG_ 194 LW1_LRW_Sign 500;
BA_REL_ "GenSigTimeoutTime" BU_SG_REL_ Getriebe_DQ SG_ 194 LW1_LRW_Sign 500;
BA_REL_ "GenSigTimeoutTime" BU_SG_REL_ Getriebe_DQ_Hyb SG_ 194 LW1_LRW_Sign 500;
BA_REL_ "GenSigTimeoutTime" BU_SG_REL_ LH_EPS_APA SG_ 194 LW1_LRW_Sign 500;
BA_REL_ "GenSigTimeoutTime" BU_SG_REL_ LH_EPS_ZF_2G SG_ 194 LW1_LRW_Sign 500;
BA_REL_ "GenSigTimeoutTime" BU_SG_REL_ LWR SG_ 194 LW1_LRW_Sign 500;
BA_REL_ "GenSigTimeoutTime" BU_SG_REL_ Magne_Ride SG_ 194 LW1_LRW_Sign 500;
BA_REL_ "GenSigTimeoutTime" BU_SG_REL_ Motor_Diesel SG_ 194 LW1_LRW_Sign 500;
BA_REL_ "GenSigTimeoutTime" BU_SG_REL_ Motor_Hybrid SG_ 194 LW1_LRW_Sign 500;
BA_REL_ "GenSigTimeoutTime" BU_SG_REL_ Motor_Otto SG_ 194 LW1_LRW_Sign 500;
BA_REL_ "GenSigTimeoutTime" BU_SG_REL_ RKA_Plus SG_ 194 LW1_LRW_Sign 500;
BA_REL_ "GenSigTimeoutTime" BU_SG_REL_ Bremse_MK60EC SG_ 194 LW1_Lenk_Gesch 500;
BA_REL_ "GenSigTimeoutTime" BU_SG_REL_ HCA SG_ 194 LW1_Lenk_Gesch 500;
BA_REL_ "GenSigTimeoutTime" BU_SG_REL_ LH_EPS_APA SG_ 194 LW1_Lenk_Gesch 500;
BA_REL_ "GenSigTimeoutTime" BU_SG_REL_ LH_EPS_ZF_2G SG_ 194 LW1_Lenk_Gesch 500;
BA_REL_ "GenSigTimeoutTime" BU_SG_REL_ Magne_Ride SG_ 194 LW1_Lenk_Gesch 500;
BA_REL_ "GenSigTimeoutTime" BU_SG_REL_ Bremse_MK60EC SG_ 194 LW1_Gesch_Sign 500;
BA_REL_ "GenSigTimeoutTime" BU_SG_REL_ HCA SG_ 194 LW1_Gesch_Sign 500;
BA_REL_ "GenSigTimeoutTime" BU_SG_REL_ LH_EPS_APA SG_ 194 LW1_Gesch_Sign 500;
BA_REL_ "GenSigTimeoutTime" BU_SG_REL_ LH_EPS_ZF_2G SG_ 194 LW1_Gesch_Sign 500;
BA_REL_ "GenSigTimeoutTime" BU_SG_REL_ Magne_Ride SG_ 194 LW1_Gesch_Sign 500;
BA_REL_ "GenSigTimeoutTime" BU_SG_REL_ Bremse_MK60EC SG_ 194 LW1_ID 500;
BA_REL_ "GenSigTimeoutTime" BU_SG_REL_ Bremse_TRW_EBC450M SG_ 194 LW1_ID 500;
BA_REL_ "GenSigTimeoutTime" BU_SG_REL_ Bremse_TRW_ESP SG_ 194 LW1_ID 500;
BA_REL_ "GenSigTimeoutTime" BU_SG_REL_ LH_EPS_APA SG_ 194 LW1_ID 500;
BA_REL_ "GenSigTimeoutTime" BU_SG_REL_ LH_EPS_ZF_2G SG_ 194 LW1_ID 500;
BA_REL_ "GenSigTimeoutTime" BU_SG_REL_ LWR SG_ 194 LW1_ID 500;
BA_REL_ "GenSigTimeoutTime" BU_SG_REL_ Magne_Ride SG_ 194 LW1_ID 500;
BA_REL_ "GenSigTimeoutTime" BU_SG_REL_ Bremse_MK60EC SG_ 194 LW1_Initquelle 500;
BA_REL_ "GenSigTimeoutTime" BU_SG_REL_ Bremse_TRW_EBC450M SG_ 194 LW1_Initquelle 500;
BA_REL_ "GenSigTimeoutTime" BU_SG_REL_ Bremse_TRW_ESP SG_ 194 LW1_Initquelle 500;
BA_REL_ "GenSigTimeoutTime" BU_SG_REL_ Gateway_PQ35 SG_ 194 LW1_Initquelle 500;
BA_REL_ "GenSigTimeoutTime" BU_SG_REL_ LH_EPS_APA SG_ 194 LW1_Initquelle 500;
BA_REL_ "GenSigTimeoutTime" BU_SG_REL_ LH_EPS_ZF_2G SG_ 194 LW1_Initquelle 500;
BA_REL_ "GenSigTimeoutTime" BU_SG_REL_ AFS SG_ 194 LW1_Status 500;
BA_REL_ "GenSigTimeoutTime" BU_SG_REL_ Allrad SG_ 194 LW1_Status 500;
BA_REL_ "GenSigTimeoutTime" BU_SG_REL_ Bremse_MK60EC SG_ 194 LW1_Status 500;
BA_REL_ "GenSigTimeoutTime" BU_SG_REL_ Bremse_TRW_EBC450M SG_ 194 LW1_Status 500;
BA_REL_ "GenSigTimeoutTime" BU_SG_REL_ Bremse_TRW_ESP SG_ 194 LW1_Status 500;
BA_REL_ "GenSigTimeoutTime" BU_SG_REL_ Daempfer SG_ 194 LW1_Status 500;
BA_REL_ "GenSigTimeoutTime" BU_SG_REL_ Getriebe_DQ SG_ 194 LW1_Status 500;
BA_REL_ "GenSigTimeoutTime" BU_SG_REL_ Getriebe_DQ_Hyb SG_ 194 LW1_Status 500;
BA_REL_ "GenSigTimeoutTime" BU_SG_REL_ HCA SG_ 194 LW1_Status 500;
BA_REL_ "GenSigTimeoutTime" BU_SG_REL_ LH_EPS_APA SG_ 194 LW1_Status 500;
BA_REL_ "GenSigTimeoutTime" BU_SG_REL_ LH_EPS_ZF_2G SG_ 194 LW1_Status 500;
BA_REL_ "GenSigTimeoutTime" BU_SG_REL_ LWR SG_ 194 LW1_Status 500;
BA_REL_ "GenSigTimeoutTime" BU_SG_REL_ Magne_Ride SG_ 194 LW1_Status 500;
BA_REL_ "GenSigTimeoutTime" BU_SG_REL_ Motor_Diesel SG_ 194 LW1_Status 500;
BA_REL_ "GenSigTimeoutTime" BU_SG_REL_ Motor_Hybrid SG_ 194 LW1_Status 500;
BA_REL_ "GenSigTimeoutTime" BU_SG_REL_ Motor_Otto SG_ 194 LW1_Status 500;
BA_REL_ "GenSigTimeoutTime" BU_SG_REL_ RKA_Plus SG_ 194 LW1_Status 500;
BA_REL_ "GenSigTimeoutTime" BU_SG_REL_ Bremse_MK60EC SG_ 194 LW1_Sta_KL30 500;
BA_REL_ "GenSigTimeoutTime" BU_SG_REL_ Bremse_TRW_EBC450M SG_ 194 LW1_Sta_KL30 500;
BA_REL_ "GenSigTimeoutTime" BU_SG_REL_ Bremse_TRW_ESP SG_ 194 LW1_Sta_KL30 500;
BA_REL_ "GenSigTimeoutTime" BU_SG_REL_ LH_EPS_APA SG_ 194 LW1_Sta_KL30 500;
BA_REL_ "GenSigTimeoutTime" BU_SG_REL_ LWR SG_ 194 LW1_Sta_KL30 500;
BA_REL_ "GenSigTimeoutTime" BU_SG_REL_ Magne_Ride SG_ 194 LW1_Sta_KL30 500;
BA_REL_ "GenSigTimeoutTime" BU_SG_REL_ AFS SG_ 194 LW1_Zaehler 500;
BA_REL_ "GenSigTimeoutTime" BU_SG_REL_ Bremse_MK60EC SG_ 194 LW1_Zaehler 500;
BA_REL_ "GenSigTimeoutTime" BU_SG_REL_ Bremse_TRW_EBC450M SG_ 194 LW1_Zaehler 500;
BA_REL_ "GenSigTimeoutTime" BU_SG_REL_ Bremse_TRW_ESP SG_ 194 LW1_Zaehler 500;
BA_REL_ "GenSigTimeoutTime" BU_SG_REL_ Daempfer SG_ 194 LW1_Zaehler 500;
BA_REL_ "GenSigTimeoutTime" BU_SG_REL_ HCA SG_ 194 LW1_Zaehler 500;
BA_REL_ "GenSigTimeoutTime" BU_SG_REL_ LH_EPS_APA SG_ 194 LW1_Zaehler 500;
BA_REL_ "GenSigTimeoutTime" BU_SG_REL_ LWR SG_ 194 LW1_Zaehler 500;
BA_REL_ "GenSigTimeoutTime" BU_SG_REL_ Magne_Ride SG_ 194 LW1_Zaehler 500;
BA_REL_ "GenSigTimeoutTime" BU_SG_REL_ LH_EPS_APA SG_ 194 LW1_Kodier 500;
BA_REL_ "GenSigTimeoutTime" BU_SG_REL_ AFS SG_ 194 LW1_CRC 500;
BA_REL_ "GenSigTimeoutTime" BU_SG_REL_ Bremse_MK60EC SG_ 194 LW1_CRC 500;
BA_REL_ "GenSigTimeoutTime" BU_SG_REL_ Bremse_TRW_EBC450M SG_ 194 LW1_CRC 500;
BA_REL_ "GenSigTimeoutTime" BU_SG_REL_ Bremse_TRW_ESP SG_ 194 LW1_CRC 500;
BA_REL_ "GenSigTimeoutTime" BU_SG_REL_ Daempfer SG_ 194 LW1_CRC 500;
BA_REL_ "GenSigTimeoutTime" BU_SG_REL_ HCA SG_ 194 LW1_CRC 500;
BA_REL_ "GenSigTimeoutTime" BU_SG_REL_ LH_EPS_APA SG_ 194 LW1_CRC 500;
BA_REL_ "GenSigTimeoutTime" BU_SG_REL_ LWR SG_ 194 LW1_CRC 500;
BA_REL_ "GenSigTimeoutTime" BU_SG_REL_ Magne_Ride SG_ 194 LW1_CRC 500;
BA_REL_ "GenSigTimeoutTime" BU_SG_REL_ Gateway_PQ35 SG_ 916 LRZ_Fehler 1000;
BA_REL_ "GenSigTimeoutTime" BU_SG_REL_ Bremse_MK60EC SG_ 916 LRZ_Einfedg_vo 1000;
BA_REL_ "GenSigTimeoutTime" BU_SG_REL_ RKA_Plus SG_ 916 LRZ_Einfedg_vo 1000;
BA_REL_ "GenSigTimeoutTime" BU_SG_REL_ Bremse_MK60EC SG_ 916 LRZ_Einfedg_hi 1000;
BA_REL_ "GenSigTimeoutTime" BU_SG_REL_ RKA_Plus SG_ 916 LRZ_Einfedg_hi 1000;
BA_REL_ "GenSigTimeoutTime" BU_SG_REL_ Bremse_MK60EC SG_ 640 MO1_Leergas 500;
BA_REL_ "GenSigTimeoutTime" BU_SG_REL_ Bremse_MK70MABS SG_ 640 MO1_Leergas 500;
BA_REL_ "GenSigTimeoutTime" BU_SG_REL_ Getriebe_AG6 SG_ 640 MO1_Leergas 500;
BA_REL_ "GenSigTimeoutTime" BU_SG_REL_ Getriebe_DQ SG_ 640 MO1_Leergas 500;
BA_REL_ "GenSigTimeoutTime" BU_SG_REL_ Getriebe_DQ_Hyb SG_ 640 MO1_Leergas 500;
BA_REL_ "GenSigTimeoutTime" BU_SG_REL_ Bremse_MK60EC SG_ 640 MO1_Sta_Pedal 500;
BA_REL_ "GenSigTimeoutTime" BU_SG_REL_ Bremse_MK70MABS SG_ 640 MO1_Sta_Pedal 500;
BA_REL_ "GenSigTimeoutTime" BU_SG_REL_ Gateway_PQ35 SG_ 640 MO1_Sta_Pedal 500;
BA_REL_ "GenSigTimeoutTime" BU_SG_REL_ Getriebe_AG6 SG_ 640 MO1_Sta_Pedal 500;
BA_REL_ "GenSigTimeoutTime" BU_SG_REL_ LH_EPS_APA SG_ 640 MO1_Sta_Pedal 500;
BA_REL_ "GenSigTimeoutTime" BU_SG_REL_ Getriebe_AG6 SG_ 640 MO1_Kickdown 500;
BA_REL_ "GenSigTimeoutTime" BU_SG_REL_ Getriebe_DQ SG_ 640 MO1_Kickdown 500;
BA_REL_ "GenSigTimeoutTime" BU_SG_REL_ Getriebe_DQ_Hyb SG_ 640 MO1_Kickdown 500;
BA_REL_ "GenSigTimeoutTime" BU_SG_REL_ Getriebe_Sele SG_ 640 MO1_Kickdown 500;
BA_REL_ "GenSigTimeoutTime" BU_SG_REL_ Allrad SG_ 640 MO1_Kup_schalt 500;
BA_REL_ "GenSigTimeoutTime" BU_SG_REL_ Bremse_MK60EC SG_ 640 MO1_Kup_schalt 500;
BA_REL_ "GenSigTimeoutTime" BU_SG_REL_ Bremse_MK60EC SG_ 640 MO1_Kup_schalt 500;
BA_REL_ "GenSigTimeoutTime" BU_SG_REL_ Bremse_MK70MABS SG_ 640 MO1_Kup_schalt 500;
BA_REL_ "GenSigTimeoutTime" BU_SG_REL_ Bremse_TRW_EBC450M SG_ 640 MO1_Kup_schalt 500;
BA_REL_ "GenSigTimeoutTime" BU_SG_REL_ Bremse_TRW_EBC450M SG_ 640 MO1_Kup_schalt 500;
BA_REL_ "GenSigTimeoutTime" BU_SG_REL_ Bremse_TRW_ESP SG_ 640 MO1_Kup_schalt 500;
BA_REL_ "GenSigTimeoutTime" BU_SG_REL_ Bremse_TRW_ESP SG_ 640 MO1_Kup_schalt 500;
BA_REL_ "GenSigTimeoutTime" BU_SG_REL_ Gateway_PQ35 SG_ 640 MO1_Kup_schalt 500;
BA_REL_ "GenSigTimeoutTime" BU_SG_REL_ Gateway_PQ35 SG_ 640 MO1_Kup_schalt 500;
BA_REL_ "GenSigTimeoutTime" BU_SG_REL_ Gateway_PQ35 SG_ 640 MO1_Kup_schalt 500;
BA_REL_ "GenSigTimeoutTime" BU_SG_REL_ PDC_PLA SG_ 640 MO1_Kup_schalt 500;
BA_REL_ "GenSigTimeoutTime" BU_SG_REL_ RKA_Plus SG_ 640 MO1_Kup_schalt 500;
BA_REL_ "GenSigTimeoutTime" BU_SG_REL_ Bremse_TRW_EBC450M SG_ 640 MO1_TiOut_Br 500;
BA_REL_ "GenSigTimeoutTime" BU_SG_REL_ Bremse_TRW_ESP SG_ 640 MO1_TiOut_Br 500;
BA_REL_ "GenSigTimeoutTime" BU_SG_REL_ Bremse_MK60EC SG_ 640 MO1_Sta_Bremse 500;
BA_REL_ "GenSigTimeoutTime" BU_SG_REL_ Bremse_MK70MABS SG_ 640 MO1_Sta_Bremse 500;
BA_REL_ "GenSigTimeoutTime" BU_SG_REL_ Bremse_TRW_EBC450M SG_ 640 MO1_Sta_Bremse 500;
BA_REL_ "GenSigTimeoutTime" BU_SG_REL_ Bremse_TRW_ESP SG_ 640 MO1_Sta_Bremse 500;
BA_REL_ "GenSigTimeoutTime" BU_SG_REL_ EPB_TRW SG_ 640 MO1_Sta_Bremse 500;
BA_REL_ "GenSigTimeoutTime" BU_SG_REL_ Getriebe_AG6 SG_ 640 MO1_Sta_Getr 500;
BA_REL_ "GenSigTimeoutTime" BU_SG_REL_ Getriebe_DQ SG_ 640 MO1_Sta_Getr 500;
BA_REL_ "GenSigTimeoutTime" BU_SG_REL_ Getriebe_DQ_Hyb SG_ 640 MO1_Sta_Getr 500;
BA_REL_ "GenSigTimeoutTime" BU_SG_REL_ Bremse_MK60EC SG_ 640 MO1_Sta_MotMo 500;
BA_REL_ "GenSigTimeoutTime" BU_SG_REL_ Bremse_MK70MABS SG_ 640 MO1_Sta_MotMo 500;
BA_REL_ "GenSigTimeoutTime" BU_SG_REL_ Bremse_TRW_EBC450M SG_ 640 MO1_Sta_MotMo 500;
BA_REL_ "GenSigTimeoutTime" BU_SG_REL_ Bremse_TRW_ESP SG_ 640 MO1_Sta_MotMo 500;
BA_REL_ "GenSigTimeoutTime" BU_SG_REL_ Getriebe_AG6 SG_ 640 MO1_Sta_MotMo 500;
BA_REL_ "GenSigTimeoutTime" BU_SG_REL_ Getriebe_DQ SG_ 640 MO1_Sta_MotMo 500;
BA_REL_ "GenSigTimeoutTime" BU_SG_REL_ Getriebe_DQ_Hyb SG_ 640 MO1_Sta_MotMo 500;
BA_REL_ "GenSigTimeoutTime" BU_SG_REL_ Getriebe_Sele SG_ 640 MO1_Sta_MotMo 500;
BA_REL_ "GenSigTimeoutTime" BU_SG_REL_ RKA_Plus SG_ 640 MO1_Sta_MotMo 500;
BA_REL_ "GenSigTimeoutTime" BU_SG_REL_ Allrad SG_ 640 MO1_Mo_m_ex 500;
BA_REL_ "GenSigTimeoutTime" BU_SG_REL_ Bremse_MK60EC SG_ 640 MO1_Mo_m_ex 500;
BA_REL_ "GenSigTimeoutTime" BU_SG_REL_ Bremse_MK60EC SG_ 640 MO1_Mo_m_ex 500;
BA_REL_ "GenSigTimeoutTime" BU_SG_REL_ Bremse_MK70MABS SG_ 640 MO1_Mo_m_ex 500;
BA_REL_ "GenSigTimeoutTime" BU_SG_REL_ Bremse_TRW_EBC450M SG_ 640 MO1_Mo_m_ex 500;
BA_REL_ "GenSigTimeoutTime" BU_SG_REL_ Bremse_TRW_EBC450M SG_ 640 MO1_Mo_m_ex 500;
BA_REL_ "GenSigTimeoutTime" BU_SG_REL_ Bremse_TRW_ESP SG_ 640 MO1_Mo_m_ex 500;
BA_REL_ "GenSigTimeoutTime" BU_SG_REL_ Bremse_TRW_ESP SG_ 640 MO1_Mo_m_ex 500;
BA_REL_ "GenSigTimeoutTime" BU_SG_REL_ EPB_TRW_VW411CS SG_ 640 MO1_Mo_m_ex 500;
BA_REL_ "GenSigTimeoutTime" BU_SG_REL_ Getriebe_AG6 SG_ 640 MO1_Mo_m_ex 500;
BA_REL_ "GenSigTimeoutTime" BU_SG_REL_ Getriebe_DQ SG_ 640 MO1_Mo_m_ex 500;
BA_REL_ "GenSigTimeoutTime" BU_SG_REL_ Getriebe_DQ_Hyb SG_ 640 MO1_Mo_m_ex 500;
BA_REL_ "GenSigTimeoutTime" BU_SG_REL_ Getriebe_Sele SG_ 640 MO1_Mo_m_ex 500;
BA_REL_ "GenSigTimeoutTime" BU_SG_REL_ Magne_Ride SG_ 640 MO1_Mo_m_ex 500;
BA_REL_ "GenSigTimeoutTime" BU_SG_REL_ RKA_Plus SG_ 640 MO1_Mo_m_ex 500;
BA_REL_ "GenSigTimeoutTime" BU_SG_REL_ AFS SG_ 640 MO1_Drehzahl 500;
BA_REL_ "GenSigTimeoutTime" BU_SG_REL_ Allrad SG_ 640 MO1_Drehzahl 500;
BA_REL_ "GenSigTimeoutTime" BU_SG_REL_ BMS_Hybrid SG_ 640 MO1_Drehzahl 500;
BA_REL_ "GenSigTimeoutTime" BU_SG_REL_ Bremse_MK60EC SG_ 640 MO1_Drehzahl 500;
BA_REL_ "GenSigTimeoutTime" BU_SG_REL_ Bremse_MK60EC SG_ 640 MO1_Drehzahl 500;
BA_REL_ "GenSigTimeoutTime" BU_SG_REL_ Bremse_MK70MABS SG_ 640 MO1_Drehzahl 500;
BA_REL_ "GenSigTimeoutTime" BU_SG_REL_ Bremse_TRW_EBC450M SG_ 640 MO1_Drehzahl 500;
BA_REL_ "GenSigTimeoutTime" BU_SG_REL_ Bremse_TRW_EBC450M SG_ 640 MO1_Drehzahl 500;
BA_REL_ "GenSigTimeoutTime" BU_SG_REL_ Bremse_TRW_ESP SG_ 640 MO1_Drehzahl 500;
BA_REL_ "GenSigTimeoutTime" BU_SG_REL_ Bremse_TRW_ESP SG_ 640 MO1_Drehzahl 500;
BA_REL_ "GenSigTimeoutTime" BU_SG_REL_ EPB_TRW SG_ 640 MO1_Drehzahl 500;
BA_REL_ "GenSigTimeoutTime" BU_SG_REL_ EPB_TRW_VW411CS SG_ 640 MO1_Drehzahl 500;
BA_REL_ "GenSigTimeoutTime" BU_SG_REL_ Gateway_PQ35 SG_ 640 MO1_Drehzahl 500;
BA_REL_ "GenSigTimeoutTime" BU_SG_REL_ Gateway_PQ35 SG_ 640 MO1_Drehzahl 500;
BA_REL_ "GenSigTimeoutTime" BU_SG_REL_ Gateway_PQ35 SG_ 640 MO1_Drehzahl 500;
BA_REL_ "GenSigTimeoutTime" BU_SG_REL_ Gateway_PQ35 SG_ 640 MO1_Drehzahl 500;
BA_REL_ "GenSigTimeoutTime" BU_SG_REL_ Getriebe_AG6 SG_ 640 MO1_Drehzahl 500;
BA_REL_ "GenSigTimeoutTime" BU_SG_REL_ Getriebe_DQ SG_ 640 MO1_Drehzahl 500;
BA_REL_ "GenSigTimeoutTime" BU_SG_REL_ Getriebe_DQ_Hyb SG_ 640 MO1_Drehzahl 500;
BA_REL_ "GenSigTimeoutTime" BU_SG_REL_ Getriebe_Sele SG_ 640 MO1_Drehzahl 500;
BA_REL_ "GenSigTimeoutTime" BU_SG_REL_ HCA SG_ 640 MO1_Drehzahl 500;
BA_REL_ "GenSigTimeoutTime" BU_SG_REL_ LEH_Hybrid SG_ 640 MO1_Drehzahl 500;
BA_REL_ "GenSigTimeoutTime" BU_SG_REL_ LH_EPS_APA SG_ 640 MO1_Drehzahl 500;
BA_REL_ "GenSigTimeoutTime" BU_SG_REL_ LH_EPS_ZF_2G SG_ 640 MO1_Drehzahl 500;
BA_REL_ "GenSigTimeoutTime" BU_SG_REL_ LH_EPS_ZF_3G SG_ 640 MO1_Drehzahl 500;
BA_REL_ "GenSigTimeoutTime" BU_SG_REL_ LWR SG_ 640 MO1_Drehzahl 500;
BA_REL_ "GenSigTimeoutTime" BU_SG_REL_ Magne_Ride SG_ 640 MO1_Drehzahl 500;
BA_REL_ "GenSigTimeoutTime" BU_SG_REL_ PDC_PLA SG_ 640 MO1_Drehzahl 500;
BA_REL_ "GenSigTimeoutTime" BU_SG_REL_ RKA_Plus SG_ 640 MO1_Drehzahl 500;
BA_REL_ "GenSigTimeoutTime" BU_SG_REL_ Bremse_MK60EC SG_ 640 MO1_Mo_o_ex 500;
BA_REL_ "GenSigTimeoutTime" BU_SG_REL_ Bremse_MK70MABS SG_ 640 MO1_Mo_o_ex 500;
BA_REL_ "GenSigTimeoutTime" BU_SG_REL_ Bremse_TRW_EBC450M SG_ 640 MO1_Mo_o_ex 500;
BA_REL_ "GenSigTimeoutTime" BU_SG_REL_ Bremse_TRW_ESP SG_ 640 MO1_Mo_o_ex 500;
BA_REL_ "GenSigTimeoutTime" BU_SG_REL_ Getriebe_AG6 SG_ 640 MO1_Mo_o_ex 500;
BA_REL_ "GenSigTimeoutTime" BU_SG_REL_ Getriebe_DQ SG_ 640 MO1_Mo_o_ex 500;
BA_REL_ "GenSigTimeoutTime" BU_SG_REL_ Getriebe_DQ_Hyb SG_ 640 MO1_Mo_o_ex 500;
BA_REL_ "GenSigTimeoutTime" BU_SG_REL_ AFS SG_ 640 MO1_Pedalwert 500;
BA_REL_ "GenSigTimeoutTime" BU_SG_REL_ Allrad SG_ 640 MO1_Pedalwert 500;
BA_REL_ "GenSigTimeoutTime" BU_SG_REL_ Bremse_MK60EC SG_ 640 MO1_Pedalwert 500;
BA_REL_ "GenSigTimeoutTime" BU_SG_REL_ Bremse_MK70MABS SG_ 640 MO1_Pedalwert 500;
BA_REL_ "GenSigTimeoutTime" BU_SG_REL_ Bremse_TRW_EBC450M SG_ 640 MO1_Pedalwert 500;
BA_REL_ "GenSigTimeoutTime" BU_SG_REL_ Bremse_TRW_ESP SG_ 640 MO1_Pedalwert 500;
BA_REL_ "GenSigTimeoutTime" BU_SG_REL_ Gateway_PQ35 SG_ 640 MO1_Pedalwert 500;
BA_REL_ "GenSigTimeoutTime" BU_SG_REL_ Getriebe_AG6 SG_ 640 MO1_Pedalwert 500;
BA_REL_ "GenSigTimeoutTime" BU_SG_REL_ Getriebe_DQ SG_ 640 MO1_Pedalwert 500;
BA_REL_ "GenSigTimeoutTime" BU_SG_REL_ Getriebe_DQ_Hyb SG_ 640 MO1_Pedalwert 500;
BA_REL_ "GenSigTimeoutTime" BU_SG_REL_ Getriebe_Sele SG_ 640 MO1_Pedalwert 500;
BA_REL_ "GenSigTimeoutTime" BU_SG_REL_ LH_EPS_APA SG_ 640 MO1_Pedalwert 500;
BA_REL_ "GenSigTimeoutTime" BU_SG_REL_ LH_EPS_ZF_2G SG_ 640 MO1_Pedalwert 500;
BA_REL_ "GenSigTimeoutTime" BU_SG_REL_ LH_EPS_ZF_3G SG_ 640 MO1_Pedalwert 500;
BA_REL_ "GenSigTimeoutTime" BU_SG_REL_ LWR SG_ 640 MO1_Pedalwert 500;
BA_REL_ "GenSigTimeoutTime" BU_SG_REL_ Allrad SG_ 640 MO1_Verlustmo 500;
BA_REL_ "GenSigTimeoutTime" BU_SG_REL_ Bremse_MK60EC SG_ 640 MO1_Verlustmo 500;
BA_REL_ "GenSigTimeoutTime" BU_SG_REL_ Bremse_MK60EC SG_ 640 MO1_Verlustmo 500;
BA_REL_ "GenSigTimeoutTime" BU_SG_REL_ Bremse_MK70MABS SG_ 640 MO1_Verlustmo 500;
BA_REL_ "GenSigTimeoutTime" BU_SG_REL_ Bremse_TRW_EBC450M SG_ 640 MO1_Verlustmo 500;
BA_REL_ "GenSigTimeoutTime" BU_SG_REL_ Bremse_TRW_EBC450M SG_ 640 MO1_Verlustmo 500;
BA_REL_ "GenSigTimeoutTime" BU_SG_REL_ Bremse_TRW_ESP SG_ 640 MO1_Verlustmo 500;
BA_REL_ "GenSigTimeoutTime" BU_SG_REL_ Bremse_TRW_ESP SG_ 640 MO1_Verlustmo 500;
BA_REL_ "GenSigTimeoutTime" BU_SG_REL_ EPB_TRW SG_ 640 MO1_Verlustmo 500;
BA_REL_ "GenSigTimeoutTime" BU_SG_REL_ EPB_TRW_VW411CS SG_ 640 MO1_Verlustmo 500;
BA_REL_ "GenSigTimeoutTime" BU_SG_REL_ Getriebe_AG6 SG_ 640 MO1_Verlustmo 500;
BA_REL_ "GenSigTimeoutTime" BU_SG_REL_ Getriebe_DQ SG_ 640 MO1_Verlustmo 500;
BA_REL_ "GenSigTimeoutTime" BU_SG_REL_ Getriebe_DQ_Hyb SG_ 640 MO1_Verlustmo 500;
BA_REL_ "GenSigTimeoutTime" BU_SG_REL_ Getriebe_Sele SG_ 640 MO1_Verlustmo 500;
BA_REL_ "GenSigTimeoutTime" BU_SG_REL_ Magne_Ride SG_ 640 MO1_Verlustmo 500;
BA_REL_ "GenSigTimeoutTime" BU_SG_REL_ RKA_Plus SG_ 640 MO1_Verlustmo 500;
BA_REL_ "GenSigTimeoutTime" BU_SG_REL_ Allrad SG_ 640 MO1_Wunschmo 500;
BA_REL_ "GenSigTimeoutTime" BU_SG_REL_ Bremse_MK60EC SG_ 640 MO1_Wunschmo 500;
BA_REL_ "GenSigTimeoutTime" BU_SG_REL_ Bremse_MK70MABS SG_ 640 MO1_Wunschmo 500;
BA_REL_ "GenSigTimeoutTime" BU_SG_REL_ Bremse_TRW_EBC450M SG_ 640 MO1_Wunschmo 500;
BA_REL_ "GenSigTimeoutTime" BU_SG_REL_ Bremse_TRW_ESP SG_ 640 MO1_Wunschmo 500;
BA_REL_ "GenSigTimeoutTime" BU_SG_REL_ Daempfer SG_ 640 MO1_Wunschmo 500;
BA_REL_ "GenSigTimeoutTime" BU_SG_REL_ Getriebe_DQ SG_ 640 MO1_Wunschmo 500;
BA_REL_ "GenSigTimeoutTime" BU_SG_REL_ Getriebe_DQ_Hyb SG_ 640 MO1_Wunschmo 500;
BA_REL_ "GenSigTimeoutTime" BU_SG_REL_ Getriebe_Sele SG_ 640 MO1_Wunschmo 500;
BA_REL_ "GenSigTimeoutTime" BU_SG_REL_ Magne_Ride SG_ 640 MO1_Wunschmo 500;
BA_REL_ "GenSigTimeoutTime" BU_SG_REL_ Gateway_PQ35 SG_ 1420 M10_Anf_Kl75 1000;
BA_REL_ "GenSigTimeoutTime" BU_SG_REL_ Gateway_PQ35 SG_ 1420 M10_SpannungsAnf 1000;
BA_REL_ "GenSigTimeoutTime" BU_SG_REL_ Bremse_MK60EC SG_ 1420 M10_UDruckDyn 1000;
BA_REL_ "GenSigTimeoutTime" BU_SG_REL_ Bremse_MK60EC SG_ 1420 M10_Status_StSt 1000;
BA_REL_ "GenSigTimeoutTime" BU_SG_REL_ Bremse_TRW_EBC450M SG_ 1420 M10_Status_StSt 1000;
BA_REL_ "GenSigTimeoutTime" BU_SG_REL_ Bremse_TRW_ESP SG_ 1420 M10_Status_StSt 1000;
BA_REL_ "GenSigTimeoutTime" BU_SG_REL_ EPB_TRW SG_ 1420 M10_Status_StSt 1000;
BA_REL_ "GenSigTimeoutTime" BU_SG_REL_ Gateway_PQ35 SG_ 1420 M10_Status_StSt 1000;
BA_REL_ "GenSigTimeoutTime" BU_SG_REL_ Gateway_PQ35 SG_ 1420 M10_Status_StSt 1000;
BA_REL_ "GenSigTimeoutTime" BU_SG_REL_ Gateway_PQ35 SG_ 1420 M10_Status_StSt 1000;
BA_REL_ "GenSigTimeoutTime" BU_SG_REL_ Getriebe_DQ SG_ 1420 M10_Status_StSt 1000;
BA_REL_ "GenSigTimeoutTime" BU_SG_REL_ Getriebe_DQ_Hyb SG_ 1420 M10_Status_StSt 1000;
BA_REL_ "GenSigTimeoutTime" BU_SG_REL_ PDC_PLA SG_ 1420 M10_Status_StSt 1000;
BA_REL_ "GenSigTimeoutTime" BU_SG_REL_ AFS SG_ 1420 M10_MotorStopp 1000;
BA_REL_ "GenSigTimeoutTime" BU_SG_REL_ EPB_TRW SG_ 1420 M10_MotorStopp 1000;
BA_REL_ "GenSigTimeoutTime" BU_SG_REL_ Gateway_PQ35 SG_ 1420 M10_MotorStopp 1000;
BA_REL_ "GenSigTimeoutTime" BU_SG_REL_ Gateway_PQ35 SG_ 1420 M10_MotorStopp 1000;
BA_REL_ "GenSigTimeoutTime" BU_SG_REL_ Getriebe_DQ SG_ 1420 M10_MotorStopp 1000;
BA_REL_ "GenSigTimeoutTime" BU_SG_REL_ Getriebe_DQ_Hyb SG_ 1420 M10_MotorStopp 1000;
BA_REL_ "GenSigTimeoutTime" BU_SG_REL_ LWR SG_ 1420 M10_MotorStopp 1000;
BA_REL_ "GenSigTimeoutTime" BU_SG_REL_ AFS SG_ 1420 M10_Wiederstart 1000;
BA_REL_ "GenSigTimeoutTime" BU_SG_REL_ Bremse_MK60EC SG_ 1420 M10_Wiederstart 1000;
BA_REL_ "GenSigTimeoutTime" BU_SG_REL_ Bremse_TRW_EBC450M SG_ 1420 M10_Wiederstart 1000;
BA_REL_ "GenSigTimeoutTime" BU_SG_REL_ Bremse_TRW_ESP SG_ 1420 M10_Wiederstart 1000;
BA_REL_ "GenSigTimeoutTime" BU_SG_REL_ EPB_TRW SG_ 1420 M10_Wiederstart 1000;
BA_REL_ "GenSigTimeoutTime" BU_SG_REL_ EPB_TRW_VW411CS SG_ 1420 M10_Wiederstart 1000;
BA_REL_ "GenSigTimeoutTime" BU_SG_REL_ FLA SG_ 1420 M10_Wiederstart 1000;
BA_REL_ "GenSigTimeoutTime" BU_SG_REL_ Gateway_PQ35 SG_ 1420 M10_Wiederstart 1000;
BA_REL_ "GenSigTimeoutTime" BU_SG_REL_ Gateway_PQ35 SG_ 1420 M10_Wiederstart 1000;
BA_REL_ "GenSigTimeoutTime" BU_SG_REL_ Getriebe_DQ SG_ 1420 M10_Wiederstart 1000;
BA_REL_ "GenSigTimeoutTime" BU_SG_REL_ Getriebe_DQ_Hyb SG_ 1420 M10_Wiederstart 1000;
BA_REL_ "GenSigTimeoutTime" BU_SG_REL_ LWR SG_ 1420 M10_Wiederstart 1000;
BA_REL_ "GenSigTimeoutTime" BU_SG_REL_ PDC_PLA SG_ 1420 M10_Wiederstart 1000;
BA_REL_ "GenSigTimeoutTime" BU_SG_REL_ Bremse_MK60EC SG_ 1420 M10_Schubabschaltung 1000;
BA_REL_ "GenSigTimeoutTime" BU_SG_REL_ Bremse_TRW_EBC450M SG_ 1420 M10_Schubabschaltung 1000;
BA_REL_ "GenSigTimeoutTime" BU_SG_REL_ Bremse_TRW_EBC450M SG_ 1420 M10_Druck_err_gem 1000;
BA_REL_ "GenSigTimeoutTime" BU_SG_REL_ Gateway_PQ35 SG_ 1420 M10_Freigabe_Reku 1000;
BA_REL_ "GenSigTimeoutTime" BU_SG_REL_ Bremse_MK60EC SG_ 1420 M10_rel_Saugrohrdruck 1000;
BA_REL_ "GenSigTimeoutTime" BU_SG_REL_ Bremse_TRW_EBC450M SG_ 1420 M10_rel_Saugrohrdruck 1000;
BA_REL_ "GenSigTimeoutTime" BU_SG_REL_ LH_EPS_ZF_2G SG_ 1420 M10_Fahrbereitschaft 1000;
BA_REL_ "GenSigTimeoutTime" BU_SG_REL_ LH_EPS_ZF_3G SG_ 1420 M10_Fahrbereitschaft 1000;
BA_REL_ "GenSigTimeoutTime" BU_SG_REL_ LH_EPS_ZF_2G SG_ 1420 M10_Hybrid 1000;
BA_REL_ "GenSigTimeoutTime" BU_SG_REL_ LH_EPS_ZF_3G SG_ 1420 M10_Hybrid 1000;
BA_REL_ "GenSigTimeoutTime" BU_SG_REL_ Bremse_MK60EC SG_ 1420 M10_StartStopp_Fahrerwunsch 1000;
BA_REL_ "GenSigTimeoutTime" BU_SG_REL_ Bremse_TRW_EBC450M SG_ 1420 M10_StartStopp_Fahrerwunsch 1000;
BA_REL_ "GenSigTimeoutTime" BU_SG_REL_ Bremse_TRW_ESP SG_ 1420 M10_StartStopp_Fahrerwunsch 1000;
BA_REL_ "GenSigTimeoutTime" BU_SG_REL_ Gateway_PQ35 SG_ 1420 M10_StartStopp_Fahrerwunsch 1000;
BA_REL_ "GenSigTimeoutTime" BU_SG_REL_ Gateway_PQ35 SG_ 1420 M10_StartStopp_Fahrerwunsch 1000;
BA_REL_ "GenSigTimeoutTime" BU_SG_REL_ Getriebe_DQ SG_ 1420 M10_StartStopp_Fahrerwunsch 1000;
BA_REL_ "GenSigTimeoutTime" BU_SG_REL_ Getriebe_DQ_Hyb SG_ 1420 M10_StartStopp_Fahrerwunsch 1000;
BA_REL_ "GenSigTimeoutTime" BU_SG_REL_ PDC_PLA SG_ 1420 M10_StartStopp_Fahrerwunsch 1000;
BA_REL_ "GenSigTimeoutTime" BU_SG_REL_ Gateway_PQ35 SG_ 1450 MO_Heizstrom_SCR 5000;
BA_REL_ "GenSigTimeoutTime" BU_SG_REL_ Gateway_PQ35 SG_ 1450 MO_Heizstrom_EKAT 5000;
BA_REL_ "GenSigTimeoutTime" BU_SG_REL_ Ladegeraet_EGolf SG_ 1407 MO_Charisma_FahrPr 500;
BA_REL_ "GenSigTimeoutTime" BU_SG_REL_ Ladegeraet_EGolf SG_ 1407 MO_Charisma_Status 500;
BA_REL_ "GenSigTimeoutTime" BU_SG_REL_ Ladegeraet_EGolf SG_ 1407 GE_Charisma_FahrPr 500;
BA_REL_ "GenSigTimeoutTime" BU_SG_REL_ Ladegeraet_EGolf SG_ 1407 GE_Charisma_Status 500;
BA_REL_ "GenSigTimeoutTime" BU_SG_REL_ Getriebe_AG6 SG_ 648 MO2_CAN_Vers 500;
BA_REL_ "GenSigTimeoutTime" BU_SG_REL_ Getriebe_DQ SG_ 648 MO2_CAN_Vers 500;
BA_REL_ "GenSigTimeoutTime" BU_SG_REL_ Getriebe_DQ_Hyb SG_ 648 MO2_CAN_Vers 500;
BA_REL_ "GenSigTimeoutTime" BU_SG_REL_ Getriebe_Sele SG_ 648 MO2_CAN_Vers 500;
BA_REL_ "GenSigTimeoutTime" BU_SG_REL_ Bremse_MK60EC SG_ 648 MO2_Motor_Code 500;
BA_REL_ "GenSigTimeoutTime" BU_SG_REL_ Bremse_MK70MABS SG_ 648 MO2_Motor_Code 500;
BA_REL_ "GenSigTimeoutTime" BU_SG_REL_ EPB_TRW SG_ 648 MO2_Motor_Code 500;
BA_REL_ "GenSigTimeoutTime" BU_SG_REL_ EPB_TRW_VW411CS SG_ 648 MO2_Motor_Code 500;
BA_REL_ "GenSigTimeoutTime" BU_SG_REL_ Getriebe_AG6 SG_ 648 MO2_Motor_Code 500;
BA_REL_ "GenSigTimeoutTime" BU_SG_REL_ Getriebe_DQ SG_ 648 MO2_Motor_Code 500;
BA_REL_ "GenSigTimeoutTime" BU_SG_REL_ Getriebe_DQ_Hyb SG_ 648 MO2_Motor_Code 500;
BA_REL_ "GenSigTimeoutTime" BU_SG_REL_ Getriebe_Sele SG_ 648 MO2_Motor_Code 500;
BA_REL_ "GenSigTimeoutTime" BU_SG_REL_ Bremse_MK60EC SG_ 648 MO2_Getr_Code 500;
BA_REL_ "GenSigTimeoutTime" BU_SG_REL_ Bremse_MK70MABS SG_ 648 MO2_Getr_Code 500;
BA_REL_ "GenSigTimeoutTime" BU_SG_REL_ Bremse_TRW_EBC450M SG_ 648 MO2_Getr_Code 500;
BA_REL_ "GenSigTimeoutTime" BU_SG_REL_ Bremse_TRW_ESP SG_ 648 MO2_Getr_Code 500;
BA_REL_ "GenSigTimeoutTime" BU_SG_REL_ EPB_TRW SG_ 648 MO2_Getr_Code 500;
BA_REL_ "GenSigTimeoutTime" BU_SG_REL_ EPB_TRW_VW411CS SG_ 648 MO2_Getr_Code 500;
BA_REL_ "GenSigTimeoutTime" BU_SG_REL_ Gateway_PQ35 SG_ 648 MO2_Getr_Code 500;
BA_REL_ "GenSigTimeoutTime" BU_SG_REL_ Gateway_PQ35 SG_ 648 MO2_Getr_Code 500;
BA_REL_ "GenSigTimeoutTime" BU_SG_REL_ Getriebe_AG6 SG_ 648 MO2_Getr_Code 500;
BA_REL_ "GenSigTimeoutTime" BU_SG_REL_ Getriebe_DQ SG_ 648 MO2_Getr_Code 500;
BA_REL_ "GenSigTimeoutTime" BU_SG_REL_ Getriebe_DQ_Hyb SG_ 648 MO2_Getr_Code 500;
BA_REL_ "GenSigTimeoutTime" BU_SG_REL_ Getriebe_Sele SG_ 648 MO2_Getr_Code 500;
BA_REL_ "GenSigTimeoutTime" BU_SG_REL_ RKA_Plus SG_ 648 MO2_Getr_Code 500;
BA_REL_ "GenSigTimeoutTime" BU_SG_REL_ Allrad SG_ 648 MO2_max_Mo 500;
BA_REL_ "GenSigTimeoutTime" BU_SG_REL_ Bremse_MK60EC SG_ 648 MO2_max_Mo 500;
BA_REL_ "GenSigTimeoutTime" BU_SG_REL_ Bremse_TRW_EBC450M SG_ 648 MO2_max_Mo 500;
BA_REL_ "GenSigTimeoutTime" BU_SG_REL_ Bremse_TRW_EBC450M SG_ 648 MO2_max_Mo 500;
BA_REL_ "GenSigTimeoutTime" BU_SG_REL_ Bremse_TRW_ESP SG_ 648 MO2_max_Mo 500;
BA_REL_ "GenSigTimeoutTime" BU_SG_REL_ Bremse_TRW_ESP SG_ 648 MO2_max_Mo 500;
BA_REL_ "GenSigTimeoutTime" BU_SG_REL_ EPB_TRW SG_ 648 MO2_max_Mo 500;
BA_REL_ "GenSigTimeoutTime" BU_SG_REL_ EPB_TRW_VW411CS SG_ 648 MO2_max_Mo 500;
BA_REL_ "GenSigTimeoutTime" BU_SG_REL_ Getriebe_AG6 SG_ 648 MO2_max_Mo 500;
BA_REL_ "GenSigTimeoutTime" BU_SG_REL_ Getriebe_DQ SG_ 648 MO2_max_Mo 500;
BA_REL_ "GenSigTimeoutTime" BU_SG_REL_ Getriebe_DQ_Hyb SG_ 648 MO2_max_Mo 500;
BA_REL_ "GenSigTimeoutTime" BU_SG_REL_ Getriebe_Sele SG_ 648 MO2_max_Mo 500;
BA_REL_ "GenSigTimeoutTime" BU_SG_REL_ RKA_Plus SG_ 648 MO2_max_Mo 500;
BA_REL_ "GenSigTimeoutTime" BU_SG_REL_ Allrad SG_ 648 MO2_Mp_Code 500;
BA_REL_ "GenSigTimeoutTime" BU_SG_REL_ Bremse_MK60EC SG_ 648 MO2_Mp_Code 500;
BA_REL_ "GenSigTimeoutTime" BU_SG_REL_ Bremse_MK60EC SG_ 648 MO2_Mp_Code 500;
BA_REL_ "GenSigTimeoutTime" BU_SG_REL_ Bremse_MK70MABS SG_ 648 MO2_Mp_Code 500;
BA_REL_ "GenSigTimeoutTime" BU_SG_REL_ Bremse_TRW_EBC450M SG_ 648 MO2_Mp_Code 500;
BA_REL_ "GenSigTimeoutTime" BU_SG_REL_ Bremse_TRW_EBC450M SG_ 648 MO2_Mp_Code 500;
BA_REL_ "GenSigTimeoutTime" BU_SG_REL_ Bremse_TRW_ESP SG_ 648 MO2_Mp_Code 500;
BA_REL_ "GenSigTimeoutTime" BU_SG_REL_ Bremse_TRW_ESP SG_ 648 MO2_Mp_Code 500;
BA_REL_ "GenSigTimeoutTime" BU_SG_REL_ EPB_TRW SG_ 648 MO2_Mp_Code 500;
BA_REL_ "GenSigTimeoutTime" BU_SG_REL_ EPB_TRW_VW411CS SG_ 648 MO2_Mp_Code 500;
BA_REL_ "GenSigTimeoutTime" BU_SG_REL_ Gateway_PQ35 SG_ 648 MO2_Mp_Code 500;
BA_REL_ "GenSigTimeoutTime" BU_SG_REL_ Gateway_PQ35 SG_ 648 MO2_Mp_Code 500;
BA_REL_ "GenSigTimeoutTime" BU_SG_REL_ Getriebe_AG6 SG_ 648 MO2_Mp_Code 500;
BA_REL_ "GenSigTimeoutTime" BU_SG_REL_ Getriebe_DQ SG_ 648 MO2_Mp_Code 500;
BA_REL_ "GenSigTimeoutTime" BU_SG_REL_ Getriebe_DQ_Hyb SG_ 648 MO2_Mp_Code 500;
BA_REL_ "GenSigTimeoutTime" BU_SG_REL_ Getriebe_Sele SG_ 648 MO2_Mp_Code 500;
BA_REL_ "GenSigTimeoutTime" BU_SG_REL_ RKA_Plus SG_ 648 MO2_Mp_Code 500;
BA_REL_ "GenSigTimeoutTime" BU_SG_REL_ Gateway_PQ35 SG_ 648 MO2_Kuehlm_T 500;
BA_REL_ "GenSigTimeoutTime" BU_SG_REL_ Gateway_PQ35 SG_ 648 MO2_Kuehlm_T 500;
BA_REL_ "GenSigTimeoutTime" BU_SG_REL_ Getriebe_AG6 SG_ 648 MO2_Kuehlm_T 500;
BA_REL_ "GenSigTimeoutTime" BU_SG_REL_ Getriebe_DQ SG_ 648 MO2_Kuehlm_T 500;
BA_REL_ "GenSigTimeoutTime" BU_SG_REL_ Getriebe_DQ_Hyb SG_ 648 MO2_Kuehlm_T 500;
BA_REL_ "GenSigTimeoutTime" BU_SG_REL_ Getriebe_Sele SG_ 648 MO2_Kuehlm_T 500;
BA_REL_ "GenSigTimeoutTime" BU_SG_REL_ LEH_Hybrid SG_ 648 MO2_Kuehlm_T 500;
BA_REL_ "GenSigTimeoutTime" BU_SG_REL_ Magne_Ride SG_ 648 MO2_Kuehlm_T 500;
BA_REL_ "GenSigTimeoutTime" BU_SG_REL_ RKA_Plus SG_ 648 MO2_Kuehlm_T 500;
BA_REL_ "GenSigTimeoutTime" BU_SG_REL_ Allrad SG_ 648 MO2_BLS 500;
BA_REL_ "GenSigTimeoutTime" BU_SG_REL_ Bremse_TRW_EBC450M SG_ 648 MO2_BLS 500;
BA_REL_ "GenSigTimeoutTime" BU_SG_REL_ Bremse_TRW_ESP SG_ 648 MO2_BLS 500;
BA_REL_ "GenSigTimeoutTime" BU_SG_REL_ Daempfer SG_ 648 MO2_BLS 500;
BA_REL_ "GenSigTimeoutTime" BU_SG_REL_ EPB_TRW SG_ 648 MO2_BLS 500;
BA_REL_ "GenSigTimeoutTime" BU_SG_REL_ EPB_TRW_VW411CS SG_ 648 MO2_BLS 500;
BA_REL_ "GenSigTimeoutTime" BU_SG_REL_ Gateway_PQ35 SG_ 648 MO2_BLS 500;
BA_REL_ "GenSigTimeoutTime" BU_SG_REL_ Getriebe_AG6 SG_ 648 MO2_BLS 500;
BA_REL_ "GenSigTimeoutTime" BU_SG_REL_ Getriebe_DQ SG_ 648 MO2_BLS 500;
BA_REL_ "GenSigTimeoutTime" BU_SG_REL_ Getriebe_DQ_Hyb SG_ 648 MO2_BLS 500;
BA_REL_ "GenSigTimeoutTime" BU_SG_REL_ Getriebe_Sele SG_ 648 MO2_BLS 500;
BA_REL_ "GenSigTimeoutTime" BU_SG_REL_ Magne_Ride SG_ 648 MO2_BLS 500;
BA_REL_ "GenSigTimeoutTime" BU_SG_REL_ PDC_PLA SG_ 648 MO2_BLS 500;
BA_REL_ "GenSigTimeoutTime" BU_SG_REL_ Allrad SG_ 648 MO2_BTS 500;
BA_REL_ "GenSigTimeoutTime" BU_SG_REL_ Getriebe_AG6 SG_ 648 MO2_BTS 500;
BA_REL_ "GenSigTimeoutTime" BU_SG_REL_ Getriebe_DQ SG_ 648 MO2_BTS 500;
BA_REL_ "GenSigTimeoutTime" BU_SG_REL_ Getriebe_DQ_Hyb SG_ 648 MO2_BTS 500;
BA_REL_ "GenSigTimeoutTime" BU_SG_REL_ Getriebe_Sele SG_ 648 MO2_BTS 500;
BA_REL_ "GenSigTimeoutTime" BU_SG_REL_ Magne_Ride SG_ 648 MO2_BTS 500;
BA_REL_ "GenSigTimeoutTime" BU_SG_REL_ Getriebe_AG6 SG_ 648 MO2_Sta_Kuehlm 500;
BA_REL_ "GenSigTimeoutTime" BU_SG_REL_ Getriebe_DQ SG_ 648 MO2_Sta_Kuehlm 500;
BA_REL_ "GenSigTimeoutTime" BU_SG_REL_ Getriebe_DQ_Hyb SG_ 648 MO2_Sta_Kuehlm 500;
BA_REL_ "GenSigTimeoutTime" BU_SG_REL_ LEH_Hybrid SG_ 648 MO2_Sta_Kuehlm 500;
BA_REL_ "GenSigTimeoutTime" BU_SG_REL_ Getriebe_AG6 SG_ 648 MO2_Sta_Klima 500;
BA_REL_ "GenSigTimeoutTime" BU_SG_REL_ Getriebe_DQ SG_ 648 MO2_Sta_Klima 500;
BA_REL_ "GenSigTimeoutTime" BU_SG_REL_ Getriebe_DQ_Hyb SG_ 648 MO2_Sta_Klima 500;
BA_REL_ "GenSigTimeoutTime" BU_SG_REL_ Bremse_MK60EC SG_ 648 MO2_Sta_No_Bet 500;
BA_REL_ "GenSigTimeoutTime" BU_SG_REL_ Bremse_MK70MABS SG_ 648 MO2_Sta_No_Bet 500;
BA_REL_ "GenSigTimeoutTime" BU_SG_REL_ Bremse_TRW_EBC450M SG_ 648 MO2_Sta_No_Bet 500;
BA_REL_ "GenSigTimeoutTime" BU_SG_REL_ Bremse_TRW_ESP SG_ 648 MO2_Sta_No_Bet 500;
BA_REL_ "GenSigTimeoutTime" BU_SG_REL_ Getriebe_DQ SG_ 648 MO2_Sta_No_Bet 500;
BA_REL_ "GenSigTimeoutTime" BU_SG_REL_ Getriebe_DQ_Hyb SG_ 648 MO2_Sta_No_Bet 500;
BA_REL_ "GenSigTimeoutTime" BU_SG_REL_ Getriebe_DQ SG_ 648 MO2_Status_TSK 500;
BA_REL_ "GenSigTimeoutTime" BU_SG_REL_ Bremse_MK60EC SG_ 648 MO2_Sta_GRA 500;
BA_REL_ "GenSigTimeoutTime" BU_SG_REL_ Bremse_TRW_EBC450M SG_ 648 MO2_Sta_GRA 500;
BA_REL_ "GenSigTimeoutTime" BU_SG_REL_ Bremse_TRW_EBC450M SG_ 648 MO2_Sta_GRA 500;
BA_REL_ "GenSigTimeoutTime" BU_SG_REL_ Bremse_TRW_ESP SG_ 648 MO2_Sta_GRA 500;
BA_REL_ "GenSigTimeoutTime" BU_SG_REL_ Bremse_TRW_ESP SG_ 648 MO2_Sta_GRA 500;
BA_REL_ "GenSigTimeoutTime" BU_SG_REL_ Gateway_PQ35 SG_ 648 MO2_Sta_GRA 500;
BA_REL_ "GenSigTimeoutTime" BU_SG_REL_ Getriebe_AG6 SG_ 648 MO2_Sta_GRA 500;
BA_REL_ "GenSigTimeoutTime" BU_SG_REL_ Getriebe_DQ SG_ 648 MO2_Sta_GRA 500;
BA_REL_ "GenSigTimeoutTime" BU_SG_REL_ Getriebe_DQ_Hyb SG_ 648 MO2_Sta_GRA 500;
BA_REL_ "GenSigTimeoutTime" BU_SG_REL_ Getriebe_Sele SG_ 648 MO2_Sta_GRA 500;
BA_REL_ "GenSigTimeoutTime" BU_SG_REL_ RKA_Plus SG_ 648 MO2_Sta_GRA 500;
BA_REL_ "GenSigTimeoutTime" BU_SG_REL_ Gateway_PQ35 SG_ 648 MO2_GRAregelt 500;
BA_REL_ "GenSigTimeoutTime" BU_SG_REL_ Getriebe_DQ SG_ 648 MO2_GRAregelt 500;
BA_REL_ "GenSigTimeoutTime" BU_SG_REL_ Getriebe_DQ_Hyb SG_ 648 MO2_GRAregelt 500;
BA_REL_ "GenSigTimeoutTime" BU_SG_REL_ Bremse_TRW_EBC450M SG_ 648 MO2_OffRoad 500;
BA_REL_ "GenSigTimeoutTime" BU_SG_REL_ Bremse_TRW_ESP SG_ 648 MO2_OffRoad 500;
BA_REL_ "GenSigTimeoutTime" BU_SG_REL_ Getriebe_AG6 SG_ 648 MO2_OffRoad 500;
BA_REL_ "GenSigTimeoutTime" BU_SG_REL_ Getriebe_DQ SG_ 648 MO2_OffRoad 500;
BA_REL_ "GenSigTimeoutTime" BU_SG_REL_ Getriebe_DQ_Hyb SG_ 648 MO2_OffRoad 500;
BA_REL_ "GenSigTimeoutTime" BU_SG_REL_ Gateway_PQ35 SG_ 648 MO2_GRA_Soll 500;
BA_REL_ "GenSigTimeoutTime" BU_SG_REL_ Getriebe_AG6 SG_ 648 MO2_GRA_Soll 500;
BA_REL_ "GenSigTimeoutTime" BU_SG_REL_ Getriebe_DQ SG_ 648 MO2_GRA_Soll 500;
BA_REL_ "GenSigTimeoutTime" BU_SG_REL_ Getriebe_DQ_Hyb SG_ 648 MO2_GRA_Soll 500;
BA_REL_ "GenSigTimeoutTime" BU_SG_REL_ Bremse_TRW_EBC450M SG_ 648 MO2_LL_Solldz 500;
BA_REL_ "GenSigTimeoutTime" BU_SG_REL_ Bremse_TRW_ESP SG_ 648 MO2_LL_Solldz 500;
BA_REL_ "GenSigTimeoutTime" BU_SG_REL_ Gateway_PQ35 SG_ 648 MO2_LL_Solldz 500;
BA_REL_ "GenSigTimeoutTime" BU_SG_REL_ Getriebe_AG6 SG_ 648 MO2_LL_Solldz 500;
BA_REL_ "GenSigTimeoutTime" BU_SG_REL_ Getriebe_DQ SG_ 648 MO2_LL_Solldz 500;
BA_REL_ "GenSigTimeoutTime" BU_SG_REL_ Getriebe_DQ_Hyb SG_ 648 MO2_LL_Solldz 500;
BA_REL_ "GenSigTimeoutTime" BU_SG_REL_ Getriebe_Sele SG_ 648 MO2_LL_Solldz 500;
BA_REL_ "GenSigTimeoutTime" BU_SG_REL_ Getriebe_AG6 SG_ 648 MO2_Begr_Mo 500;
BA_REL_ "GenSigTimeoutTime" BU_SG_REL_ Getriebe_DQ SG_ 648 MO2_Begr_Mo 500;
BA_REL_ "GenSigTimeoutTime" BU_SG_REL_ Getriebe_DQ_Hyb SG_ 648 MO2_Begr_Mo 500;
BA_REL_ "GenSigTimeoutTime" BU_SG_REL_ Getriebe_AG6 SG_ 648 MO2_Mo_ZWR 500;
BA_REL_ "GenSigTimeoutTime" BU_SG_REL_ Getriebe_DQ SG_ 648 MO2_Mo_ZWR 500;
BA_REL_ "GenSigTimeoutTime" BU_SG_REL_ Getriebe_DQ_Hyb SG_ 648 MO2_Mo_ZWR 500;
BA_REL_ "GenSigTimeoutTime" BU_SG_REL_ Getriebe_DQ SG_ 896 MO3_Vorgluehen 500;
BA_REL_ "GenSigTimeoutTime" BU_SG_REL_ Getriebe_DQ_Hyb SG_ 896 MO3_Vorgluehen 500;
BA_REL_ "GenSigTimeoutTime" BU_SG_REL_ Getriebe_DQ SG_ 896 MO3_Prio_Dz 500;
BA_REL_ "GenSigTimeoutTime" BU_SG_REL_ Getriebe_DQ_Hyb SG_ 896 MO3_Prio_Dz 500;
BA_REL_ "GenSigTimeoutTime" BU_SG_REL_ Gateway_PQ35 SG_ 896 MO_Schalter_StartStopp 500;
BA_REL_ "GenSigTimeoutTime" BU_SG_REL_ Getriebe_DQ SG_ 896 MO_Schalter_StartStopp 500;
BA_REL_ "GenSigTimeoutTime" BU_SG_REL_ Getriebe_DQ_Hyb SG_ 896 MO_Schalter_StartStopp 500;
BA_REL_ "GenSigTimeoutTime" BU_SG_REL_ Getriebe_AG6 SG_ 896 MO3_Winterprg 500;
BA_REL_ "GenSigTimeoutTime" BU_SG_REL_ Getriebe_DQ SG_ 896 MO3_Winterprg 500;
BA_REL_ "GenSigTimeoutTime" BU_SG_REL_ Getriebe_DQ_Hyb SG_ 896 MO3_Winterprg 500;
BA_REL_ "GenSigTimeoutTime" BU_SG_REL_ EPB_TRW SG_ 896 MO3_Sta_Pedal 500;
BA_REL_ "GenSigTimeoutTime" BU_SG_REL_ EPB_TRW_VW411CS SG_ 896 MO3_Sta_Pedal 500;
BA_REL_ "GenSigTimeoutTime" BU_SG_REL_ Getriebe_DQ SG_ 896 MO3_Sta_Pedal 500;
BA_REL_ "GenSigTimeoutTime" BU_SG_REL_ Getriebe_DQ_Hyb SG_ 896 MO3_Sta_Pedal 500;
BA_REL_ "GenSigTimeoutTime" BU_SG_REL_ Bremse_MK60EC SG_ 896 MO3_Sta_FPG 500;
BA_REL_ "GenSigTimeoutTime" BU_SG_REL_ Bremse_MK60EC SG_ 896 MO3_Sign_FPG 500;
BA_REL_ "GenSigTimeoutTime" BU_SG_REL_ Getriebe_DQ SG_ 896 MO3_Sta_Temp 500;
BA_REL_ "GenSigTimeoutTime" BU_SG_REL_ Getriebe_DQ_Hyb SG_ 896 MO3_Sta_Temp 500;
BA_REL_ "GenSigTimeoutTime" BU_SG_REL_ Getriebe_DQ SG_ 896 MO3_Aussentemp 500;
BA_REL_ "GenSigTimeoutTime" BU_SG_REL_ Getriebe_DQ_Hyb SG_ 896 MO3_Aussentemp 500;
BA_REL_ "GenSigTimeoutTime" BU_SG_REL_ Magne_Ride SG_ 896 MO3_Aussentemp 500;
BA_REL_ "GenSigTimeoutTime" BU_SG_REL_ Bremse_MK60EC SG_ 896 MO3_Pedalwert 500;
BA_REL_ "GenSigTimeoutTime" BU_SG_REL_ Bremse_TRW_EBC450M SG_ 896 MO3_Pedalwert 500;
BA_REL_ "GenSigTimeoutTime" BU_SG_REL_ Bremse_TRW_ESP SG_ 896 MO3_Pedalwert 500;
BA_REL_ "GenSigTimeoutTime" BU_SG_REL_ EPB_TRW SG_ 896 MO3_Pedalwert 500;
BA_REL_ "GenSigTimeoutTime" BU_SG_REL_ EPB_TRW_VW411CS SG_ 896 MO3_Pedalwert 500;
BA_REL_ "GenSigTimeoutTime" BU_SG_REL_ Gateway_PQ35 SG_ 896 MO3_Pedalwert 500;
BA_REL_ "GenSigTimeoutTime" BU_SG_REL_ Getriebe_AG6 SG_ 896 MO3_Pedalwert 500;
BA_REL_ "GenSigTimeoutTime" BU_SG_REL_ Getriebe_DQ SG_ 896 MO3_Pedalwert 500;
BA_REL_ "GenSigTimeoutTime" BU_SG_REL_ Getriebe_DQ_Hyb SG_ 896 MO3_Pedalwert 500;
BA_REL_ "GenSigTimeoutTime" BU_SG_REL_ HCA SG_ 896 MO3_Pedalwert 500;
BA_REL_ "GenSigTimeoutTime" BU_SG_REL_ Magne_Ride SG_ 896 MO3_Pedalwert 500;
BA_REL_ "GenSigTimeoutTime" BU_SG_REL_ Getriebe_DQ SG_ 896 MO3_Rad_Wu_Mo 500;
BA_REL_ "GenSigTimeoutTime" BU_SG_REL_ Getriebe_DQ_Hyb SG_ 896 MO3_Rad_Wu_Mo 500;
BA_REL_ "GenSigTimeoutTime" BU_SG_REL_ Getriebe_DQ SG_ 896 MO3_Vorz_RadWu 500;
BA_REL_ "GenSigTimeoutTime" BU_SG_REL_ Getriebe_DQ_Hyb SG_ 896 MO3_Vorz_RadWu 500;
BA_REL_ "GenSigTimeoutTime" BU_SG_REL_ Getriebe_DQ SG_ 896 MO3_Freigabe_Segeln 500;
BA_REL_ "GenSigTimeoutTime" BU_SG_REL_ Getriebe_DQ_Hyb SG_ 896 MO3_Freigabe_Segeln 500;
BA_REL_ "GenSigTimeoutTime" BU_SG_REL_ Getriebe_DQ SG_ 896 MO3_WunschDz 500;
BA_REL_ "GenSigTimeoutTime" BU_SG_REL_ Getriebe_DQ_Hyb SG_ 896 MO3_WunschDz 500;
BA_REL_ "GenSigTimeoutTime" BU_SG_REL_ Bremse_MK60EC SG_ 896 MO3_FPGradient 500;
BA_REL_ "GenSigTimeoutTime" BU_SG_REL_ Allrad SG_ 1152 MO5_Motortyp 500;
BA_REL_ "GenSigTimeoutTime" BU_SG_REL_ Bremse_MK60EC SG_ 1152 MO5_Motortyp 500;
BA_REL_ "GenSigTimeoutTime" BU_SG_REL_ Bremse_MK60EC SG_ 1152 MO5_Motortyp 500;
BA_REL_ "GenSigTimeoutTime" BU_SG_REL_ Bremse_TRW_EBC450M SG_ 1152 MO5_Motortyp 500;
BA_REL_ "GenSigTimeoutTime" BU_SG_REL_ Bremse_TRW_ESP SG_ 1152 MO5_Motortyp 500;
BA_REL_ "GenSigTimeoutTime" BU_SG_REL_ Gateway_PQ35 SG_ 1152 MO5_Motortyp 500;
BA_REL_ "GenSigTimeoutTime" BU_SG_REL_ RKA_Plus SG_ 1152 MO5_Motortyp 500;
BA_REL_ "GenSigTimeoutTime" BU_SG_REL_ BMS_Hybrid SG_ 1152 MO5_Abgastyp 500;
BA_REL_ "GenSigTimeoutTime" BU_SG_REL_ LEH_Hybrid SG_ 1152 MO5_Abgastyp 500;
BA_REL_ "GenSigTimeoutTime" BU_SG_REL_ BMS_Hybrid SG_ 1152 MO5_Abgastyp2 500;
BA_REL_ "GenSigTimeoutTime" BU_SG_REL_ LEH_Hybrid SG_ 1152 MO5_Abgastyp2 500;
BA_REL_ "GenSigTimeoutTime" BU_SG_REL_ BMS_Hybrid SG_ 1152 OBD_Kaltstart_Denominator 500;
BA_REL_ "GenSigTimeoutTime" BU_SG_REL_ LEH_Hybrid SG_ 1152 OBD_Kaltstart_Denominator 500;
BA_REL_ "GenSigTimeoutTime" BU_SG_REL_ BMS_Hybrid SG_ 1152 OBD_Minimum_Trip 500;
BA_REL_ "GenSigTimeoutTime" BU_SG_REL_ Getriebe_DQ SG_ 1152 OBD_Minimum_Trip 500;
BA_REL_ "GenSigTimeoutTime" BU_SG_REL_ Getriebe_DQ_Hyb SG_ 1152 OBD_Minimum_Trip 500;
BA_REL_ "GenSigTimeoutTime" BU_SG_REL_ LEH_Hybrid SG_ 1152 OBD_Minimum_Trip 500;
BA_REL_ "GenSigTimeoutTime" BU_SG_REL_ Allrad SG_ 1152 MO5_Mp_Code 500;
BA_REL_ "GenSigTimeoutTime" BU_SG_REL_ BMS_Hybrid SG_ 1152 MO5_Mp_Code 500;
BA_REL_ "GenSigTimeoutTime" BU_SG_REL_ Bremse_MK60EC SG_ 1152 MO5_Mp_Code 500;
BA_REL_ "GenSigTimeoutTime" BU_SG_REL_ Bremse_MK60EC SG_ 1152 MO5_Mp_Code 500;
BA_REL_ "GenSigTimeoutTime" BU_SG_REL_ Bremse_TRW_EBC450M SG_ 1152 MO5_Mp_Code 500;
BA_REL_ "GenSigTimeoutTime" BU_SG_REL_ Bremse_TRW_ESP SG_ 1152 MO5_Mp_Code 500;
BA_REL_ "GenSigTimeoutTime" BU_SG_REL_ Gateway_PQ35 SG_ 1152 MO5_Mp_Code 500;
BA_REL_ "GenSigTimeoutTime" BU_SG_REL_ Gateway_PQ35 SG_ 1152 MO5_Mp_Code 500;
BA_REL_ "GenSigTimeoutTime" BU_SG_REL_ Getriebe_DQ SG_ 1152 MO5_Mp_Code 500;
BA_REL_ "GenSigTimeoutTime" BU_SG_REL_ Getriebe_DQ_Hyb SG_ 1152 MO5_Mp_Code 500;
BA_REL_ "GenSigTimeoutTime" BU_SG_REL_ LEH_Hybrid SG_ 1152 MO5_Mp_Code 500;
BA_REL_ "GenSigTimeoutTime" BU_SG_REL_ RKA_Plus SG_ 1152 MO5_Mp_Code 500;
BA_REL_ "GenSigTimeoutTime" BU_SG_REL_ Gateway_PQ35 SG_ 1152 MO5_Verbrauch 500;
BA_REL_ "GenSigTimeoutTime" BU_SG_REL_ Getriebe_DQ SG_ 1152 MO5_Luefter 500;
BA_REL_ "GenSigTimeoutTime" BU_SG_REL_ Getriebe_DQ_Hyb SG_ 1152 MO5_Luefter 500;
BA_REL_ "GenSigTimeoutTime" BU_SG_REL_ EPB_TRW_VW411CS SG_ 1152 MO5_Interlock 500;
BA_REL_ "GenSigTimeoutTime" BU_SG_REL_ Gateway_PQ35 SG_ 1152 MO5_Interlock 500;
BA_REL_ "GenSigTimeoutTime" BU_SG_REL_ Gateway_PQ35 SG_ 1152 MO5_Anlasser 500;
BA_REL_ "GenSigTimeoutTime" BU_SG_REL_ Bremse_MK60EC SG_ 1152 MO5_Momente 500;
BA_REL_ "GenSigTimeoutTime" BU_SG_REL_ Bremse_MK70MABS SG_ 1152 MO5_Momente 500;
BA_REL_ "GenSigTimeoutTime" BU_SG_REL_ EPB_TRW_VW411CS SG_ 1152 MO5_Momente 500;
BA_REL_ "GenSigTimeoutTime" BU_SG_REL_ Getriebe_AG6 SG_ 1152 MO5_Momente 500;
BA_REL_ "GenSigTimeoutTime" BU_SG_REL_ Getriebe_DQ SG_ 1152 MO5_Momente 500;
BA_REL_ "GenSigTimeoutTime" BU_SG_REL_ Getriebe_DQ_Hyb SG_ 1152 MO5_Momente 500;
BA_REL_ "GenSigTimeoutTime" BU_SG_REL_ RKA_Plus SG_ 1152 MO5_Momente 500;
BA_REL_ "GenSigTimeoutTime" BU_SG_REL_ Bremse_MK60EC SG_ 1152 MO5_Checksumme 500;
BA_REL_ "GenSigTimeoutTime" BU_SG_REL_ Bremse_MK70MABS SG_ 1152 MO5_Checksumme 500;
BA_REL_ "GenSigTimeoutTime" BU_SG_REL_ EPB_TRW_VW411CS SG_ 1152 MO5_Checksumme 500;
VAL_ 208 LH3_LMSign 0 "positives_Vorzeichen" 1 "negatives_Vorzeichen" ;
VAL_ 208 LH3_LMValid 0 "ungueltig" 1 "gueltig" ;
VAL_ 208 LH3_Sta_DSR 0 "DSR_deaktiviert" 1 "DSR_Anf_nicht_ausfuehrbar" 2 "Kom_ESP_gestoert" 3 "EPS_funktionsbereit" 4 "DSR_Anf_abgew" 5 "ext_Momeingriff_aktiv" 6 "ext_LWeingriff_aktiv" 7 "ext_MomLWeingriff_aktiv" ;
VAL_ 208 LH3_BLWSign 0 "positives_Vorzeichen" 1 "negatives_Vorzeichen" ;
VAL_ 208 LH3_BLWValid 0 "ungueltig" 1 "gueltig" ;
VAL_ 208 LH3_Lenkungstyp 0 "EPS_DSR1" 1 "APA" 2 "ADS_Audi_oder_CEPS_VW120" 3 "EPS_DSR2" ;
VAL_ 194 LW1_LRW_Sign 0 "positives_Vorzeichen" 1 "negatives_Vorzeichen" ;
VAL_ 194 LW1_Gesch_Sign 0 "positives_Vorzeichen" 1 "negatives_Vorzeichen" ;
VAL_ 194 LW1_ID 0 "noch_nicht_kalibriert" 128 "kalibriert" ;
VAL_ 194 LW1_Initquelle 0 "Bremse_3" 1 "EPS_Bit" ;
VAL_ 194 LW1_Status 0 "ok" 1 "no_init" 2 "sporadischer_Fehler" 3 "dauerhafter_Fehler" ;
VAL_ 194 LW1_Sta_KL30 0 "ok" 1 "no_init_s" ;
VAL_ 916 LRZ_Parameter 0 "Parametrisierung_nicht_erfolgt" 1 "Parametrisierung_erfolgt" ;
VAL_ 916 LRZ_Grundeinst 0 "Grundeinstellung_nicht_erfolgt" 1 "Grundeinstellung_erfolgt" ;
VAL_ 916 LRZ_Modus 0 "LWR_statisch" 1 "LWR_dynamisch" ;
VAL_ 916 LRZ_Initlauf 0 "Initlauf_nicht_erfolgt" 1 "Initialisierungslauf_erfolgt" ;
VAL_ 916 LRZ_Sichere_Pos 0 "Sicherheitsposition_aus" 1 "Sicherheitsposition_ein" ;
VAL_ 916 LRZ_LampeAFS 0 "Lampe_aus" 1 "Lampe_ein" ;
VAL_ 916 LRZ_Fehlerlampe 0 "Lampe_aus" 1 "Lampe_ein" ;
VAL_ 916 LRZ_Fehler 0 "kein_Fehlerspeichereintrag" 1 "Fehlerspeichereintrag" ;
VAL_ 916 LRZ_Einfedg_vo 127 "entspr_NN" 254 "nicht_initialisiert" 255 "Fehler" ;
VAL_ 916 LRZ_Einfedg_hi 127 "entspr_NN" 254 "nicht_initialisiert" 255 "Fehler" ;
VAL_ 916 LRZ_Stellung 254 "Init" 255 "Fehler" ;
VAL_ 916 LRZ_LeistDim 254 "Wert_unbekannt" 255 "Fehler" ;
VAL_ 916 LRZ_ELF_links 0 "keine_Ersatzlichtfunktion" 1 "Ersatzlichtfunktion" ;
VAL_ 916 LRZ_ELF_rechts 0 "keine_Ersatzlichtfunktion" 1 "Ersatzlichtfunktion" ;
VAL_ 916 LRZ_AFSLED_Blink 0 "nein" 1 "ja" ;
VAL_ 916 LRZ_AFSFehlertext 0 "kein_Text" 1 "Text_AFS_ohne_Funktion" ;
VAL_ 916 LRZ_Tourist_Fkt 0 "Tourist_Fkt_n_unterstuetzt" 1 "Tourist_Fkt_unterstuetzt" ;
VAL_ 916 LRZ_Tourist_aktiv 0 "Tourist_Fkt_deaktiv" 1 "Tourist_Fkt_aktiv" ;
VAL_ 916 LRZ_AFS_Absch 0 "keine_AFS_Deaktiv_n_unterst" 1 "AFS_Deaktiv_unterstuetzt" ;
VAL_ 916 LRZ_AFS_deaktiv 0 "AFS_aktiv" 1 "AFS_deaktiv" ;
VAL_ 916 LRZ_Abbiegelicht_Dimm_Anf 0 "keine_Dimmung" 1 "Dimmung_angefordert" ;
VAL_ 916 LRZ_Abbiegelicht_li_Anf 0 "Abbiegelicht_aus" 1 "Abbiegelicht_ein" ;
VAL_ 916 LRZ_Abbiegelicht_re_Anf 0 "Abbiegelicht_aus" 1 "Abbiegelicht_ein" ;
VAL_ 916 LRZ_Fernlicht_li_defekt 0 "Fernlicht_in_Ordnung" 1 "Fernlicht_defekt" ;
VAL_ 916 LRZ_Fernlicht_re_defekt 0 "Fernlicht_in_Ordnung" 1 "Fernlicht_defekt" ;
VAL_ 916 LRZ_Fernlicht_Status 0 "Fernlicht_aus" 1 "Fernlicht_ein" ;
VAL_ 916 LRZ_Verfuegbarkeit_GLW 0 "GLW_nicht_verfuegbar" 1 "GLW_verfuegbar" ;
VAL_ 916 LRZ_Status_adaptive_LV 0 "adaptive_Lichtverteilung_aus" 1 "adaptive_Lichtverteilung_an" ;
VAL_ 916 GLW_Sensor_blockiert 0 "Kamera_Sensor_nicht_blockiert" 1 "Kamera_Sensor_blockiert" ;
VAL_ 640 MO1_Leergas 0 "kein_Leergas" 1 "Leergas" ;
VAL_ 640 MO1_Sta_Pedal 0 "Fahrpedal_iO" 1 "Ersatzwert" ;
VAL_ 640 MO1_Kickdown 0 "kein_Kickdown" 1 "Kickdown" ;
VAL_ 640 MO1_Kup_schalt 0 "Schalter_sagt_ausgekuppelt" 1 "Schalter_sagt_eingekuppelt" ;
VAL_ 640 MO1_TiOut_Br 0 "Empfang_iO" 1 "Time_Out" ;
VAL_ 640 MO1_Sta_Bremse 0 "erfuellbar" 1 "statisch_nicht_erfuellbar" ;
VAL_ 640 MO1_Sta_Getr 0 "erfuellbar" 1 "dynamisch_nicht_erfuellbar" ;
VAL_ 640 MO1_Sta_MotMo 0 "nein_Werte_iO" 1 "ja" ;
VAL_ 640 MO1_Mo_m_ex 255 "Fehler" ;
VAL_ 640 MO1_Drehzahl 65280 "Fehler" ;
VAL_ 640 MO1_Mo_o_ex 255 "Fehler" ;
VAL_ 640 MO1_Pedalwert 255 "Fehler" ;
VAL_ 640 MO1_Verlustmo 255 "Fehler" ;
VAL_ 640 MO1_Wunschmo 255 "Fehler" ;
VAL_ 1420 M10_Anzeige 0 "keine_Anzeige" 1 "Motor_in_Stoppbetrieb_Symbol_A" 2 "Systemfehler_Start_Stopp" 3 "Motor_manuell_starten" 5 "Temporaer_nicht_verfuegbar_Symbol_durchgestr_A" 9 "Unerwuenschter_Motorstillstand" 12 "Motor_startet" 13 "Kupplung_betaetigen" 14 "Waehlhebel_in_P_N_Position" 15 "Bremse_treten" ;
VAL_ 1420 M10_Anf_Kl75 0 "Anf_Kl75_ausschalten" 1 "Anf_Kl75_einschalten" ;
VAL_ 1420 MSG_Remotestart_Betrieb 0 "kein_RS_Betrieb" 1 "RS_Betrieb" ;
VAL_ 1420 M10_SpannungsAnf 0 "keine_Anforderung" 1 "Anforderung" ;
VAL_ 1420 M10_UDruckDyn 0 "Dyn_1mal_groesser_50mbar" 1 "Dyn_immer_kleiner_50mbar" ;
VAL_ 1420 M10_Status_StSt 0 "System_in_diesem_KL15_Zyklus_nicht_verfuegbar" 1 "System_aktiv_keine_Freigabe_durch_StartStop_Koordinator" 2 "System_aktiv_alle Freigaben_liegen_vor" 3 "System_aktiv_mindestens_eine_Freigabe_fehlt" ;
VAL_ 1420 M10_MotorStopp 0 "Motor_Stopp_inaktiv" 1 "Motor_Stopp_aktiv" ;
VAL_ 1420 M10_Wiederstart 0 "Wiederstart_inaktiv" 1 "Wiederstart_aktiv" ;
VAL_ 1420 M10_Schubabschaltung 0 "keine_Schubabsch" 1 "Schubabschaltung" ;
VAL_ 1420 M10_Druck_err_gem 0 "errechnet" 1 "gemessen" ;
VAL_ 1420 M10_Freigabe_Reku 0 "RekuModus_aus" 1 "Empf_U_Anhebung" 2 "Empf_U_Absenkung" 3 "RekuModus_aktiv" ;
VAL_ 1420 M10_rel_Saugrohrdruck 63 "Fehler_nicht_verf" ;
VAL_ 1420 M10_Fahrbereitschaft 0 "nicht_fahrbereit" 1 "fahrbereit" ;
VAL_ 1420 M10_Hybrid 0 "kein_Hybrid" 1 "Hybrid" ;
VAL_ 1420 M10_EM_aktiv 0 "EM_inaktiv" 1 "EM_aktiv" ;
VAL_ 1420 M10_VM_aktiv 0 "VM_inaktiv" 1 "VM_aktiv" ;
VAL_ 1420 M10_HYB_Bereitlampe 0 "Lampe_aus" 1 "Lampe_ein" ;
VAL_ 1420 M10_HYB_Warnlampe 0 "Lampe_aus" 1 "Lampe_ein" ;
VAL_ 1420 M10_HYB_Fehlerlampe 0 "Lampe_aus" 1 "Lampe_ein" ;
VAL_ 1420 M10_Fehler_HV_Netz 0 "iO" 1 "kein_gen_Betrieb_moegl" ;
VAL_ 1420 M10_EKlKomLeiRed 0 "keine_LeistBegr" 1 "LeistBegr_75" 2 "LeistBegr_50" 3 "LeistBegr_25" ;
VAL_ 1420 M10_Klimadruck 254 "Init" 255 "Fehler" ;
VAL_ 1420 M10_KompAusCode 0 "keine" 1 "Hochdruck_1" 2 "Niederdruck_3" 3 "Aussentemp_8" 4 "MotManagem_12" 5 "HD_Sensor_def_17" 6 "Ueberspg_13" 7 "Unterspg_10" ;
VAL_ 1420 M10_StartStopp_Fahrerwunsch 0 "Init" 1 "Stoppverbot_durch_Fahrer" 2 "Stoppfreigabe_durch_Fahrer" 3 "Stoppanforderung_durch_Fahrer" ;
VAL_ 1420 M10_Akustik 0 "keine_Akustik" 1 "Akustik_1" 2 "Akustik_2" 3 "frei" ;
VAL_ 1420 M10_Text_1_Hybrid 0 "kein_Text" 1 "Text_1" ;
VAL_ 1420 M10_Text_2_Hybrid 0 "kein_Text" 1 "Text_2" ;
VAL_ 1420 M10_Text_3_Hybrid 0 "kein_Text" 1 "Text_3" ;
VAL_ 1420 M10_Text_4_Hybrid 0 "kein_Text" 1 "Text_4" ;
VAL_ 1420 M10_Text_5_Hybrid 0 "kein_Text" 1 "Text_5" ;
VAL_ 1420 M10_Text_6_Hybrid 0 "kein_Text" ;
VAL_ 1420 M10_Text_7_Hybrid 0 "kein_Text" ;
VAL_ 1420 M10_Text_8_Hybrid 0 "kein_Text" ;
VAL_ 1420 M10_ShiftLockLampe 0 "Lampe_aus" 1 "Lampe_ein" ;
VAL_ 1420 MO_Auth_Aufforderung_WFS 0 "Aus" 1 "Ein" ;
VAL_ 1420 M10_BMSInfo_gue 0 "nicht_gueltig_od_alt" 1 "gueltig" ;
VAL_ 1420 M10_VentilationReq 0 "Umluftklappe_nicht_oeffnen" 1 "Umluftklappe_oeffnen" ;
VAL_ 1420 M10_BattFanSpd 15 "Fehler" ;
VAL_ 1423 MO_ITM_Kuehlmittel_Temp 0 "nicht_verbaut" 2 "Fehler" ;
VAL_ 1423 M12_E85_Sensor 13 "nicht_verbaut" 15 "Fehler" ;
VAL_ 1423 M12_SCR_Anz_Motorstarts 14 "Fahrbarkeitseinschraenkung" 15 "keine_Einschraenkung" ;
VAL_ 1423 M12_SCR_Reichweite 32767 "keine_Anzeige" ;
VAL_ 1423 M12_SCR_Warnstufe_1 1 "Warnstufe_1" ;
VAL_ 1423 M12_SCR_Warnstufe_2 1 "Warnstufe_2" ;
VAL_ 1423 M12_SCR_Text 0 "kein_Text" 1 "Warntext_1" 2 "Warntext_2" 3 "Hinweis_Fuellstand" 5 "SysFehler_1" 6 "Sysfehler_2" 7 "Hinweis_SysFehler" ;
VAL_ 1423 M12_Akustik 0 "keine_Akustik" 1 "Akustik_1" 2 "Akustik_2" 3 "Akustik_bei_Hinweis" ;
VAL_ 1423 M12_Luftfilter_Lampe 0 "Lampe_aus" 1 "Lampe_ein" ;
VAL_ 1423 M12_Kraftstofffilter_Wasser 0 "keine_Anzeige" 1 "Abscheidevolumen_erschoepft" ;
VAL_ 1423 M12_SCR_Systemfehler 1 "SCR_Systemfehler_aktiv" ;
VAL_ 1423 M12_SCR_Inducement 0 "Restart_Strategie" 1 "Reduced_Drivability_Strategie" ;
VAL_ 1423 M12_CO2_Faktor 0 "nicht_verbaut" 4095 "Fehler" ;
VAL_ 1423 M12_MKB_MUX 0 "MKB_01" 1 "MKB_02" 2 "MKB_03" 3 "MKB_04" ;
VAL_ 1423 M12_MKB_01 0 "Minus" 1 "A" 2 "B" 3 "C" 4 "D" 5 "E" 6 "F" 7 "G" 8 "H" 9 "I" 10 "J" 11 "K" 12 "L" 13 "M" 14 "N" 15 "O" 16 "P" 17 "Q" 18 "R" 19 "S" 20 "T" 21 "U" 22 "V" 23 "W" 24 "X" 25 "Y" 26 "Z" 27 "Leerzeichen" 28 "Leerzeichen" 29 "Leerzeichen" 30 "Leerzeichen" 31 "Unterstrich" ;
VAL_ 1423 M12_MKB_02 0 "Minus" 1 "A" 2 "B" 3 "C" 4 "D" 5 "E" 6 "F" 7 "G" 8 "H" 9 "I" 10 "J" 11 "K" 12 "L" 13 "M" 14 "N" 15 "O" 16 "P" 17 "Q" 18 "R" 19 "S" 20 "T" 21 "U" 22 "V" 23 "W" 24 "X" 25 "Y" 26 "Z" 27 "Leerzeichen" 28 "Leerzeichen" 29 "Leerzeichen" 30 "Leerzeichen" 31 "Unterstrich" ;
VAL_ 1423 M12_MKB_03 0 "Minus" 1 "A" 2 "B" 3 "C" 4 "D" 5 "E" 6 "F" 7 "G" 8 "H" 9 "I" 10 "J" 11 "K" 12 "L" 13 "M" 14 "N" 15 "O" 16 "P" 17 "Q" 18 "R" 19 "S" 20 "T" 21 "U" 22 "V" 23 "W" 24 "X" 25 "Y" 26 "Z" 27 "Leerzeichen" 28 "Leerzeichen" 29 "Leerzeichen" 30 "Leerzeichen" 31 "Unterstrich" ;
VAL_ 1423 M12_MKB_04 0 "Minus" 1 "A" 2 "B" 3 "C" 4 "D" 5 "E" 6 "F" 7 "G" 8 "H" 9 "I" 10 "J" 11 "K" 12 "L" 13 "M" 14 "N" 15 "O" 16 "P" 17 "Q" 18 "R" 19 "S" 20 "T" 21 "U" 22 "V" 23 "W" 24 "X" 25 "Y" 26 "Z" 27 "Leerzeichen" 28 "Leerzeichen" 29 "Leerzeichen" 30 "Leerzeichen" 31 "Unterstrich" ;
VAL_ 1450 MO_Heizungspumpenansteuerung 14 "Init" 15 "nicht_verbaut" ;
VAL_ 1450 MO_Absperrventil_oeffnen 0 "nicht_verfuegbar" 1 "Ansteuerung_Ventil_zulaessig" 2 "Ventil_oeffnen" 3 "Ventil_schliessen" ;
VAL_ 1450 MO_aktives_Getriebeheizen 0 "kein_Ventil_ansteuern" 1 "Ventil_muss_angesteuert_werden" ;
VAL_ 1450 MO_Getriebe_kuehlen 0 "Ventil_schliessen" 1 "Ventil_oeffnen" ;
VAL_ 1450 MO_Zustand_HWP 0 "HWP_nicht_schaltbar" 1 "HWP_foerdert_nicht" 2 "HWP_foerdert" 3 "reserviert" ;
VAL_ 1450 MO_BKV_Unterdruckwarnung 0 "Unterdruckhaushalt_iO" 1 "Unterdruckhaushalt_niO" ;
VAL_ 1450 MO_StartStopp_Codiert 0 "Start_Stopp_nicht_verbaut" 1 "Start_Stopp_verbaut" ;
VAL_ 1450 MO_Zylinderabschaltung 0 "Vollmotorbetrieb_VMB" 1 "Uebergang_HMB_in_VMB" 2 "Uebergang_VMB_in_HMB" 3 "Halbmotorbetrieb_HMB" ;
VAL_ 1450 MO_Heizstrom_SCR 63 "Fehler" ;
VAL_ 1450 MO_Heizstrom_EKAT 127 "Fehler" ;
VAL_ 1450 MO_Ext_E_Fahrt_aktiv 0 "Rueckmeldung_E_Taster_aus" 1 "Rueckmeldung_E_Taster_ein" ;
VAL_ 1450 MO_E85_WU_Lampe 0 "Aus" 1 "Ein" ;
VAL_ 1450 MO_E85_WU_Texte 0 "kein_Text" 1 "Anzeige_WU_Text" ;
VAL_ 1450 MO_Zylabsch_Texte 0 "kein_Text" 1 "Zylinderabsch_deakt" 2 "Zylinderabsch_aktiv" 3 "Zylinderabsch_unruhig" ;
VAL_ 1450 MO_E85_BS_Texte 0 "kein_Text" 1 "Flexfuel_Warnung_1" 2 "Flexfuel_Warnung_2" 3 "Flexfuel_Warnung_4" ;
VAL_ 1407 MO_Charisma_FahrPr 0 "nicht_belegt" 1 "Programm_1" 2 "Programm_2" 3 "Programm_3" 4 "Programm_4" 5 "Programm_5" 6 "Programm_6" 7 "Programm_7" ;
VAL_ 1407 MO_Charisma_Status 0 "Init" 1 "verfuegbar" 2 "nicht_verfuegbar" 3 "asynchron_durch_Fahrerwunsch" ;
VAL_ 1407 GE_Charisma_FahrPr 0 "nicht_belegt" 1 "Programm_1" 2 "Programm_2" 3 "Programm_3" 4 "Programm_4" 5 "Programm_5" 6 "Programm_6" 7 "Programm_7" ;
VAL_ 1407 GE_Charisma_Status 0 "Init" 1 "verfuegbar" 2 "nicht_verfuegbar" 3 "asynchron_durch_Fahrerwunsch" ;
VAL_ 1407 MO_Bremslicht_Reku 0 "Aus" 1 "Ein" ;
VAL_ 1407 MO_UeberlVerb_EM 0 "kein_Ueberlauf" 1 "mindestens_einmal_uebergelaufen" ;
VAL_ 1407 MO_UeberlReku_EM 0 "kein_Ueberlauf" 1 "mindestens_einmal_uebergelaufen" ;
VAL_ 1407 MO_UeberlVerb_NA 0 "kein_Ueberlauf" 1 "mindestens_einmal_uebergelaufen" ;
VAL_ 648 MO2_CAN_Vers 17 "V411c_421b_521_531_541_551" 18 "V423a" 19 "V424b" 21 "V423d" 22 "V424e" 26 "V436" 27 "V503c_513" 37 "V456" 39 "V466a" 41 "V473a" 44 "V476c" 47 "V493" 48 "V494a_504" 50 "V496a_506" 53 "V514a_524_534_544" 54 "V516a_526_536_546_556" ;
VAL_ 648 MO2_Getr_Code 0 "_5HP19" 1 "_5HP24" 2 "AG4" 3 "VL300" 4 "VQ250" 5 "VQ35" 6 "AG4_Jatco" 7 "AG5_Jatco" 8 "autom_Kupplung" 9 "autom_Kupplung_mit_ASG" 10 "AG6_Jatco_ZF_6HP_AISIN" 11 "DQ500_DQ250_DQ200" 12 "SQ200" 14 "AL1000_AL551_ZF8HPx" 15 "Handschalter_konv" 16 "DL800" ;
VAL_ 648 MO2_Mp_Code 0 "CAN_Stand" 1 "Motor_Kod" 2 "Getriebe_Kod" 3 "MDI_Max" ;
VAL_ 648 MO2_Kuehlm_T 0 "Init" 255 "Fehler" ;
VAL_ 648 MO2_BLS 0 "kein_Bremsen" 1 "Bremse_betaetigt" ;
VAL_ 648 MO2_BTS 0 "kein_Bremsen" 1 "Bremse_betaetigt" ;
VAL_ 648 MO2_Sta_Kuehlm 0 "Temperatur_iO" 1 "Temperatur_n_iO" ;
VAL_ 648 MO2_Sta_Klima 0 "Klima_aus" 1 "Klima_ein" ;
VAL_ 648 MO2_Sta_No_Bet 0 "kein_Normalbetrieb" 1 "Normalbetrieb" ;
VAL_ 648 MO2_Status_TSK 0 "TSK_nicht_verfuegbar" 1 "TSK_verfuegbar" ;
VAL_ 648 MO2_Sta_GRA 0 "ADR_GRA_aus" 1 "aktiviert_Lampe_an" 2 "uebersteuert_Lampe_an" 3 "ADR_nicht_freigegeben" ;
VAL_ 648 MO2_Sta_Limiter 0 "Lim_nicht_ausgew" 1 "Lim_ausgew_aktiv" 2 "Lim_ausgew_passiv" 3 "Fehler" ;
VAL_ 648 MO2_GRAregelt 0 "nein" 1 "ja" ;
VAL_ 648 MO2_Sport_Error 0 "kein_Fehler" 1 "Fehler" ;
VAL_ 648 MO2_OffRoad 0 "nicht_aktiv" 1 "aktiv" ;
VAL_ 648 MO2_RME_Gehalt 7 "Fehler" ;
VAL_ 648 MO2_GRA_Soll 255 "Fehler" ;
VAL_ 648 MO2_LL_Solldz 255 "Fehler" ;
VAL_ 648 MO2_Begr_Mo 255 "Fehler" ;
VAL_ 648 MO2_Mo_ZWR 255 "Fehler" ;
VAL_ 896 MO3_Vorgluehen 0 "kein_Vorgluehen" 1 "Vorgluehen_aktiv" ;
VAL_ 896 MO3_Prio_Dz 0 "Wunsch" 1 "Zwang" ;
VAL_ 896 MO_Schalter_StartStopp 0 "StartStopp_ueber_Hauptschalter_deaktiviert" 1 "StartStopp_ueber_Hauptschalter_aktiviert" ;
VAL_ 896 MO3_Winterprg 0 "nicht_aktiv" 1 "aktiv" ;
VAL_ 896 MO3_Sta_Pedal 0 "Fahrpedal_iO" 1 "Ersatzwert" ;
VAL_ 896 MO3_Sta_FPG 0 "Gradient_nicht_bed" 1 "Gradient_bed" ;
VAL_ 896 MO3_Sign_FPG 0 "positives_Vorzeichen" 1 "negatives_Vorzeichen" ;
VAL_ 896 MO3_Sta_Temp 0 "Geber_iO" 1 "Ersatzwert" ;
VAL_ 896 MO3_Aussentemp 255 "Fehler" ;
VAL_ 896 MO3_Pedalwert 255 "Fehler" ;
VAL_ 896 MO3_Rad_Wu_Mo 4095 "Fehler" ;
VAL_ 896 MO3_Vorz_RadWu 0 "positives_Vorzeichen" 1 "negatives_Vorzeichen" ;
VAL_ 896 MO3_Freigabe_Segeln 0 "Segelbetrieb_nicht_freigegeben" 1 "Segelbetrieb_freigegeben" ;
VAL_ 896 MO3_WunschDz 255 "Fehler" ;
VAL_ 896 MO3_DKW 255 "Fehler" ;
VAL_ 896 MO3_FPGradient 255 "Fehler" ;
VAL_ 1152 MO5_Abgastyp 0 "kein_EOBD" 1 "EOBD" ;
VAL_ 1152 MO5_Abgastyp2 0 "kein_OBD" 1 "OBD" ;
VAL_ 1152 MO5_Abgastyp3 0 "kein_DPF_verbaut" 1 "DPF_verbaut" ;
VAL_ 1152 OBD_Kaltstart_Denominator 0 "Denominator_nicht_hochzaehlen" 1 "Bedingungen_zum_Inkr_des_Kaltstart_Denom_erf" ;
VAL_ 1152 OBD_Minimum_Trip 0 "kein_Min_Normed_Trip" 1 "Min_Normed_Trip" ;
VAL_ 1152 MO5_DPF_reg 0 "DPF_regeneriert_nicht" 1 "DPF_regeneriert" ;
VAL_ 1152 MO5_Mp_Code 0 "Max_Moment" 1 "Drehzahl" 2 "Motor_Typ" 3 "Abgastyp_od_norm_Verbrauch" ;
VAL_ 1152 MO5_Vorgluehen 0 "Lampe_aus" 1 "Lampe_ein" ;
VAL_ 1152 MO5_E_Gas 0 "Lampe_aus" 1 "Lampe_ein" ;
VAL_ 1152 MO5_OBD_2 0 "Lampe_aus" 1 "Lampe_ein" ;
VAL_ 1152 MO5_Heissl 0 "Lampe_aus" 1 "Lampe_ein" ;
VAL_ 1152 MO5_KlimaKompr 0 "keine_Anforderung" 1 "Klimakompr_aus" ;
VAL_ 1152 MO5_Feld_kuehl 0 "nein" 1 "ja" ;
VAL_ 1152 MO5_KliKo_Red 0 "nein" 1 "ja" ;
VAL_ 1152 MO5_UeberlVerb 0 "kein_Ueberlauf" 1 "mindestens_einmal_uebergelaufen" ;
VAL_ 1152 MO5_Luefter 0 "keine_Anforderung" 255 "Fehler" ;
VAL_ 1152 MO5_HLeuchte 0 "keine_Warnung" 1 "Vorwarnung" ;
VAL_ 1152 MO5_PartikelLamp 0 "Lampe_aus" 1 "Lampe_ein" ;
VAL_ 1152 MO5_Sta_BKU 0 "iO_oder_nicht_verbaut" 1 "n_iO" ;
VAL_ 1152 MO5_TypStartSteu 0 "Startersteuerung_BSG_BCM_KessyD1_ZAS" 1 "Startersteuerung_durch_MSG" ;
VAL_ 1152 MO5_TDE_Lampe 0 "Lampe_aus" 1 "Lampe_ein" ;
VAL_ 1152 MO5_TDE_Text 0 "kein_Text" 1 "Textanzeige_nach_ISO" ;
VAL_ 1152 MO5_DZM_Daempf 0 "normale_Daempfung" 1 "dynamische_Daempfung" ;
VAL_ 1152 MO5_Interlock 0 "Interlock_nicht_betaetigt" 1 "Interlock_betaetigt" ;
VAL_ 1152 MO5_Start 0 "Start_nicht_zulaessig" 1 "Startfreigabe" ;
VAL_ 1152 MO5_Anlasser 0 "Anlasser_darf_angesteuert_werden" 1 "Anlasser_ausspuren__Ansteuerung_nicht_moeglich" ;
VAL_ 1152 MO5_GRA_Hauptsch 0 "Aus" 1 "Ein" ;
VAL_ 1152 MO5_Momente 0 "Einfach" 1 "Doppelt" ;
VAL_ 1152 MO5_Motortext1 0 "kein_Text" 1 "Text_1" ;
VAL_ 1152 MO5_Motortext2 0 "kein_Text" 1 "Text_2" ;
VAL_ 1152 MO5_Motortext3 0 "kein_Text" 1 "Text_3" ;
VAL_ 1152 MO5_Motortext4 0 "kein_Text" 1 "Text_4" ;
